VERSION ""

NS_ :

BS_:

BU_: ECM

BO_ 992 VIN: 8 ECM
 SG_ VIN_MSG : 0|2@1+ (1,0) [0|0] "" Vector__XXX
 SG_ VIN_DATA : 15|56@0+ (1,0) [0|0] "" Vector__XXX

BO_ 464 ORC_A1: 8 Vector__XXX
 SG_ DRV_SEATBELT : 16|2@1+ (1,0) [0|0] "" ECM
 SG_ DrvSbltUnFltr : 13|3@1+ (1,0) [0|0] "" ECM

BO_ 466 ORC_A2: 2 Vector__XXX
 SG_ Impact_Tgl : 7|1@1+ (1,0) [0|0] "" ECM
 SG_ IMPACT_X : 15|1@1+ (1,0) [0|0] "" ECM

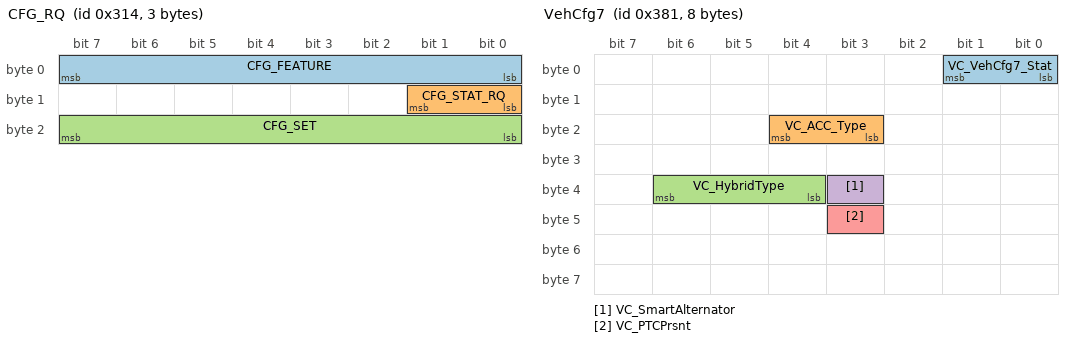
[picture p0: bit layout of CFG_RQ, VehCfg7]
BO_ 788 CFG_RQ: 3 Vector__XXX
 SG_ CFG_FEATURE : 0|8@1+ (1,0) [0|0] "" ECM
 SG_ CFG_STAT_RQ : 8|2@1+ (1,0) [0|0] "" ECM
 SG_ CFG_SET : 16|8@1+ (1,0) [0|255] "" ECM

BO_ 792 StW_Actn_Rq: 8 Vector__XXX
 SG_ WprWash_R_Sw_Posn_V3 : 8|2@1+ (1,0) [0|0] "" ECM

BO_ 850 ECM_APPL2: 8 Vector__XXX
 SG_ ECM_APPL2 : 7|64@0+ (1,0) [0|0] "" ECM

BO_ 864 ECM_APPL1: 8 ECM
 SG_ ECM_APPL1 : 7|64@0+ (1,0) [0|0] "" Vector__XXX

BO_ 880 ECM_APPL3: 8 ECM
 SG_ ECM_APPL3 : 7|64@0+ (1,0) [0|0] "" Vector__XXX

BO_ 896 ECM_APPL4: 8 ECM
 SG_ ECM_APPL4 : 7|64@0+ (1,0) [0|0] "" Vector__XXX

BO_ 897 VehCfg7: 8 Vector__XXX
 SG_ VC_VehCfg7_Stat : 0|2@1+ (1,0) [0|0] "" ECM
 SG_ VC_ACC_Type : 19|2@1+ (1,0) [0|0] "" ECM
 SG_ VC_HybridType : 36|3@1+ (1,0) [0|0] "" ECM
 SG_ VC_SmartAlternator : 35|1@1+ (1,0) [0|0] "" ECM
 SG_ VC_PTCPrsnt : 43|1@1+ (1,0) [0|0] "" ECM

BO_ 912 ECM_APPL5: 8 ECM
 SG_ ECM_APPL5 : 7|64@0+ (1,0) [0|0] "" Vector__XXX

BO_ 928 ECM_APPL6: 8 ECM
 SG_ ECM_APPL6 : 7|64@0+ (1,0) [0|0] "" Vector__XXX

BO_ 936 ECM_APPL7: 8 ECM
 SG_ ECM_APPL7 : 7|64@0+ (1,0) [0|0] "" Vector__XXX

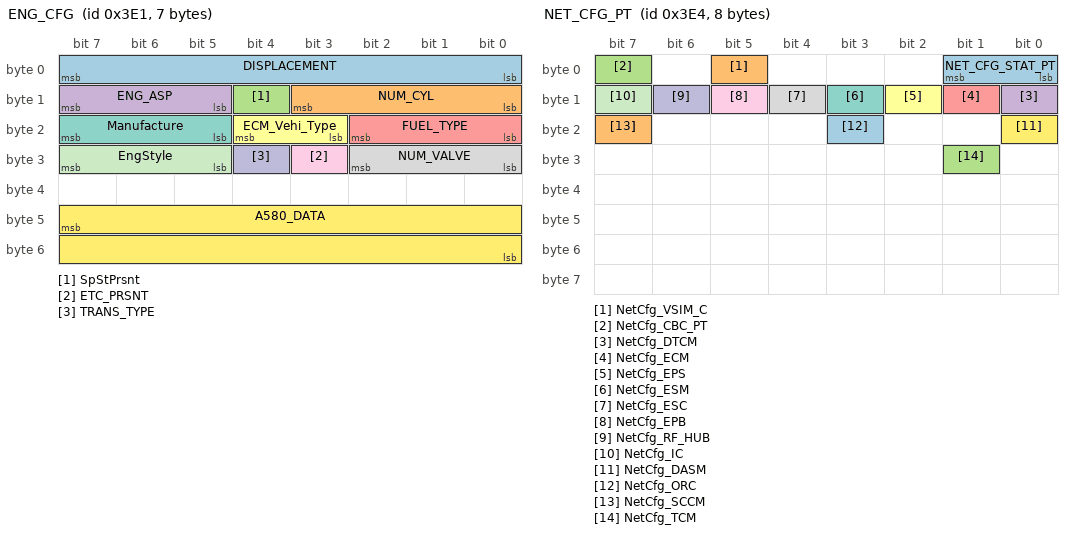
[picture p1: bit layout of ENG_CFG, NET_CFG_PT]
BO_ 993 ENG_CFG: 7 ECM
 SG_ DISPLACEMENT : 0|8@1+ (0.1,0) [0|25] "liters"  Vector__XXX
 SG_ NUM_CYL : 8|4@1+ (1,0) [0|14] "cylinders"  Vector__XXX
 SG_ SpStPrsnt : 12|1@1+ (1,0) [0|0] "" Vector__XXX
 SG_ ENG_ASP : 13|3@1+ (1,0) [0|0] "" Vector__XXX
 SG_ FUEL_TYPE : 16|3@1+ (1,0) [0|0] "" Vector__XXX
 SG_ ECM_Vehi_Type : 19|2@1+ (1,0) [0|0] "" Vector__XXX
 SG_ Manufacture : 21|3@1+ (1,0) [0|0] "" Vector__XXX
 SG_ NUM_VALVE : 24|3@1+ (1,0) [0|6] "valve-per-cylinder"  Vector__XXX
 SG_ ETC_PRSNT : 27|1@1+ (1,0) [0|0] "" Vector__XXX
 SG_ TRANS_TYPE : 28|1@1+ (1,0) [0|0] "" Vector__XXX
 SG_ EngStyle : 29|3@1+ (1,0) [0|0] "" Vector__XXX
 SG_ A580_DATA : 47|16@0+ (1,0) [0|0] "" Vector__XXX

BO_ 995 NET_CFG_INT: 8 Vector__XXX
 SG_ NET_CFG_STAT_INT : 0|2@1+ (1,0) [0|0] "" ECM

BO_ 996 NET_CFG_PT: 8 Vector__XXX
 SG_ NET_CFG_STAT_PT : 0|2@1+ (1,0) [0|0] "" ECM
 SG_ NetCfg_VSIM_C : 5|1@1+ (1,0) [0|0] "" ECM
 SG_ NetCfg_CBC_PT : 7|1@1+ (1,0) [0|0] "" ECM
 SG_ NetCfg_DTCM : 8|1@1+ (1,0) [0|0] "" ECM
 SG_ NetCfg_ECM : 9|1@1+ (1,0) [0|0] "" ECM
 SG_ NetCfg_EPS : 10|1@1+ (1,0) [0|0] "" ECM
 SG_ NetCfg_ESM : 11|1@1+ (1,0) [0|0] "" ECM
 SG_ NetCfg_ESC : 12|1@1+ (1,0) [0|0] "" ECM
 SG_ NetCfg_EPB : 13|1@1+ (1,0) [0|0] "" ECM
 SG_ NetCfg_RF_HUB : 14|1@1+ (1,0) [0|0] "" ECM
 SG_ NetCfg_IC : 15|1@1+ (1,0) [0|0] "" ECM
 SG_ NetCfg_DASM : 16|1@1+ (1,0) [0|0] "" ECM
 SG_ NetCfg_ORC : 19|1@1+ (1,0) [0|0] "" ECM
 SG_ NetCfg_SCCM : 23|1@1+ (1,0) [0|0] "" ECM
 SG_ NetCfg_TCM : 25|1@1+ (1,0) [0|0] "" ECM

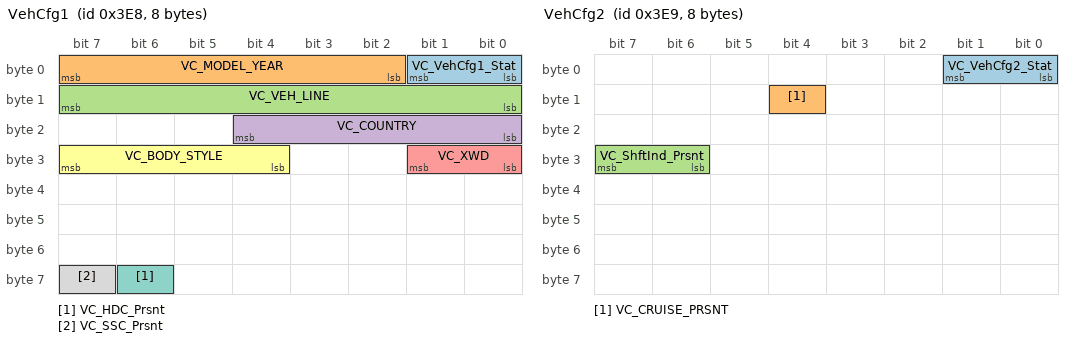
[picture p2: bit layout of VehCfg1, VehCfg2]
BO_ 1000 VehCfg1: 8 Vector__XXX
 SG_ VC_VehCfg1_Stat : 0|2@1+ (1,0) [0|0] "" ECM
 SG_ VC_MODEL_YEAR : 2|6@1+ (1,2000) [2000|2062] "model-year"  ECM
 SG_ VC_VEH_LINE : 8|8@1+ (1,0) [0|0] "" ECM
 SG_ VC_COUNTRY : 16|5@1+ (1,0) [0|0] "" ECM
 SG_ VC_XWD : 24|2@1+ (1,0) [0|0] "" ECM
 SG_ VC_BODY_STYLE : 28|4@1+ (1,0) [0|0] "" ECM
 SG_ VC_HDC_Prsnt : 62|1@1+ (1,0) [0|0] "" ECM
 SG_ VC_SSC_Prsnt : 63|1@1+ (1,0) [0|0] "" ECM

BO_ 1001 VehCfg2: 8 Vector__XXX
 SG_ VC_VehCfg2_Stat : 0|2@1+ (1,0) [0|0] "" ECM
 SG_ VC_CRUISE_PRSNT : 12|1@1+ (1,0) [0|0] "" ECM
 SG_ VC_ShftInd_Prsnt : 30|2@1+ (1,0) [0|0] "" ECM

BO_ 1002 VehCfg3: 8 Vector__XXX
 SG_ VC_VehCfg3_Stat : 0|2@1+ (1,0) [0|0] "" ECM

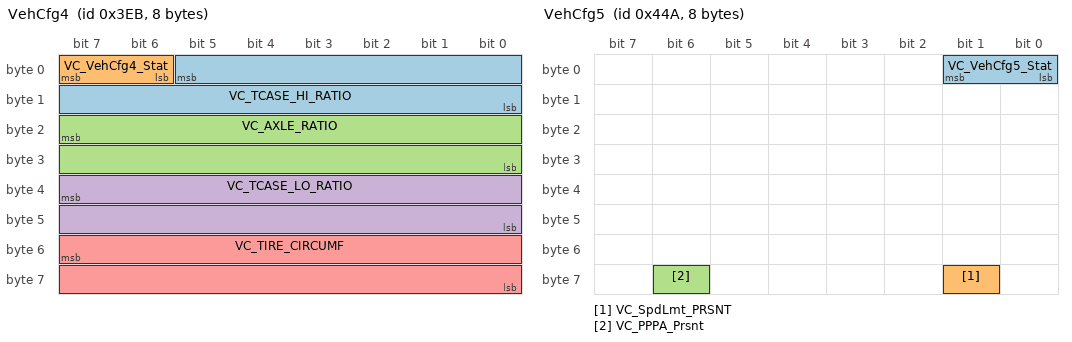
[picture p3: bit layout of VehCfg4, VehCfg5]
BO_ 1003 VehCfg4: 8 Vector__XXX
 SG_ VC_TCASE_HI_RATIO : 5|14@0+ (0.001,0) [0|16.382] "" ECM
 SG_ VC_VehCfg4_Stat : 6|2@1+ (1,0) [0|0] "" ECM
 SG_ VC_AXLE_RATIO : 23|16@0+ (0.001,0) [0|65.534] "" ECM
 SG_ VC_TCASE_LO_RATIO : 39|16@0+ (0.001,0) [0|65.534] "" ECM
 SG_ VC_TIRE_CIRCUMF : 55|16@0+ (1,0) [0|65534] "mm"  ECM

BO_ 1013 EcuCfg6: 8 Vector__XXX
 SG_ EC_ECUCfg6_Stat : 0|2@1+ (1,0) [0|0] "" ECM
 SG_ EC_Powertrain : 39|16@0+ (1,0) [0|0] "" ECM

BO_ 1089 DG_RQ_GLOBAL_UDS: 8 Vector__XXX
 SG_ DG_RQ_GLOBAL_UDS : 7|64@0+ (1,0) [0|0] "" ECM

BO_ 1098 VehCfg5: 8 Vector__XXX
 SG_ VC_VehCfg5_Stat : 0|2@1+ (1,0) [0|0] "" ECM
 SG_ VC_SpdLmt_PRSNT : 57|1@1+ (1,0) [0|0] "" ECM
 SG_ VC_PPPA_Prsnt : 62|1@1+ (1,0) [0|0] "" ECM

BO_ 1100 VehCfg6: 8 Vector__XXX
 SG_ VC_VehCfg6_Stat : 0|2@1+ (1,0) [0|0] "" ECM
 SG_ VC_AnlgDrSnsr : 2|2@1+ (1,0) [0|0] "" ECM

BO_ 1464 ECU_APPL_ECM: 8 ECM
 SG_ ECU_APPL_ECM : 7|64@0+ (1,0) [0|0] "" Vector__XXX

BO_ 1592 SD_RS_ECM: 8 ECM
 SG_ SD_RS_ECM : 7|64@0+ (1,0) [0|0] "" Vector__XXX

BO_ 1784 APPL_ECU_ECM: 8 Vector__XXX
 SG_ APPL_ECU_ECM : 7|64@0+ (1,0) [0|0] "" ECM

BO_ 2015 DG_RQ_GLOBAL: 8 Vector__XXX
 SG_ DG_RQ_GLOBAL : 7|64@0+ (1,0) [0|0] "" ECM

BO_ 2016 D_RQ_ECM: 8 Vector__XXX
 SG_ D_RQ_ECM : 7|64@0+ (1,0) [0|0] "" ECM

BO_ 2024 D_RS_ECM: 8 ECM
 SG_ D_RS_ECM : 7|64@0+ (1,0) [0|0] "" Vector__XXX

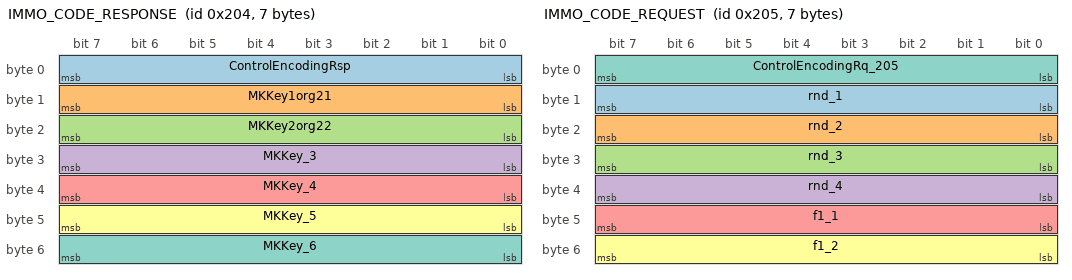
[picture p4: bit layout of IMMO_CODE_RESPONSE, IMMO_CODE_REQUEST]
BO_ 516 IMMO_CODE_RESPONSE: 7 Vector__XXX
 SG_ ControlEncodingRsp : 0|8@1+ (1,0) [0|0] "" ECM
 SG_ MKKey1org21 : 8|8@1+ (1,0) [0|255] "" ECM
 SG_ MKKey2org22 : 16|8@1+ (1,0) [0|255] "" ECM
 SG_ MKKey_3 : 24|8@1+ (1,0) [0|255] "" ECM
 SG_ MKKey_4 : 32|8@1+ (1,0) [0|255] "" ECM
 SG_ MKKey_5 : 40|8@1+ (1,0) [0|255] "" ECM
 SG_ MKKey_6 : 48|8@1+ (1,0) [0|255] "" ECM

BO_ 517 IMMO_CODE_REQUEST: 7 ECM
 SG_ rnd_1 : 8|8@1+ (1,0) [0|255] "" Vector__XXX
 SG_ rnd_2 : 16|8@1+ (1,0) [0|255] "" Vector__XXX
 SG_ rnd_3 : 24|8@1+ (1,0) [0|255] "" Vector__XXX
 SG_ rnd_4 : 32|8@1+ (1,0) [0|255] "" Vector__XXX
 SG_ f1_1 : 40|8@1+ (1,0) [0|255] "" Vector__XXX
 SG_ f1_2 : 48|8@1+ (1,0) [0|255] "" Vector__XXX
 SG_ ControlEncodingRq_205 : 0|8@1+ (1,0) [0|0] "" Vector__XXX

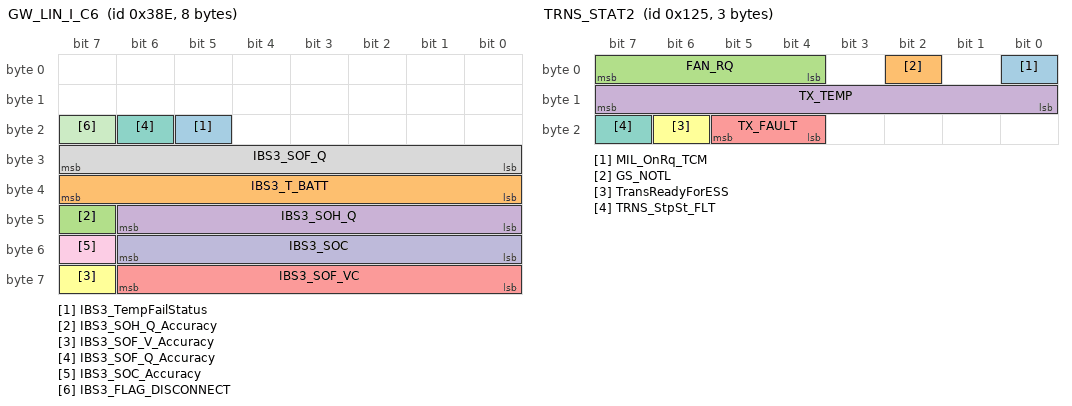
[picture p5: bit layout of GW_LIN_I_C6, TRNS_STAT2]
BO_ 910 GW_LIN_I_C6: 8 Vector__XXX
 SG_ IBS3_TempFailStatus : 21|1@1+ (1,0) [0|0] "" ECM
 SG_ IBS3_T_BATT : 32|8@1+ (1,-40) [-40|105] "°C"  ECM
 SG_ IBS3_SOH_Q_Accuracy : 47|1@1+ (1,0) [0|0] "" ECM
 SG_ IBS3_SOH_Q : 40|7@1+ (2,0) [0|252] "Ah"  ECM
 SG_ IBS3_SOF_VC : 56|7@1+ (0.05,5) [5|11.3] "V"  ECM
 SG_ IBS3_SOF_V_Accuracy : 63|1@1+ (1,0) [0|0] "" ECM
 SG_ IBS3_SOF_Q_Accuracy : 22|1@1+ (1,0) [0|0] "" ECM
 SG_ IBS3_SOF_Q : 24|8@1+ (1,0) [0|254] "Ah"  ECM
 SG_ IBS3_SOC_Accuracy : 55|1@1+ (1,0) [0|0] "" ECM
 SG_ IBS3_SOC : 48|7@1+ (1,0) [0|100] "%"  ECM
 SG_ IBS3_FLAG_DISCONNECT : 23|1@1+ (1,0) [0|0] "" ECM

BO_ 976 ECM_A4: 8 ECM
 SG_ PF_WARN_MSG : 24|3@1+ (1,0) [0|0] "" Vector__XXX
 SG_ KNK_MG_TRIGGER : 29|2@1+ (1,0) [0|0] "" Vector__XXX

BO_ 47 WHEEL_SPEED_2: 8 Vector__XXX
 SG_ BrkPdlRawStat : 33|10@0+ (0.0048828125,0) [0|4.9951171875] "Volts"  ECM
 SG_ RAW_OBD_VEHACCEL_X : 48|8@1+ (0.08,-10.24) [-10.24|10.16] "m/s²"  ECM

BO_ 293 TRNS_STAT2: 3 Vector__XXX
 SG_ MIL_OnRq_TCM : 0|1@1+ (1,0) [0|0] "" ECM
 SG_ GS_NOTL : 2|1@1+ (1,0) [0|0] "" ECM
 SG_ FAN_RQ : 4|4@1+ (7.2,0) [0|100] "%"  ECM
 SG_ TX_TEMP : 8|8@1+ (1,-50) [-50|204] "°C"  ECM
 SG_ TX_FAULT : 20|2@1+ (1,0) [0|0] "" ECM
 SG_ TransReadyForESS : 22|1@1+ (1,0) [0|0] "" ECM
 SG_ TRNS_StpSt_FLT : 23|1@1+ (1,0) [0|0] "" ECM

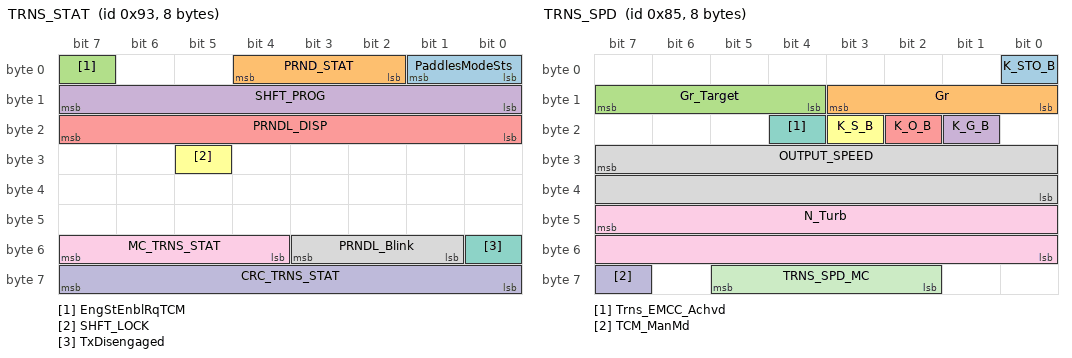
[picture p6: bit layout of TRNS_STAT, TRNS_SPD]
BO_ 147 TRNS_STAT: 8 Vector__XXX
 SG_ PaddlesModeSts : 0|2@1+ (1,0) [0|0] "" Vector__XXX
 SG_ PRND_STAT : 2|3@1+ (1,0) [0|0] "" ECM
 SG_ EngStEnblRqTCM : 7|1@1+ (1,0) [0|0] "" ECM
 SG_ SHFT_PROG : 8|8@1+ (1,0) [0|0] "" ECM
 SG_ PRNDL_DISP : 16|8@1+ (1,0) [0|0] "" ECM
 SG_ SHFT_LOCK : 29|1@1+ (1,0) [0|0] "" Vector__XXX
 SG_ TxDisengaged : 48|1@1+ (1,0) [0|0] "" ECM
 SG_ PRNDL_Blink : 49|3@1+ (1,0) [0|0] "" Vector__XXX
 SG_ MC_TRNS_STAT : 52|4@1+ (1,0) [0|15] "" ECM
 SG_ CRC_TRNS_STAT : 56|8@1+ (1,0) [0|0] "" ECM

BO_ 133 TRNS_SPD: 8 Vector__XXX
 SG_ K_STO_B : 0|1@1+ (1,0) [0|0] "" ECM
 SG_ Gr : 8|4@1+ (1,0) [0|0] "" ECM
 SG_ Gr_Target : 12|4@1+ (1,0) [0|0] "" ECM
 SG_ K_G_B : 17|1@1+ (1,0) [0|0] "" ECM
 SG_ K_O_B : 18|1@1+ (1,0) [0|0] "" ECM
 SG_ K_S_B : 19|1@1+ (1,0) [0|0] "" ECM
 SG_ Trns_EMCC_Achvd : 20|1@1+ (1,0) [0|0] "" ECM
 SG_ OUTPUT_SPEED : 31|16@0+ (1,0) [0|65534] "rpm"  ECM
 SG_ N_Turb : 47|16@0+ (1,0) [0|65534] "rpm"  ECM
 SG_ TCM_ManMd : 63|1@1+ (1,0) [0|0] "" ECM
 SG_ TRNS_SPD_MC : 58|4@1+ (1,0) [0|15] "" ECM

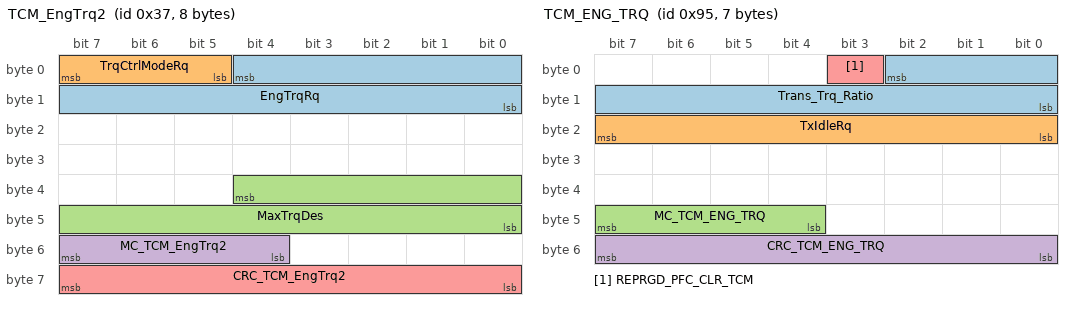
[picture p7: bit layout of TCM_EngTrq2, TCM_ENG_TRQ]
BO_ 55 TCM_EngTrq2: 8 Vector__XXX
 SG_ EngTrqRq : 4|13@0+ (0.25,-500) [-500|1547.5] "Nm"  ECM
 SG_ TrqCtrlModeRq : 5|3@1+ (1,0) [0|0] "" ECM
 SG_ MaxTrqDes : 36|13@0+ (0.25,-500) [-500|1547.5] "Nm"  ECM
 SG_ MC_TCM_EngTrq2 : 52|4@1+ (1,0) [0|15] "" ECM
 SG_ CRC_TCM_EngTrq2 : 56|8@1+ (1,0) [0|0] "" ECM

BO_ 149 TCM_ENG_TRQ: 7 Vector__XXX
 SG_ Trans_Trq_Ratio : 2|11@0+ (0.01,0) [0|20.46] "" ECM
 SG_ TxIdleRq : 16|8@1+ (4,500) [500|1516] "rpm"  ECM
 SG_ MC_TCM_ENG_TRQ : 44|4@1+ (1,0) [0|15] "" ECM
 SG_ CRC_TCM_ENG_TRQ : 48|8@1+ (1,0) [0|0] "" ECM
 SG_ REPRGD_PFC_CLR_TCM : 3|1@1+ (1,0) [0|0] "" ECM

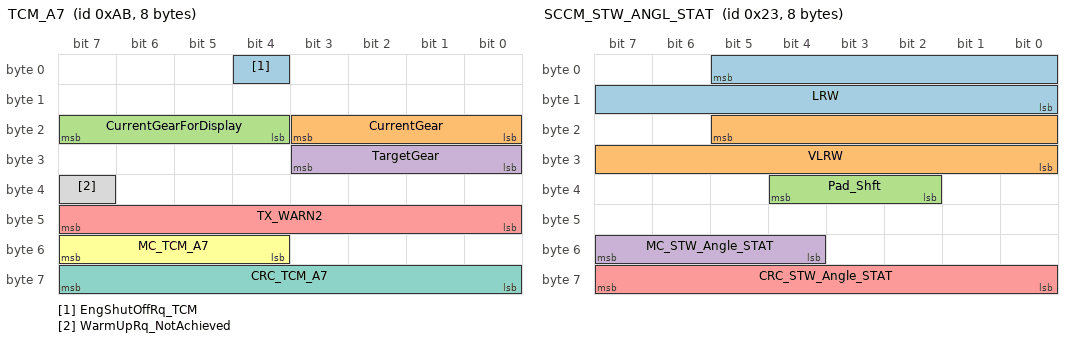
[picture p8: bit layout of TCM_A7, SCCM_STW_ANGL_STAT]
BO_ 171 TCM_A7: 8 Vector__XXX
 SG_ EngShutOffRq_TCM : 4|1@1+ (1,0) [0|0] "" ECM
 SG_ CurrentGear : 16|4@1+ (1,0) [0|0] "" ECM
 SG_ CurrentGearForDisplay : 20|4@1+ (1,0) [0|0] "" Vector__XXX
 SG_ TargetGear : 24|4@1+ (1,0) [0|0] "" ECM
 SG_ TX_WARN2 : 40|8@1+ (1,0) [0|0] "" Vector__XXX
 SG_ MC_TCM_A7 : 52|4@1+ (1,0) [0|15] "" ECM
 SG_ CRC_TCM_A7 : 56|8@1+ (1,0) [0|0] "" ECM
 SG_ WarmUpRq_NotAchieved : 39|1@1+ (1,0) [0|0] "" ECM

BO_ 35 SCCM_STW_ANGL_STAT: 8 Vector__XXX
 SG_ LRW : 5|14@0+ (0.5,-2048) [-2048|2047] "Degrees"  ECM
 SG_ VLRW : 21|14@0+ (0.5,-2048) [-2048|2047] "°/s"  ECM
 SG_ Pad_Shft : 34|3@1+ (1,0) [0|0] "" ECM
 SG_ MC_STW_Angle_STAT : 52|4@1+ (1,0) [0|15] "" ECM
 SG_ CRC_STW_Angle_STAT : 56|8@1+ (1,0) [0|0] "" ECM

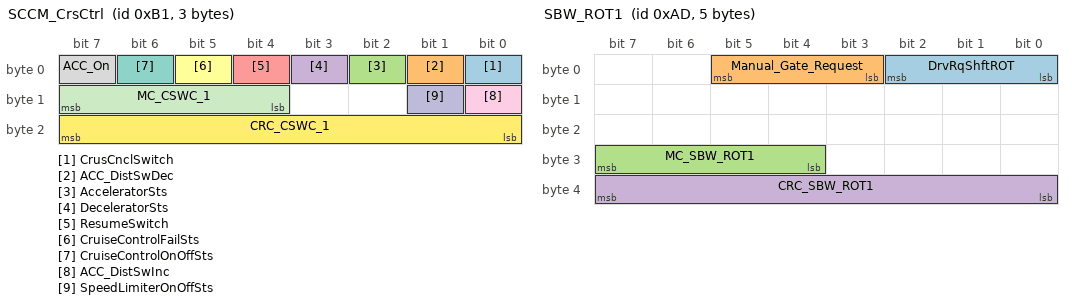
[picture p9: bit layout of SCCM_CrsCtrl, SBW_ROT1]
BO_ 177 SCCM_CrsCtrl: 3 Vector__XXX
 SG_ CrusCnclSwitch : 0|1@1+ (1,0) [0|0] "" ECM
 SG_ ACC_DistSwDec : 1|1@1+ (1,0) [0|0] "" ECM
 SG_ AcceleratorSts : 2|1@1+ (1,0) [0|0] "" ECM
 SG_ DeceleratorSts : 3|1@1+ (1,0) [0|0] "" ECM
 SG_ ResumeSwitch : 4|1@1+ (1,0) [0|0] "" ECM
 SG_ CruiseControlFailSts : 5|1@1+ (1,0) [0|0] "" ECM
 SG_ CruiseControlOnOffSts : 6|1@1+ (1,0) [0|0] "" ECM
 SG_ ACC_On : 7|1@1+ (1,0) [0|0] "" ECM
 SG_ ACC_DistSwInc : 8|1@1+ (1,0) [0|0] "" ECM
 SG_ SpeedLimiterOnOffSts : 9|1@1+ (1,0) [0|0] "" ECM
 SG_ MC_CSWC_1 : 12|4@1+ (1,0) [0|15] "" ECM
 SG_ CRC_CSWC_1 : 16|8@1+ (1,0) [0|0] "" ECM

BO_ 173 SBW_ROT1: 5 Vector__XXX
 SG_ DrvRqShftROT : 0|3@1+ (1,0) [0|0] "" ECM
 SG_ Manual_Gate_Request : 3|3@1+ (1,0) [0|0] "" ECM
 SG_ MC_SBW_ROT1 : 28|4@1+ (1,0) [0|15] "" ECM
 SG_ CRC_SBW_ROT1 : 32|8@1+ (1,0) [0|0] "" ECM

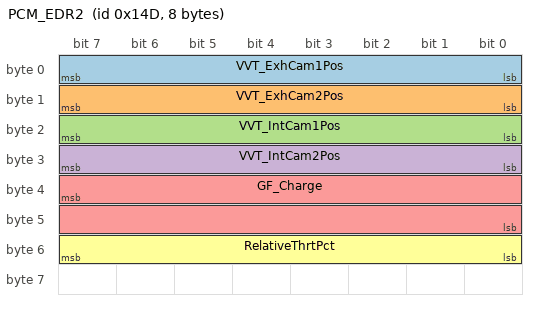
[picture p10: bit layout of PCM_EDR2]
BO_ 333 PCM_EDR2: 8 ECM
 SG_ VVT_ExhCam1Pos : 0|8@1+ (1,0) [1|255] "Degrees"  Vector__XXX
 SG_ VVT_ExhCam2Pos : 8|8@1+ (1,0) [1|255] "Degrees"  Vector__XXX
 SG_ VVT_IntCam1Pos : 16|8@1+ (1,0) [1|255] "Degrees"  Vector__XXX
 SG_ VVT_IntCam2Pos : 24|8@1+ (1,0) [1|255] "Degrees"  Vector__XXX
 SG_ GF_Charge : 39|16@0+ (0.2,0) [0|13106.8] "mg/cycle/cyl"  Vector__XXX
 SG_ RelativeThrtPct : 48|8@1+ (0.4,0) [0|100] "%"  Vector__XXX

CM_ "Excel Convert to DBC - Written by Vector CANtech, Inc. 2016";
CM_ SG_ 2016 D_RQ_ECM "Diagnostic-Request";
CM_ SG_ 2015 DG_RQ_GLOBAL "Diagnostic-Request";
CM_ SG_ 1784 APPL_ECU_ECM "External Application to ECU";
CM_ SG_ 1100 VC_AnlgDrSnsr "Analog door sensor configuration";
CM_ SG_ 1100 VC_VehCfg6_Stat "Configuration messages status 6";
CM_ SG_ 1098 VC_PPPA_Prsnt "Semi automatic parking system present; present = [1]";
CM_ SG_ 1098 VC_SpdLmt_PRSNT "Speed limiter is present; present = [1]";
CM_ SG_ 1098 VC_VehCfg5_Stat "Configuration messages status 5";
CM_ SG_ 1089 DG_RQ_GLOBAL_UDS "Diagnostic-Request";
CM_ SG_ 1013 EC_Powertrain "Powertrain ecu configuration";
CM_ SG_ 1013 EC_ECUCfg6_Stat "ECU Configuration messages status 6";
CM_ SG_ 1003 VC_TIRE_CIRCUMF "Dynamic tire circumference (all or rear)";
CM_ SG_ 1003 VC_TCASE_LO_RATIO "Transfer case low range reduction ratio";
CM_ SG_ 1003 VC_AXLE_RATIO "Axle ratio";
CM_ SG_ 1003 VC_VehCfg4_Stat "Configuration messages status 4";
CM_ SG_ 1003 VC_TCASE_HI_RATIO "Transfer case high ratio";
CM_ SG_ 1002 VC_VehCfg3_Stat "Configuration messages status 3";
CM_ SG_ 1001 VC_ShftInd_Prsnt "Configuration for performance & gear shift indication";
CM_ SG_ 1001 VC_CRUISE_PRSNT "Cruise feature is present; present = [1]";
CM_ SG_ 1001 VC_VehCfg2_Stat "Configuration messages status 2";
CM_ SG_ 1000 VC_SSC_Prsnt "Select speed control feature is present; present = [1]";
CM_ SG_ 1000 VC_HDC_Prsnt "Hill descent feature is present; present = [1]";
CM_ SG_ 1000 VC_BODY_STYLE "Body style";
CM_ SG_ 1000 VC_XWD "Drive configuration";
CM_ SG_ 1000 VC_COUNTRY "Country Code";
CM_ SG_ 1000 VC_VEH_LINE "Vehicle line";
CM_ SG_ 1000 VC_MODEL_YEAR "Model year";
CM_ SG_ 1000 VC_VehCfg1_Stat "Configuration messages status 1";
CM_ SG_ 996 NetCfg_DASM "Driver Assistance System Module (1=present)";
CM_ SG_ 996 NetCfg_IC "Instrument Cluster (1=present)";
CM_ SG_ 996 NetCfg_RF_HUB "RF Hub Node (1=present)";
CM_ SG_ 996 NetCfg_EPB "Electric Park Brake Module (1=present)";
CM_ SG_ 996 NetCfg_ESC "Electronic Stability Module / Anti-Lock Brake (1=present)";
CM_ SG_ 996 NetCfg_ESM "Electronic Shift Module (1=present)";
CM_ SG_ 996 NetCfg_TCM "Automatic Transmission Controller (1=present)";
CM_ SG_ 996 NetCfg_SCCM "Steering Column Control Module (1=present)";
CM_ SG_ 996 NetCfg_ORC "Occupant Restraint Controller (1=present)";
CM_ SG_ 996 NetCfg_EPS "Electric Power Steering (1=present)";
CM_ SG_ 996 NetCfg_ECM "Engine Control Module (1=present)";
CM_ SG_ 996 NetCfg_DTCM "Drivetrain Control Module (1=present)";
CM_ SG_ 996 NetCfg_CBC_PT "Common Body Controller PT Bus (1=present)";
CM_ SG_ 996 NetCfg_VSIM_C "Vehicle System Interface Module (1=present)";
CM_ SG_ 996 NET_CFG_STAT_PT "Network configuration status";
CM_ SG_ 995 NET_CFG_STAT_INT "Network configuration status";
CM_ SG_ 910 IBS3_FLAG_DISCONNECT "Battery disconnection flag";
CM_ SG_ 910 IBS3_SOC "State of charge";
CM_ SG_ 910 IBS3_SOC_Accuracy "SOC accuracy status";
CM_ SG_ 910 IBS3_SOF_Q "Residual battery charge in Ah";
CM_ SG_ 910 IBS3_SOF_Q_Accuracy "SOF_Q accuracy status";
CM_ SG_ 910 IBS3_SOF_V_Accuracy "SOF_V accuracy; Data reliable = [0], unreliable = [1]";
CM_ SG_ 910 IBS3_SOF_VC "Predicted initial battery voltage dip during cranking (old CG spec)";
CM_ SG_ 910 IBS3_SOH_Q "State of health related to capacity (energy)";
CM_ SG_ 910 IBS3_SOH_Q_Accuracy "SOH_Q accuracy status";
CM_ SG_ 910 IBS3_T_BATT "Battery temperature";
CM_ SG_ 910 IBS3_TempFailStatus "Failure of ASIC Temperature meas. (internal defect)";
CM_ SG_ 897 VC_PTCPrsnt "PTC Present/Absent;  Present = 1";
CM_ SG_ 897 VC_SmartAlternator "Smart alternator is present; True = [1]";
CM_ SG_ 897 VC_HybridType "Identify the kind of hybrid vehicle";
CM_ SG_ 897 VC_ACC_Type "Type of adaptive cruise control (ACC) system present";
CM_ SG_ 897 VC_VehCfg7_Stat "Configuration messages status 7";
CM_ SG_ 850 ECM_APPL2 "Application";
CM_ SG_ 792 WprWash_R_Sw_Posn_V3 "Backlite wiper/washer switch position";
CM_ SG_ 788 CFG_SET "Specific setting or value (see reference)";
CM_ SG_ 788 CFG_STAT_RQ "Configurable feature status request";
CM_ SG_ 788 CFG_FEATURE "Configurable feature";
CM_ SG_ 516 MKKey2org22 "Mini kript key 2 or G2_2";
CM_ SG_ 516 MKKey1org21 "Mini kript key 1 or G2_1";
CM_ SG_ 516 ControlEncodingRsp "Control encoding - response";
CM_ SG_ 516 MKKey_6 "Mini kript key 6";
CM_ SG_ 516 MKKey_5 "Mini kript key 5";
CM_ SG_ 516 MKKey_4 "Mini kript key 4";
CM_ SG_ 516 MKKey_3 "Mini kript key 3";
CM_ SG_ 466 IMPACT_X "Any impact event; actuate = [1]; do_not_actuate = [0]";
CM_ SG_ 466 Impact_Tgl "Toggle bit for all impact events; See Signal Description Document";
CM_ SG_ 464 DrvSbltUnFltr "Drivers seat belt fault status - unfiltered";
CM_ SG_ 464 DRV_SEATBELT "Drivers seat belt status";
CM_ SG_ 293 TRNS_StpSt_FLT "Trans stop start fault (1=fault)";
CM_ SG_ 293 TransReadyForESS "Trans ready for auto stop (0= not ready)";
CM_ SG_ 293 TX_FAULT "Transmission fault";
CM_ SG_ 293 TX_TEMP "Transmission fluid temperature";
CM_ SG_ 293 FAN_RQ "Cooling fan request";
CM_ SG_ 293 GS_NOTL "TRANS in limp home mode";
CM_ SG_ 293 MIL_OnRq_TCM "MIL on request from the transmission";
CM_ SG_ 177 CRC_CSWC_1 "CRC-checksum byte 1 to 2 according to SAE J1850";
CM_ SG_ 177 MC_CSWC_1 "Message counter";
CM_ SG_ 177 SpeedLimiterOnOffSts "Cruise Switch:Speed Limiter On/Off Pressed";
CM_ SG_ 177 ACC_DistSwInc "Cruise Switch: Distance Increase pressed";
CM_ SG_ 177 ACC_On "Cruise Switch: ACC or ESC mode pressed";
CM_ SG_ 177 CruiseControlOnOffSts "Cruise Switch: On/Off  Pressed";
CM_ SG_ 177 CruiseControlFailSts "Cruise Switch: Implausible State=1";
CM_ SG_ 177 ResumeSwitch "Cruise Switch: Resume Pressed";
CM_ SG_ 177 DeceleratorSts "Cruise Switch: Coast or Set/Decel Pressed";
CM_ SG_ 177 AcceleratorSts "Cruise Switch: Set/Accel Pressed";
CM_ SG_ 177 ACC_DistSwDec "Cruise Switch: Distance Decrease pressed";
CM_ SG_ 177 CrusCnclSwitch "Cruise Switch: Cancel Pressed";
CM_ SG_ 173 CRC_SBW_ROT1 "CRC-checksum byte 1 to 4 according to SAE J1850";
CM_ SG_ 173 MC_SBW_ROT1 "Message counter";
CM_ SG_ 173 Manual_Gate_Request "Manual gate request";
CM_ SG_ 173 DrvRqShftROT "Driver requested gear shift position";
CM_ SG_ 149 REPRGD_PFC_CLR_TCM "Set readiness to 'incomplete'; 0 = Do nothing; 1= Set incomplete";
CM_ SG_ 149 CRC_TCM_ENG_TRQ "CRC-checksum byte 1 to 6 according to SAE J1850";
CM_ SG_ 149 MC_TCM_ENG_TRQ "Message counter";
CM_ SG_ 149 TxIdleRq "Transmission idle speed request";
CM_ SG_ 149 Trans_Trq_Ratio "Transmission torque ratio";
CM_ SG_ 133 TRNS_SPD_MC "TRNS_SPD message counter";
CM_ SG_ 133 TCM_ManMd "Transmission in manual mode";
CM_ SG_ 133 N_Turb "Unfiltered turbine speed (n_t_v)";
CM_ SG_ 133 OUTPUT_SPEED "Output Shaft Speed";
CM_ SG_ 133 Trns_EMCC_Achvd "Trans A/C Converter Clutch Slipping; [1] = True";
CM_ SG_ 133 K_S_B "Conf. (torque converter lock-up) clutch 'slip'";
CM_ SG_ 133 K_O_B "Conf. (torque converter lock-up) clutch 'open'";
CM_ SG_ 133 K_G_B "Conf. (torque converter lock-up) clutch 'closed'";
CM_ SG_ 133 Gr_Target "Target Gear";
CM_ SG_ 133 Gr "Current Gear";
CM_ SG_ 133 K_STO_B "Conf. (torque converter lock-up) clutch 'starts to open'";
CM_ SG_ 55 CRC_TCM_EngTrq2 "CRC-checksum byte 1 to 7 according to SAE J1850";
CM_ SG_ 55 MC_TCM_EngTrq2 "Message counter";
CM_ SG_ 55 MaxTrqDes "Maximum engine torque desired";
CM_ SG_ 55 TrqCtrlModeRq "Torque control mode request";
CM_ SG_ 55 EngTrqRq "Requested engine torque";
CM_ SG_ 47 RAW_OBD_VEHACCEL_X "Raw vehicle acceleration in the X direction";
CM_ SG_ 47 BrkPdlRawStat "Brake pedal state raw value";
CM_ SG_ 35 CRC_STW_Angle_STAT "CRC-checksum byte 1 to 7 according to SAE J1850";
CM_ SG_ 35 MC_STW_Angle_STAT "Message counter";
CM_ SG_ 35 Pad_Shft "Paddle Shift";
CM_ SG_ 35 VLRW "Delta steering wheel angle";
CM_ SG_ 35 LRW "Steering wheel angle";
CM_ SG_ 333 RelativeThrtPct "EDR ONLY - Relative throttle percent";
CM_ SG_ 333 GF_Charge "EDR ONLY - Port flow per cylinder per stroke";
CM_ SG_ 333 VVT_IntCam2Pos "EDR ONLY - Centerline position for intake cam on bank 2";
CM_ SG_ 333 VVT_IntCam1Pos "EDR ONLY - Centerline position for intake cam on bank 1";
CM_ SG_ 333 VVT_ExhCam2Pos "EDR ONLY - Centerline position for exhaust cam on bank 2";
CM_ SG_ 333 VVT_ExhCam1Pos "EDR ONLY - Centerline position for exhaust cam on bank 1";
CM_ SG_ 171 WarmUpRq_NotAchieved "Warm Up Request; 0- Achieved, 1- NOT_Achieved";
CM_ SG_ 171 CRC_TCM_A7 "CRC-checksum byte 1 to 7 according to SAE J1850";
CM_ SG_ 171 MC_TCM_A7 "Message counter";
CM_ SG_ 171 TX_WARN2 "Transmission warning #2";
CM_ SG_ 171 TargetGear "Target Gear - protected";
CM_ SG_ 171 CurrentGearForDisplay "Current Gear for display";
CM_ SG_ 171 CurrentGear "Current Gear";
CM_ SG_ 171 EngShutOffRq_TCM "TCM request engine shut off";
CM_ SG_ 147 CRC_TRNS_STAT "CRC-checksum byte 1 to 7 according to SAE J1850";
CM_ SG_ 147 MC_TRNS_STAT "Message counter";
CM_ SG_ 147 PRNDL_Blink "Request gear shift display indicator blink";
CM_ SG_ 147 TxDisengaged "Transmission disengaged";
CM_ SG_ 147 SHFT_LOCK "Shiftlock state locked; false = [1]";
CM_ SG_ 147 PRNDL_DISP "PRNDL display request";
CM_ SG_ 147 SHFT_PROG "Driving program display code";
CM_ SG_ 147 EngStEnblRqTCM "Engine start enable request from the transmission";
CM_ SG_ 147 PRND_STAT "PRND Status";
CM_ SG_ 147 PaddlesModeSts "Status of paddle functionality";
CM_ SG_ 976 KNK_MG_TRIGGER "engine is experiencing high levels of LSPI (mega-knock)";
CM_ SG_ 976 PF_WARN_MSG "Particulate Filter warning message status";
CM_ SG_ 517 f1_2 "F code 1_2";
CM_ SG_ 517 f1_1 "F code 1_1";
CM_ SG_ 517 rnd_4 "Random number 4";
CM_ SG_ 517 rnd_3 "Random number 3";
CM_ SG_ 517 rnd_2 "Random number 2";
CM_ SG_ 517 rnd_1 "Random number 1";
CM_ SG_ 517 ControlEncodingRq_205 "Control encoding - request";
CM_ SG_ 2024 D_RS_ECM "Diagnostic-Response";
CM_ SG_ 1592 SD_RS_ECM "Response on Event - light";
CM_ SG_ 1464 ECU_APPL_ECM "ECU to External Application";
CM_ SG_ 993 A580_DATA "A580 engine stored data and CRC";
CM_ SG_ 993 EngStyle "Engine output version";
CM_ SG_ 993 TRANS_TYPE "Transmission type; [0] = manual, [1] = automatic";
CM_ SG_ 993 ETC_PRSNT "Electronic throttle control";
CM_ SG_ 993 NUM_VALVE "Number of valves per cylinder";
CM_ SG_ 993 Manufacture "Engine manufacture";
CM_ SG_ 993 ECM_Vehi_Type "Engine vehicle type";
CM_ SG_ 993 FUEL_TYPE "Fuel type";
CM_ SG_ 993 ENG_ASP "Engine aspiration method";
CM_ SG_ 993 SpStPrsnt "Stop start feature present";
CM_ SG_ 993 NUM_CYL "Number of engine cylinders";
CM_ SG_ 993 DISPLACEMENT "Engine displacement";
CM_ SG_ 936 ECM_APPL7 "Application";
CM_ SG_ 928 ECM_APPL6 "CCP 80ms DAQ  (from ENGINE to external tool)";
CM_ SG_ 912 ECM_APPL5 "CCP 10ms DAQ  (from ENGINE to external tool)";
CM_ SG_ 896 ECM_APPL4 "CCP 5ms DAQ  (from ENGINE to external tool)";
CM_ SG_ 880 ECM_APPL3 "CCP synchronous - TDC event DAQ";
CM_ SG_ 864 ECM_APPL1 "Application";
CM_ SG_ 992 VIN_DATA "VIN Digits (8 bit ascii encoded) - see Signal Description Doc for details";
CM_ SG_ 992 VIN_MSG "VIN Message Information";
BA_DEF_ SG_ "RID" STRING ;
BA_DEF_ SG_ "GenSigTimeout_TCM" INT 0 65535;
BA_DEF_ SG_ "GenSigTimeout_TBM" INT 0 65535;
BA_DEF_ SG_ "GenSigTimeout_SCCM" INT 0 65535;
BA_DEF_ SG_ "GenSigTimeout_RF_HUB" INT 0 65535;
BA_DEF_ SG_ "GenSigTimeout_PTS" INT 0 65535;
BA_DEF_ SG_ "GenSigTimeout_ORC" INT 0 65535;
BA_DEF_ SG_ "GenSigTimeout_OCM" INT 0 65535;
BA_DEF_ SG_ "GenSigTimeout_IC" INT 0 65535;
BA_DEF_ SG_ "GenSigTimeout_ETM" INT 0 65535;
BA_DEF_ SG_ "GenSigTimeout_ESM" INT 0 65535;
BA_DEF_ SG_ "GenSigTimeout_ESL" INT 0 65535;
BA_DEF_ SG_ "GenSigTimeout_ESC" INT 0 65535;
BA_DEF_ SG_ "GenSigTimeout_EHPS" INT 0 65535;
BA_DEF_ SG_ "GenSigTimeout_DTCM" INT 0 65535;
BA_DEF_ SG_ "GenSigTimeout_DPDM" INT 0 65535;
BA_DEF_ SG_ "GenSigTimeout_CBC" INT 0 65535;
BA_DEF_ SG_ "GenSigTimeout_ASBS" INT 0 65535;
BA_DEF_ SG_ "GenSigTimeout_AHLM" INT 0 65535;
BA_DEF_ SG_ "GenSigStartValue" HEX 0 2147483648;
BA_DEF_ SG_ "GenSigSNA" STRING ;
BA_DEF_ SG_ "GenSigSendType" ENUM "cyclicX","spontanX","cyclicIfActiveX","spontanWithDelay","cyclicAndSpontanX","cyclicAndSpontanWithDelay","spontanWithRepitition","cyclicIfActiveAndSpontanWD","cyclicIfActiveFast","cyclicWithRepeatOnDemand","none";
BA_DEF_ SG_ "GenSigCycleTimeActive" INT 0 65535;
BA_DEF_ SG_ "GenSigCycleTime" INT 0 65535;
BA_DEF_ SG_ "FlexKomSigStartValue" STRING ;
BA_DEF_ SG_ "FlexKomSigStartPos" INT 0 63;
BA_DEF_ SG_ "FlexKomSigName" STRING ;
BA_DEF_ SG_ "FlexKomSigLaenge" INT 0 64;
BA_DEF_ SG_ "FlexKomSID" INT 0 2147483647;
BA_DEF_ SG_ "FlexKomIsMotorola" ENUM "nein","ja";
BA_DEF_ SG_ "FlexKomComment" STRING ;
BA_DEF_ BU_ "TpOwnSystemEcuNumber" HEX 0 255;
BA_DEF_ BU_ "TpNodeBaseAddress" HEX 0 65535;
BA_DEF_ BU_ "NWM-Stationsadresse" HEX 0 63;
BA_DEF_ BU_ "NWM-Knoten" ENUM "nein","ja";
BA_DEF_ "VersionYear" INT 0 99;
BA_DEF_ "VersionWeek" INT 0 53;
BA_DEF_ "Version" HEX 0 4080;
BA_DEF_ "SamplePointMin" FLOAT 0 100;
BA_DEF_ "SamplePointMax" FLOAT 0 100;
BA_DEF_ "NWM-Typ" ENUM "zentral (MB-W210)","dezentral (MB-OSAN)","keines","VAG-OSEK","BMW-OSEK","PAG-OSEK","DBAG-OSEK";
BA_DEF_ "NWM-Basisadresse" HEX 0 536870911;
BA_DEF_ "NmMessageCount" INT 0 64;
BA_DEF_ "NBTMin" INT 0 255;
BA_DEF_ "NBTMax" INT 0 255;
BA_DEF_ "Manufacturer" ENUM "DBAG","VAG","BWVAG","PAG","GM";
BA_DEF_ "Baudrate" INT 0 1000000;
BA_DEF_ BO_ "TpTxIndex" INT 0 99;
BA_DEF_ BO_ "NWM-Botschaft" ENUM "nein","ja";
BA_DEF_ BO_ "GenMsgStartValue" STRING ;
BA_DEF_ BO_ "GenMsgStartDelayTime" INT 0 65535;
BA_DEF_ BO_ "GenMsgSendType" ENUM "cyclicX","spontanX","cyclicIfActiveX","spontanWithDelay","cyclicAndSpontanX","cyclicAndSpontanWithDelay","spontanWithRepitition","cyclicIfActiveAndSpontanWD","cyclicIfActiveFast","cyclicWithRepeatOnDemand","none";
BA_DEF_ BO_ "GenMsgNrOfRepetitions" INT 0 65535;
BA_DEF_ BO_ "GenMsgDelayTime" INT 0 65535;
BA_DEF_ BO_ "GenMsgCycleTimeActive" INT 0 65535;
BA_DEF_ BO_ "GenMsgCycleTime" INT 0 65535;
BA_DEF_ BO_ "DiagState" ENUM "nein","ja";
BA_DEF_ BO_ "DiagResponse" ENUM "nein","ja";
BA_DEF_ BO_ "DiagRequest" ENUM "nein","ja";
BA_DEF_ BO_ "CanMsgMinLen" INT 0 8;
BA_DEF_ BO_ "App-Botschaft" ENUM "nein","ja";
BA_DEF_DEF_ "RID" "";
BA_DEF_DEF_ "GenSigTimeout_TCM" 0;
BA_DEF_DEF_ "GenSigTimeout_TBM" 0;
BA_DEF_DEF_ "GenSigTimeout_SCCM" 0;
BA_DEF_DEF_ "GenSigTimeout_RF_HUB" 0;
BA_DEF_DEF_ "GenSigTimeout_PTS" 0;
BA_DEF_DEF_ "GenSigTimeout_ORC" 0;
BA_DEF_DEF_ "GenSigTimeout_OCM" 0;
BA_DEF_DEF_ "GenSigTimeout_IC" 0;
BA_DEF_DEF_ "GenSigTimeout_ETM" 0;
BA_DEF_DEF_ "GenSigTimeout_ESM" 0;
BA_DEF_DEF_ "GenSigTimeout_ESL" 0;
BA_DEF_DEF_ "GenSigTimeout_ESC" 0;
BA_DEF_DEF_ "GenSigTimeout_EHPS" 0;
BA_DEF_DEF_ "GenSigTimeout_DTCM" 0;
BA_DEF_DEF_ "GenSigTimeout_DPDM" 0;
BA_DEF_DEF_ "GenSigTimeout_CBC" 0;
BA_DEF_DEF_ "GenSigTimeout_ASBS" 0;
BA_DEF_DEF_ "GenSigTimeout_AHLM" 0;
BA_DEF_DEF_ "GenSigStartValue" 0;
BA_DEF_DEF_ "GenSigSNA" "";
BA_DEF_DEF_ "GenSigSendType" "cyclicX";
BA_DEF_DEF_ "GenSigCycleTimeActive" 0;
BA_DEF_DEF_ "GenSigCycleTime" 0;
BA_DEF_DEF_ "FlexKomSigStartValue" "";
BA_DEF_DEF_ "FlexKomSigStartPos" 0;
BA_DEF_DEF_ "FlexKomSigName" "";
BA_DEF_DEF_ "FlexKomSigLaenge" 0;
BA_DEF_DEF_ "FlexKomSID" 0;
BA_DEF_DEF_ "FlexKomIsMotorola" "nein";
BA_DEF_DEF_ "FlexKomComment" "";
BA_DEF_DEF_ "TpOwnSystemEcuNumber" 0;
BA_DEF_DEF_ "TpNodeBaseAddress" 0;
BA_DEF_DEF_ "NWM-Stationsadresse" 0;
BA_DEF_DEF_ "NWM-Knoten" "nein";
BA_DEF_DEF_ "VersionYear" 1;
BA_DEF_DEF_ "VersionWeek" 1;
BA_DEF_DEF_ "Version" 1;
BA_DEF_DEF_ "SamplePointMin" 75;
BA_DEF_DEF_ "SamplePointMax" 81.25;
BA_DEF_DEF_ "NWM-Typ" "DBAG-OSEK";
BA_DEF_DEF_ "NWM-Basisadresse" 1024;
BA_DEF_DEF_ "NmMessageCount" 64;
BA_DEF_DEF_ "NBTMin" 10;
BA_DEF_DEF_ "NBTMax" 20;
BA_DEF_DEF_ "Manufacturer" "DBAG";
BA_DEF_DEF_ "Baudrate" 500000;
BA_DEF_DEF_ "TpTxIndex" 0;
BA_DEF_DEF_ "NWM-Botschaft" "nein";
BA_DEF_DEF_ "GenMsgStartValue" "";
BA_DEF_DEF_ "GenMsgStartDelayTime" 0;
BA_DEF_DEF_ "GenMsgSendType" "cyclicX";
BA_DEF_DEF_ "GenMsgNrOfRepetitions" 0;
BA_DEF_DEF_ "GenMsgDelayTime" 0;
BA_DEF_DEF_ "GenMsgCycleTimeActive" 0;
BA_DEF_DEF_ "GenMsgCycleTime" 0;
BA_DEF_DEF_ "DiagState" "nein";
BA_DEF_DEF_ "DiagResponse" "nein";
BA_DEF_DEF_ "DiagRequest" "nein";
BA_DEF_DEF_ "CanMsgMinLen" 0;
BA_DEF_DEF_ "App-Botschaft" "nein";
BA_ "GenMsgStartValue" BO_ 992 "0300000000000000h";
BA_ "GenMsgNrOfRepetitions" BO_ 992 2;
BA_ "GenMsgDelayTime" BO_ 992 20;
BA_ "GenMsgCycleTime" BO_ 992 100;
BA_ "GenMsgDelayTime" BO_ 464 20;
BA_ "GenMsgCycleTime" BO_ 464 1000;
BA_ "GenMsgStartValue" BO_ 464 "44E70F0F00070000h";
BA_ "GenMsgSendType" BO_ 464 5;
BA_ "GenMsgNrOfRepetitions" BO_ 464 2;
BA_ "GenMsgStartValue" BO_ 466 "0000h";
BA_ "GenMsgSendType" BO_ 466 2;
BA_ "GenMsgNrOfRepetitions" BO_ 466 2;
BA_ "GenMsgDelayTime" BO_ 466 20;
BA_ "GenMsgCycleTimeActive" BO_ 466 20;
BA_ "GenMsgStartValue" BO_ 788 "000000h";
BA_ "GenMsgSendType" BO_ 788 2;
BA_ "GenMsgNrOfRepetitions" BO_ 788 2;
BA_ "GenMsgDelayTime" BO_ 788 20;
BA_ "GenMsgCycleTimeActive" BO_ 788 50;
BA_ "GenMsgStartValue" BO_ 792 "000000000000FF00h";
BA_ "GenMsgSendType" BO_ 792 5;
BA_ "GenMsgNrOfRepetitions" BO_ 792 2;
BA_ "GenMsgDelayTime" BO_ 792 20;
BA_ "GenMsgCycleTime" BO_ 792 100;
BA_ "GenMsgStartValue" BO_ 850 "0000000000000000h";
BA_ "GenMsgSendType" BO_ 850 1;
BA_ "GenMsgNrOfRepetitions" BO_ 850 2;
BA_ "GenMsgDelayTime" BO_ 850 20;
BA_ "GenMsgStartValue" BO_ 864 "0000000000000000h";
BA_ "GenMsgSendType" BO_ 864 1;
BA_ "GenMsgNrOfRepetitions" BO_ 864 2;
BA_ "GenMsgDelayTime" BO_ 864 20;
BA_ "GenMsgStartValue" BO_ 880 "0000000000000000h";
BA_ "GenMsgSendType" BO_ 880 1;
BA_ "GenMsgNrOfRepetitions" BO_ 880 2;
BA_ "GenMsgDelayTime" BO_ 880 20;
BA_ "GenMsgStartValue" BO_ 896 "0000000000000000h";
BA_ "GenMsgSendType" BO_ 896 1;
BA_ "GenMsgNrOfRepetitions" BO_ 896 2;
BA_ "GenMsgDelayTime" BO_ 896 20;
BA_ "GenMsgStartValue" BO_ 897 "033F000000000000h";
BA_ "GenMsgSendType" BO_ 897 5;
BA_ "GenMsgNrOfRepetitions" BO_ 897 2;
BA_ "GenMsgDelayTime" BO_ 897 20;
BA_ "GenMsgCycleTime" BO_ 897 2000;
BA_ "GenMsgStartValue" BO_ 912 "0000000000000000h";
BA_ "GenMsgSendType" BO_ 912 1;
BA_ "GenMsgNrOfRepetitions" BO_ 912 2;
BA_ "GenMsgDelayTime" BO_ 912 20;
BA_ "GenMsgSendType" BO_ 928 1;
BA_ "GenMsgNrOfRepetitions" BO_ 928 2;
BA_ "GenMsgDelayTime" BO_ 928 20;
BA_ "GenMsgStartValue" BO_ 928 "0000000000000000h";
BA_ "GenMsgDelayTime" BO_ 936 20;
BA_ "GenMsgStartValue" BO_ 936 "0000000000000000h";
BA_ "GenMsgSendType" BO_ 936 1;
BA_ "GenMsgNrOfRepetitions" BO_ 936 2;
BA_ "GenMsgStartValue" BO_ 993 "FFEFE7E71F0000h";
BA_ "GenMsgNrOfRepetitions" BO_ 993 2;
BA_ "GenMsgDelayTime" BO_ 993 20;
BA_ "GenMsgCycleTime" BO_ 993 100;
BA_ "GenMsgStartValue" BO_ 995 "0300000000000000h";
BA_ "GenMsgStartDelayTime" BO_ 995 20;
BA_ "GenMsgSendType" BO_ 995 5;
BA_ "GenMsgNrOfRepetitions" BO_ 995 2;
BA_ "GenMsgDelayTime" BO_ 995 20;
BA_ "GenMsgCycleTime" BO_ 995 2000;
BA_ "GenMsgStartValue" BO_ 996 "0300000000000000h";
BA_ "GenMsgStartDelayTime" BO_ 996 10;
BA_ "GenMsgSendType" BO_ 996 5;
BA_ "GenMsgNrOfRepetitions" BO_ 996 2;
BA_ "GenMsgDelayTime" BO_ 996 20;
BA_ "GenMsgCycleTime" BO_ 996 2000;
BA_ "GenMsgStartValue" BO_ 1000 "FFFF7FF0FF0FFF00h";
BA_ "GenMsgStartDelayTime" BO_ 1000 50;
BA_ "GenMsgSendType" BO_ 1000 5;
BA_ "GenMsgNrOfRepetitions" BO_ 1000 2;
BA_ "GenMsgDelayTime" BO_ 1000 20;
BA_ "GenMsgCycleTime" BO_ 1000 500;
BA_ "GenMsgStartValue" BO_ 1001 "0300FF00FFFFFFFFh";
BA_ "GenMsgStartDelayTime" BO_ 1001 40;
BA_ "GenMsgSendType" BO_ 1001 5;
BA_ "GenMsgNrOfRepetitions" BO_ 1001 2;
BA_ "GenMsgDelayTime" BO_ 1001 20;
BA_ "GenMsgCycleTime" BO_ 1001 2000;
BA_ "GenMsgStartValue" BO_ 1002 "0370FF037FFF0000h";
BA_ "GenMsgStartDelayTime" BO_ 1002 50;
BA_ "GenMsgSendType" BO_ 1002 5;
BA_ "GenMsgNrOfRepetitions" BO_ 1002 2;
BA_ "GenMsgDelayTime" BO_ 1002 20;
BA_ "GenMsgCycleTime" BO_ 1002 2000;
BA_ "GenMsgStartValue" BO_ 1003 "FFFFFFFFFFFFFFFFh";
BA_ "GenMsgStartDelayTime" BO_ 1003 120;
BA_ "GenMsgSendType" BO_ 1003 5;
BA_ "GenMsgNrOfRepetitions" BO_ 1003 2;
BA_ "GenMsgDelayTime" BO_ 1003 20;
BA_ "GenMsgCycleTime" BO_ 1003 1000;
BA_ "GenMsgStartValue" BO_ 1013 "0300000000000000h";
BA_ "GenMsgStartDelayTime" BO_ 1013 60;
BA_ "GenMsgSendType" BO_ 1013 5;
BA_ "GenMsgNrOfRepetitions" BO_ 1013 2;
BA_ "GenMsgDelayTime" BO_ 1013 20;
BA_ "GenMsgCycleTime" BO_ 1013 2000;
BA_ "GenMsgNrOfRepetitions" BO_ 1089 2;
BA_ "GenMsgDelayTime" BO_ 1089 20;
BA_ "DiagState" BO_ 1089 1;
BA_ "GenMsgStartValue" BO_ 1089 "0000000000000000h";
BA_ "GenMsgStartValue" BO_ 1098 "C3FFFFFFFFFFFF00h";
BA_ "GenMsgStartDelayTime" BO_ 1098 60;
BA_ "GenMsgSendType" BO_ 1098 5;
BA_ "GenMsgNrOfRepetitions" BO_ 1098 2;
BA_ "GenMsgDelayTime" BO_ 1098 20;
BA_ "GenMsgCycleTime" BO_ 1098 2000;
BA_ "GenMsgStartValue" BO_ 1100 "73FFFFFFFFFFFFFFh";
BA_ "GenMsgStartDelayTime" BO_ 1100 70;
BA_ "GenMsgSendType" BO_ 1100 5;
BA_ "GenMsgNrOfRepetitions" BO_ 1100 2;
BA_ "GenMsgDelayTime" BO_ 1100 20;
BA_ "GenMsgCycleTime" BO_ 1100 2000;
BA_ "App-Botschaft" BO_ 1464 1;
BA_ "GenMsgSendType" BO_ 1464 1;
BA_ "GenMsgNrOfRepetitions" BO_ 1464 2;
BA_ "GenMsgDelayTime" BO_ 1464 20;
BA_ "GenMsgStartValue" BO_ 1464 "0000000000000000h";
BA_ "GenMsgCycleTime" BO_ 1592 200;
BA_ "GenMsgStartValue" BO_ 1592 "0000000000000000h";
BA_ "GenMsgStartDelayTime" BO_ 1592 800;
BA_ "GenMsgSendType" BO_ 1592 9;
BA_ "GenMsgDelayTime" BO_ 1592 200;
BA_ "App-Botschaft" BO_ 1784 1;
BA_ "GenMsgSendType" BO_ 1784 1;
BA_ "GenMsgNrOfRepetitions" BO_ 1784 2;
BA_ "GenMsgDelayTime" BO_ 1784 20;
BA_ "GenMsgStartValue" BO_ 1784 "0000000000000000h";
BA_ "DiagState" BO_ 2015 1;
BA_ "GenMsgStartValue" BO_ 2015 "0000000000000000h";
BA_ "GenMsgNrOfRepetitions" BO_ 2015 2;
BA_ "GenMsgDelayTime" BO_ 2015 20;
BA_ "DiagRequest" BO_ 2016 1;
BA_ "GenMsgSendType" BO_ 2016 1;
BA_ "GenMsgNrOfRepetitions" BO_ 2016 2;
BA_ "GenMsgDelayTime" BO_ 2016 20;
BA_ "GenMsgStartValue" BO_ 2016 "0000000000000000h";
BA_ "DiagResponse" BO_ 2024 1;
BA_ "GenMsgStartValue" BO_ 2024 "0000000000000000h";
BA_ "GenMsgSendType" BO_ 2024 1;
BA_ "GenMsgNrOfRepetitions" BO_ 2024 2;
BA_ "GenMsgDelayTime" BO_ 2024 20;
BA_ "GenMsgStartValue" BO_ 516 "00000000000000h";
BA_ "GenMsgSendType" BO_ 516 1;
BA_ "GenMsgNrOfRepetitions" BO_ 516 2;
BA_ "GenMsgDelayTime" BO_ 516 20;
BA_ "GenMsgStartValue" BO_ 517 "00000000000000h";
BA_ "GenMsgSendType" BO_ 517 1;
BA_ "GenMsgNrOfRepetitions" BO_ 517 2;
BA_ "GenMsgDelayTime" BO_ 517 20;
BA_ "GenMsgStartValue" BO_ 910 "000000FFFF7F7F00h";
BA_ "GenMsgNrOfRepetitions" BO_ 910 2;
BA_ "GenMsgDelayTime" BO_ 910 20;
BA_ "GenMsgCycleTime" BO_ 910 2000;
BA_ "GenMsgStartValue" BO_ 976 "0000000000000000h";
BA_ "GenMsgNrOfRepetitions" BO_ 976 2;
BA_ "GenMsgDelayTime" BO_ 976 20;
BA_ "GenMsgCycleTime" BO_ 976 500;
BA_ "GenMsgStartValue" BO_ 47 "FFFFFFFF00000000h";
BA_ "GenMsgNrOfRepetitions" BO_ 47 2;
BA_ "GenMsgDelayTime" BO_ 47 20;
BA_ "GenMsgCycleTime" BO_ 47 10;
BA_ "GenMsgNrOfRepetitions" BO_ 293 2;
BA_ "GenMsgDelayTime" BO_ 293 20;
BA_ "GenMsgCycleTime" BO_ 293 100;
BA_ "GenMsgStartValue" BO_ 293 "F0FF80h";
BA_ "GenMsgNrOfRepetitions" BO_ 147 2;
BA_ "GenMsgDelayTime" BO_ 147 20;
BA_ "GenMsgCycleTime" BO_ 147 20;
BA_ "GenMsgStartValue" BO_ 147 "1CFFFF00000000FFh";
BA_ "GenMsgStartValue" BO_ 133 "00FF00FFFFFFFF00h";
BA_ "GenMsgNrOfRepetitions" BO_ 133 2;
BA_ "GenMsgDelayTime" BO_ 133 20;
BA_ "GenMsgCycleTime" BO_ 133 20;
BA_ "GenMsgStartValue" BO_ 55 "1FFF1FFF1FFF00FFh";
BA_ "GenMsgNrOfRepetitions" BO_ 55 2;
BA_ "GenMsgDelayTime" BO_ 55 20;
BA_ "GenMsgCycleTime" BO_ 55 10;
BA_ "GenMsgStartValue" BO_ 149 "07FF001FFF00FFh";
BA_ "GenMsgNrOfRepetitions" BO_ 149 2;
BA_ "GenMsgDelayTime" BO_ 149 20;
BA_ "GenMsgCycleTime" BO_ 149 20;
BA_ "GenMsgNrOfRepetitions" BO_ 171 2;
BA_ "GenMsgDelayTime" BO_ 171 20;
BA_ "GenMsgCycleTime" BO_ 171 20;
BA_ "GenMsgStartValue" BO_ 171 "0FFF0F0F000000FFh";
BA_ "GenMsgNrOfRepetitions" BO_ 35 2;
BA_ "GenMsgDelayTime" BO_ 35 20;
BA_ "GenMsgStartValue" BO_ 35 "3FFF3FFF030000FFh";
BA_ "GenMsgCycleTime" BO_ 35 10;
BA_ "GenMsgStartValue" BO_ 177 "0000FFh";
BA_ "GenMsgSendType" BO_ 177 1;
BA_ "GenMsgNrOfRepetitions" BO_ 177 2;
BA_ "GenMsgDelayTime" BO_ 177 20;
BA_ "GenMsgNrOfRepetitions" BO_ 173 2;
BA_ "GenMsgDelayTime" BO_ 173 20;
BA_ "GenMsgCycleTime" BO_ 173 20;
BA_ "GenMsgStartValue" BO_ 173 "00000000FFh";
BA_ "GenMsgNrOfRepetitions" BO_ 333 2;
BA_ "GenMsgDelayTime" BO_ 333 20;
BA_ "GenMsgCycleTime" BO_ 333 100;
BA_ "GenMsgStartValue" BO_ 333 "FFFFFFFF0000FF00h";
BA_ "GenSigSNA" SG_ 897 VC_SmartAlternator "0h";
BA_ "GenSigSendType" SG_ 897 VC_SmartAlternator 5;
BA_ "GenSigCycleTime" SG_ 897 VC_SmartAlternator 2000;
BA_ "FlexKomSigStartValue" SG_ 897 VC_SmartAlternator "033F000000000000h";
BA_ "FlexKomSigStartPos" SG_ 897 VC_SmartAlternator 7;
BA_ "FlexKomSigName" SG_ 897 VC_SmartAlternator "VehCfg7_Pkt";
BA_ "FlexKomSigLaenge" SG_ 897 VC_SmartAlternator 64;
BA_ "FlexKomSID" SG_ 897 VC_SmartAlternator 2026;
BA_ "FlexKomIsMotorola" SG_ 897 VC_SmartAlternator 1;
BA_ "FlexKomComment" SG_ 897 VC_SmartAlternator "Vehicle Configuration 7 Packet";
BA_ "GenSigTimeout_OCM" SG_ 996 NetCfg_ORC 21000;
BA_ "GenSigTimeout_IC" SG_ 996 NetCfg_ORC 21000;
BA_ "GenSigTimeout_DPDM" SG_ 996 NetCfg_ORC 21000;
BA_ "GenSigSNA" SG_ 996 NetCfg_ORC "0h";
BA_ "GenSigSendType" SG_ 996 NetCfg_ORC 5;
BA_ "GenSigCycleTime" SG_ 996 NetCfg_ORC 2000;
BA_ "FlexKomSigStartValue" SG_ 996 NetCfg_ORC "0300000000000000h";
BA_ "FlexKomSigStartPos" SG_ 996 NetCfg_ORC 7;
BA_ "FlexKomSigName" SG_ 996 NetCfg_ORC "NET_CFG_DATA_PT";
BA_ "FlexKomSigLaenge" SG_ 996 NetCfg_ORC 64;
BA_ "FlexKomSID" SG_ 996 NetCfg_ORC 39;
BA_ "FlexKomIsMotorola" SG_ 996 NetCfg_ORC 1;
BA_ "FlexKomComment" SG_ 996 NetCfg_ORC "Network ECU config data for Powertrain";
BA_ "GenSigSNA" SG_ 466 IMPACT_X "0h";
BA_ "GenSigSendType" SG_ 466 IMPACT_X 2;
BA_ "GenSigCycleTimeActive" SG_ 466 IMPACT_X 20;
BA_ "FlexKomSigStartValue" SG_ 466 IMPACT_X "0000h";
BA_ "FlexKomSigStartPos" SG_ 466 IMPACT_X 7;
BA_ "FlexKomSigName" SG_ 466 IMPACT_X "IMPACT";
BA_ "FlexKomSigLaenge" SG_ 466 IMPACT_X 16;
BA_ "FlexKomSID" SG_ 466 IMPACT_X 325;
BA_ "FlexKomIsMotorola" SG_ 466 IMPACT_X 1;
BA_ "FlexKomComment" SG_ 466 IMPACT_X "Impact events";
BA_ "GenSigTimeout_ORC" SG_ 996 NetCfg_DTCM 7000;
BA_ "GenSigTimeout_IC" SG_ 996 NetCfg_DTCM 21000;
BA_ "GenSigSNA" SG_ 996 NetCfg_DTCM "0h";
BA_ "GenSigSendType" SG_ 996 NetCfg_DTCM 5;
BA_ "GenSigCycleTime" SG_ 996 NetCfg_DTCM 2000;
BA_ "FlexKomSigStartValue" SG_ 996 NetCfg_DTCM "0300000000000000h";
BA_ "FlexKomSigStartPos" SG_ 996 NetCfg_DTCM 7;
BA_ "FlexKomSigName" SG_ 996 NetCfg_DTCM "NET_CFG_DATA_PT";
BA_ "FlexKomSigLaenge" SG_ 996 NetCfg_DTCM 64;
BA_ "FlexKomSID" SG_ 996 NetCfg_DTCM 39;
BA_ "FlexKomIsMotorola" SG_ 996 NetCfg_DTCM 1;
BA_ "FlexKomComment" SG_ 996 NetCfg_DTCM "Network ECU config data for Powertrain";
BA_ "GenSigTimeout_IC" SG_ 996 NetCfg_ESM 21000;
BA_ "GenSigTimeout_ESM" SG_ 996 NetCfg_ESM 21000;
BA_ "GenSigTimeout_DTCM" SG_ 996 NetCfg_ESM 21000;
BA_ "GenSigSNA" SG_ 996 NetCfg_ESM "0h";
BA_ "GenSigSendType" SG_ 996 NetCfg_ESM 5;
BA_ "GenSigCycleTime" SG_ 996 NetCfg_ESM 2000;
BA_ "FlexKomSigStartValue" SG_ 996 NetCfg_ESM "0300000000000000h";
BA_ "FlexKomSigStartPos" SG_ 996 NetCfg_ESM 7;
BA_ "FlexKomSigName" SG_ 996 NetCfg_ESM "NET_CFG_DATA_PT";
BA_ "FlexKomSigLaenge" SG_ 996 NetCfg_ESM 64;
BA_ "FlexKomSID" SG_ 996 NetCfg_ESM 39;
BA_ "FlexKomIsMotorola" SG_ 996 NetCfg_ESM 1;
BA_ "FlexKomComment" SG_ 996 NetCfg_ESM "Network ECU config data for Powertrain";
BA_ "GenSigSNA" SG_ 1592 SD_RS_ECM "0h";
BA_ "GenSigSendType" SG_ 1592 SD_RS_ECM 9;
BA_ "GenSigCycleTime" SG_ 1592 SD_RS_ECM 200;
BA_ "FlexKomSigStartValue" SG_ 1592 SD_RS_ECM "0000000000000000h";
BA_ "FlexKomSigStartPos" SG_ 1592 SD_RS_ECM 7;
BA_ "FlexKomSigName" SG_ 1592 SD_RS_ECM "SD_RS_ECM";
BA_ "FlexKomSigLaenge" SG_ 1592 SD_RS_ECM 64;
BA_ "FlexKomSID" SG_ 1592 SD_RS_ECM 192;
BA_ "FlexKomIsMotorola" SG_ 1592 SD_RS_ECM 1;
BA_ "FlexKomComment" SG_ 1592 SD_RS_ECM "Response on Event - light";
BA_ "GenSigSNA" SG_ 1013 EC_Powertrain "0h";
BA_ "GenSigSendType" SG_ 1013 EC_Powertrain 5;
BA_ "GenSigCycleTime" SG_ 1013 EC_Powertrain 2000;
BA_ "FlexKomSigStartValue" SG_ 1013 EC_Powertrain "0000h";
BA_ "FlexKomSigStartPos" SG_ 1013 EC_Powertrain 39;
BA_ "FlexKomSigName" SG_ 1013 EC_Powertrain "EC_Powertrain";
BA_ "RID" SG_ 992 VIN_DATA "1239";
BA_ "GenSigTimeout_SCCM" SG_ 992 VIN_DATA 1050;
BA_ "GenSigTimeout_ORC" SG_ 992 VIN_DATA 350;
BA_ "GenSigTimeout_OCM" SG_ 992 VIN_DATA 5050;
BA_ "GenSigTimeout_IC" SG_ 992 VIN_DATA 1050;
BA_ "GenSigTimeout_ESM" SG_ 992 VIN_DATA 1050;
BA_ "GenSigTimeout_EHPS" SG_ 992 VIN_DATA 1050;
BA_ "GenSigTimeout_DPDM" SG_ 992 VIN_DATA 5050;
BA_ "GenSigSNA" SG_ 992 VIN_DATA "0h";
BA_ "GenSigCycleTime" SG_ 992 VIN_DATA 100;
BA_ "FlexKomSigStartValue" SG_ 992 VIN_DATA "0300000000000000h";
BA_ "FlexKomSigStartPos" SG_ 992 VIN_DATA 7;
BA_ "FlexKomSigName" SG_ 992 VIN_DATA "VIN_INFO";
BA_ "FlexKomSigLaenge" SG_ 992 VIN_DATA 64;
BA_ "FlexKomSID" SG_ 992 VIN_DATA 430;
BA_ "FlexKomIsMotorola" SG_ 992 VIN_DATA 1;
BA_ "FlexKomComment" SG_ 992 VIN_DATA "Vin Information";
BA_ "GenSigTimeout_ESM" SG_ 147 SHFT_LOCK 210;
BA_ "GenSigSNA" SG_ 147 SHFT_LOCK "0h";
BA_ "GenSigCycleTime" SG_ 147 SHFT_LOCK 20;
BA_ "FlexKomSigStartValue" SG_ 147 SHFT_LOCK "1CFFFF00000000FFh";
BA_ "FlexKomSigStartPos" SG_ 147 SHFT_LOCK 7;
BA_ "FlexKomSigName" SG_ 147 SHFT_LOCK "TRNS_STAT_PKT";
BA_ "FlexKomSigLaenge" SG_ 147 SHFT_LOCK 64;
BA_ "FlexKomSID" SG_ 147 SHFT_LOCK 1366;
BA_ "FlexKomIsMotorola" SG_ 147 SHFT_LOCK 1;
BA_ "FlexKomComment" SG_ 147 SHFT_LOCK "TRNS_STAT message packet";
BA_ "GenSigSNA" SG_ 133 Trns_EMCC_Achvd "0h";
BA_ "GenSigCycleTime" SG_ 133 Trns_EMCC_Achvd 20;
BA_ "FlexKomSigStartValue" SG_ 133 Trns_EMCC_Achvd "00h";
BA_ "FlexKomSigStartPos" SG_ 133 Trns_EMCC_Achvd 20;
BA_ "FlexKomSigName" SG_ 133 Trns_EMCC_Achvd "Trns_EMCC_Achvd";
BA_ "FlexKomSigLaenge" SG_ 133 Trns_EMCC_Achvd 1;
BA_ "FlexKomSID" SG_ 133 Trns_EMCC_Achvd 1130;
BA_ "FlexKomIsMotorola" SG_ 133 Trns_EMCC_Achvd 1;
BA_ "FlexKomComment" SG_ 133 Trns_EMCC_Achvd "Trans A/C Converter Clutch Slipping; [1] = True";
BA_ "GenSigTimeout_ORC" SG_ 333 VVT_ExhCam2Pos 350;
BA_ "GenSigStartValue" SG_ 333 VVT_ExhCam2Pos 255;
BA_ "GenSigSNA" SG_ 333 VVT_ExhCam2Pos "0h";
BA_ "GenSigCycleTime" SG_ 333 VVT_ExhCam2Pos 100;
BA_ "FlexKomSigStartValue" SG_ 333 VVT_ExhCam2Pos "FFFFFFFF0000FF00h";
BA_ "FlexKomSigStartPos" SG_ 333 VVT_ExhCam2Pos 7;
BA_ "FlexKomSigName" SG_ 333 VVT_ExhCam2Pos "EDR2_Pkt";
BA_ "FlexKomSigLaenge" SG_ 333 VVT_ExhCam2Pos 64;
BA_ "FlexKomSID" SG_ 333 VVT_ExhCam2Pos 1093;
BA_ "FlexKomIsMotorola" SG_ 333 VVT_ExhCam2Pos 1;
BA_ "FlexKomComment" SG_ 333 VVT_ExhCam2Pos "EDR2 information packet only";
BA_ "GenSigTimeout_ORC" SG_ 333 GF_Charge 350;
BA_ "GenSigSNA" SG_ 333 GF_Charge "FFFFh";
BA_ "GenSigCycleTime" SG_ 333 GF_Charge 100;
BA_ "FlexKomSigStartValue" SG_ 333 GF_Charge "FFFFFFFF0000FF00h";
BA_ "FlexKomSigStartPos" SG_ 333 GF_Charge 7;
BA_ "FlexKomSigName" SG_ 333 GF_Charge "EDR2_Pkt";
BA_ "FlexKomSigLaenge" SG_ 333 GF_Charge 64;
BA_ "GenSigSNA" SG_ 2015 DG_RQ_GLOBAL "0h";
BA_ "FlexKomSigStartValue" SG_ 2015 DG_RQ_GLOBAL "0000000000000000h";
BA_ "FlexKomSigStartPos" SG_ 2015 DG_RQ_GLOBAL 7;
BA_ "FlexKomSigName" SG_ 2015 DG_RQ_GLOBAL "DG_RQ_GLOBAL";
BA_ "FlexKomSigLaenge" SG_ 2015 DG_RQ_GLOBAL 64;
BA_ "FlexKomSID" SG_ 2015 DG_RQ_GLOBAL 392;
BA_ "FlexKomIsMotorola" SG_ 2015 DG_RQ_GLOBAL 1;
BA_ "FlexKomComment" SG_ 2015 DG_RQ_GLOBAL "Diagnostic-Request";
BA_ "GenSigSNA" SG_ 2016 D_RQ_ECM "0h";
BA_ "GenSigSendType" SG_ 2016 D_RQ_ECM 1;
BA_ "FlexKomSigStartValue" SG_ 2016 D_RQ_ECM "0000000000000000h";
BA_ "FlexKomSigStartPos" SG_ 2016 D_RQ_ECM 7;
BA_ "FlexKomSigName" SG_ 2016 D_RQ_ECM "D_RQ_ECM";
BA_ "FlexKomSigLaenge" SG_ 2016 D_RQ_ECM 64;
BA_ "FlexKomSID" SG_ 2016 D_RQ_ECM 85;
BA_ "FlexKomIsMotorola" SG_ 2016 D_RQ_ECM 1;
BA_ "FlexKomComment" SG_ 2016 D_RQ_ECM "Diagnostic-Request";
BA_ "GenSigSNA" SG_ 976 KNK_MG_TRIGGER "0h";
BA_ "GenSigCycleTime" SG_ 976 KNK_MG_TRIGGER 500;
BA_ "FlexKomSigStartValue" SG_ 976 KNK_MG_TRIGGER "0000000000000000h";
BA_ "FlexKomSigStartPos" SG_ 976 KNK_MG_TRIGGER 7;
BA_ "FlexKomSigName" SG_ 976 KNK_MG_TRIGGER "ECM_A4_Pkt";
BA_ "FlexKomSigLaenge" SG_ 976 KNK_MG_TRIGGER 64;
BA_ "FlexKomSID" SG_ 976 KNK_MG_TRIGGER 2627;
BA_ "FlexKomIsMotorola" SG_ 976 KNK_MG_TRIGGER 1;
BA_ "FlexKomComment" SG_ 976 KNK_MG_TRIGGER "ECM_A4 Packet";
BA_ "GenSigSNA" SG_ 47 RAW_OBD_VEHACCEL_X "0h";
BA_ "GenSigCycleTime" SG_ 47 RAW_OBD_VEHACCEL_X 10;
BA_ "FlexKomSigStartValue" SG_ 47 RAW_OBD_VEHACCEL_X "00h";
BA_ "FlexKomSigStartPos" SG_ 47 RAW_OBD_VEHACCEL_X 55;
BA_ "FlexKomSigName" SG_ 47 RAW_OBD_VEHACCEL_X "RAW_OBD_VEHACCEL_X";
BA_ "FlexKomSigLaenge" SG_ 47 RAW_OBD_VEHACCEL_X 8;
BA_ "FlexKomSID" SG_ 47 RAW_OBD_VEHACCEL_X 2596;
BA_ "FlexKomIsMotorola" SG_ 47 RAW_OBD_VEHACCEL_X 1;
BA_ "FlexKomComment" SG_ 47 RAW_OBD_VEHACCEL_X "Raw vehicle acceleration in the X direction";
BA_ "GenSigTimeout_IC" SG_ 293 MIL_OnRq_TCM 1050;
BA_ "GenSigSNA" SG_ 293 MIL_OnRq_TCM "0h";
BA_ "GenSigCycleTime" SG_ 293 MIL_OnRq_TCM 100;
BA_ "FlexKomSigStartValue" SG_ 293 MIL_OnRq_TCM "00h";
BA_ "FlexKomSigName" SG_ 293 MIL_OnRq_TCM "MIL_OnRq_TCM";
BA_ "FlexKomSigLaenge" SG_ 293 MIL_OnRq_TCM 1;
BA_ "FlexKomSID" SG_ 293 MIL_OnRq_TCM 1141;
BA_ "FlexKomIsMotorola" SG_ 293 MIL_OnRq_TCM 1;
BA_ "FlexKomComment" SG_ 293 MIL_OnRq_TCM "MIL on request from the transmission";
BA_ "GenSigStartValue" SG_ 293 FAN_RQ 15;
BA_ "GenSigSNA" SG_ 293 FAN_RQ "Fh";
BA_ "GenSigCycleTime" SG_ 293 FAN_RQ 100;
BA_ "FlexKomSigStartValue" SG_ 293 FAN_RQ "0Fh";
BA_ "FlexKomSigStartPos" SG_ 293 FAN_RQ 7;
BA_ "FlexKomSigName" SG_ 293 FAN_RQ "FAN_RQ";
BA_ "FlexKomSigLaenge" SG_ 293 FAN_RQ 4;
BA_ "FlexKomSID" SG_ 293 FAN_RQ 1145;
BA_ "FlexKomIsMotorola" SG_ 293 FAN_RQ 1;
BA_ "FlexKomComment" SG_ 293 FAN_RQ "Cooling fan request";
BA_ "GenSigStartValue" SG_ 293 TRNS_StpSt_FLT 1;
BA_ "GenSigStartValue" SG_ 149 CRC_TCM_ENG_TRQ 255;
BA_ "GenSigSNA" SG_ 149 CRC_TCM_ENG_TRQ "FFh";
BA_ "GenSigCycleTime" SG_ 149 CRC_TCM_ENG_TRQ 20;
BA_ "FlexKomSigStartValue" SG_ 149 CRC_TCM_ENG_TRQ "07FF001FFF00FFh";
BA_ "FlexKomSigStartPos" SG_ 149 CRC_TCM_ENG_TRQ 7;
BA_ "FlexKomSigName" SG_ 149 CRC_TCM_ENG_TRQ "ENG_TRQ_PKT";
BA_ "FlexKomSigLaenge" SG_ 149 CRC_TCM_ENG_TRQ 56;
BA_ "FlexKomSID" SG_ 149 CRC_TCM_ENG_TRQ 788;
BA_ "FlexKomIsMotorola" SG_ 149 CRC_TCM_ENG_TRQ 1;
BA_ "FlexKomComment" SG_ 149 CRC_TCM_ENG_TRQ "Engine torque packet for all transmissions";
BA_ "GenSigStartValue" SG_ 171 CurrentGear 15;
BA_ "GenSigSNA" SG_ 171 CurrentGear "Fh";
BA_ "GenSigCycleTime" SG_ 171 CurrentGear 20;
BA_ "FlexKomSigStartValue" SG_ 171 CurrentGear "0FFF0F0F000000FFh";
BA_ "FlexKomSigStartPos" SG_ 171 CurrentGear 7;
BA_ "FlexKomSigName" SG_ 171 CurrentGear "TCM_A7_PKT";
BA_ "FlexKomSigLaenge" SG_ 171 CurrentGear 64;
BA_ "FlexKomSID" SG_ 171 CurrentGear 1613;
BA_ "FlexKomIsMotorola" SG_ 171 CurrentGear 1;
BA_ "FlexKomComment" SG_ 171 CurrentGear "Transmission message A7 packet";
BA_ "RID" SG_ 171 TX_WARN2 "2157";
BA_ "GenSigCycleTime" SG_ 173 MC_SBW_ROT1 20;
BA_ "FlexKomSigStartValue" SG_ 173 MC_SBW_ROT1 "00000000FFh";
BA_ "FlexKomSigStartPos" SG_ 173 MC_SBW_ROT1 7;
BA_ "FlexKomSigName" SG_ 173 MC_SBW_ROT1 "SBW_ROT1_PKT";
BA_ "FlexKomSigLaenge" SG_ 173 MC_SBW_ROT1 40;
BA_ "FlexKomSID" SG_ 173 MC_SBW_ROT1 1661;
BA_ "FlexKomIsMotorola" SG_ 173 MC_SBW_ROT1 1;
BA_ "FlexKomComment" SG_ 173 MC_SBW_ROT1 "Shift by wire - rotary 1 packet";
BA_ "RID" SG_ 992 VIN_MSG "1275";
BA_ "GenSigTimeout_SCCM" SG_ 992 VIN_MSG 1050;
BA_ "GenSigTimeout_RF_HUB" SG_ 992 VIN_MSG 1050;
BA_ "GenSigTimeout_ORC" SG_ 992 VIN_MSG 350;
BA_ "GenSigTimeout_OCM" SG_ 992 VIN_MSG 5050;
BA_ "GenSigTimeout_IC" SG_ 992 VIN_MSG 1050;
BA_ "GenSigTimeout_ESM" SG_ 992 VIN_MSG 1050;
BA_ "GenSigTimeout_EHPS" SG_ 992 VIN_MSG 1050;
BA_ "GenSigTimeout_DTCM" SG_ 992 VIN_MSG 1050;
BA_ "GenSigTimeout_DPDM" SG_ 992 VIN_MSG 5050;
BA_ "GenSigStartValue" SG_ 992 VIN_MSG 3;
BA_ "GenSigSNA" SG_ 992 VIN_MSG "3h";
BA_ "GenSigCycleTime" SG_ 992 VIN_MSG 100;
BA_ "FlexKomSigStartValue" SG_ 992 VIN_MSG "0300000000000000h";
BA_ "FlexKomSigStartPos" SG_ 992 VIN_MSG 7;
BA_ "FlexKomSigName" SG_ 992 VIN_MSG "VIN_INFO";
BA_ "FlexKomSigLaenge" SG_ 992 VIN_MSG 64;
BA_ "FlexKomSID" SG_ 992 VIN_MSG 430;
BA_ "FlexKomIsMotorola" SG_ 992 VIN_MSG 1;
BA_ "FlexKomComment" SG_ 992 VIN_MSG "Vin Information";
BA_ "GenSigSNA" SG_ 147 EngStEnblRqTCM "0h";
BA_ "GenSigCycleTime" SG_ 147 EngStEnblRqTCM 20;
BA_ "FlexKomSigStartValue" SG_ 147 EngStEnblRqTCM "1CFFFF00000000FFh";
BA_ "FlexKomSigStartPos" SG_ 147 EngStEnblRqTCM 7;
BA_ "FlexKomSigName" SG_ 147 EngStEnblRqTCM "TRNS_STAT_PKT";
BA_ "FlexKomSigLaenge" SG_ 147 EngStEnblRqTCM 64;
BA_ "FlexKomSID" SG_ 147 EngStEnblRqTCM 1366;
BA_ "FlexKomIsMotorola" SG_ 147 EngStEnblRqTCM 1;
BA_ "FlexKomComment" SG_ 147 EngStEnblRqTCM "TRNS_STAT message packet";
BA_ "GenSigSNA" SG_ 1089 DG_RQ_GLOBAL_UDS "0h";
BA_ "FlexKomSigStartValue" SG_ 1089 DG_RQ_GLOBAL_UDS "0000000000000000h";
BA_ "FlexKomSigStartPos" SG_ 1089 DG_RQ_GLOBAL_UDS 7;
BA_ "FlexKomSigName" SG_ 1089 DG_RQ_GLOBAL_UDS "DG_RQ_GLOBAL_UDS";
BA_ "FlexKomSigLaenge" SG_ 1089 DG_RQ_GLOBAL_UDS 64;
BA_ "FlexKomSID" SG_ 1089 DG_RQ_GLOBAL_UDS 393;
BA_ "FlexKomIsMotorola" SG_ 1089 DG_RQ_GLOBAL_UDS 1;
BA_ "FlexKomComment" SG_ 1089 DG_RQ_GLOBAL_UDS "Diagnostic-Request";
BA_ "GenSigTimeout_PTS" SG_ 1098 VC_VehCfg5_Stat 21000;
BA_ "GenSigTimeout_ORC" SG_ 1098 VC_VehCfg5_Stat 7000;
BA_ "GenSigTimeout_IC" SG_ 1098 VC_VehCfg5_Stat 21000;
BA_ "GenSigStartValue" SG_ 1098 VC_VehCfg5_Stat 3;
BA_ "GenSigSNA" SG_ 1098 VC_VehCfg5_Stat "3h";
BA_ "GenSigSendType" SG_ 1098 VC_VehCfg5_Stat 5;
BA_ "GenSigCycleTime" SG_ 1098 VC_VehCfg5_Stat 2000;
BA_ "FlexKomSigStartValue" SG_ 1098 VC_VehCfg5_Stat "C3FFFFFFFFFFFF00h";
BA_ "FlexKomSigStartPos" SG_ 1098 VC_VehCfg5_Stat 7;
BA_ "FlexKomSigName" SG_ 1098 VC_VehCfg5_Stat "VehCfg5_Pkt";
BA_ "FlexKomSigLaenge" SG_ 1098 VC_VehCfg5_Stat 64;
BA_ "FlexKomSID" SG_ 1098 VC_VehCfg5_Stat 1198;
BA_ "FlexKomIsMotorola" SG_ 1098 VC_VehCfg5_Stat 1;
BA_ "FlexKomComment" SG_ 1098 VC_VehCfg5_Stat "Vehicle Configuration 5 Packet";
BA_ "RID" SG_ 910 IBS3_FLAG_DISCONNECT "5131";
BA_ "GenSigSNA" SG_ 910 IBS3_FLAG_DISCONNECT "0h";
BA_ "GenSigCycleTime" SG_ 910 IBS3_FLAG_DISCONNECT 2000;
BA_ "FlexKomSigStartValue" SG_ 910 IBS3_FLAG_DISCONNECT "00FFFF7F7F80h";
BA_ "FlexKomSigStartPos" SG_ 910 IBS3_FLAG_DISCONNECT 23;
BA_ "FlexKomSigName" SG_ 910 IBS3_FLAG_DISCONNECT "GW_LIN_I_C6_Pkt2";
BA_ "FlexKomSigLaenge" SG_ 910 IBS3_FLAG_DISCONNECT 48;
BA_ "FlexKomSID" SG_ 910 IBS3_FLAG_DISCONNECT 2657;
BA_ "FlexKomIsMotorola" SG_ 910 IBS3_FLAG_DISCONNECT 1;
BA_ "FlexKomComment" SG_ 910 IBS3_FLAG_DISCONNECT "Cyclic only";
BA_ "RID" SG_ 910 IBS3_SOH_Q_Accuracy "5086";
BA_ "FlexKomIsMotorola" SG_ 147 SHFT_PROG 1;
BA_ "FlexKomComment" SG_ 147 SHFT_PROG "TRNS_STAT message packet";
BA_ "GenSigSNA" SG_ 147 TxDisengaged "0h";
BA_ "GenSigCycleTime" SG_ 147 TxDisengaged 20;
BA_ "FlexKomSigStartValue" SG_ 147 TxDisengaged "1CFFFF00000000FFh";
BA_ "FlexKomSigStartPos" SG_ 147 TxDisengaged 7;
BA_ "FlexKomSigName" SG_ 147 TxDisengaged "TRNS_STAT_PKT";
BA_ "FlexKomSigLaenge" SG_ 147 TxDisengaged 64;
BA_ "FlexKomSID" SG_ 147 TxDisengaged 1366;
BA_ "FlexKomIsMotorola" SG_ 147 TxDisengaged 1;
BA_ "FlexKomComment" SG_ 147 TxDisengaged "TRNS_STAT message packet";
BA_ "GenSigTimeout_ORC" SG_ 147 CRC_TRNS_STAT 70;
BA_ "GenSigTimeout_ESM" SG_ 147 CRC_TRNS_STAT 410;
BA_ "GenSigStartValue" SG_ 147 CRC_TRNS_STAT 255;
BA_ "GenSigSNA" SG_ 147 CRC_TRNS_STAT "FFh";
BA_ "GenSigCycleTime" SG_ 147 CRC_TRNS_STAT 20;
BA_ "FlexKomSigStartValue" SG_ 147 CRC_TRNS_STAT "1CFFFF00000000FFh";
BA_ "FlexKomSigStartPos" SG_ 147 CRC_TRNS_STAT 7;
BA_ "FlexKomSigName" SG_ 147 CRC_TRNS_STAT "TRNS_STAT_PKT";
BA_ "FlexKomSigLaenge" SG_ 147 CRC_TRNS_STAT 64;
BA_ "FlexKomSID" SG_ 147 CRC_TRNS_STAT 1366;
BA_ "FlexKomIsMotorola" SG_ 147 CRC_TRNS_STAT 1;
BA_ "FlexKomComment" SG_ 147 CRC_TRNS_STAT "TRNS_STAT message packet";
BA_ "RID" SG_ 133 Gr "1069";
BA_ "GenSigTimeout_RF_HUB" SG_ 133 Gr 210;
BA_ "GenSigTimeout_ORC" SG_ 133 Gr 70;
BA_ "GenSigTimeout_IC" SG_ 133 Gr 210;
BA_ "GenSigTimeout_ESM" SG_ 133 Gr 210;
BA_ "GenSigTimeout_DTCM" SG_ 133 Gr 210;
BA_ "GenSigTimeout_CBC" SG_ 133 Gr 210;
BA_ "GenSigSNA" SG_ 516 MKKey_3 "0h";
BA_ "GenSigSendType" SG_ 516 MKKey_3 1;
BA_ "FlexKomSigStartValue" SG_ 516 MKKey_3 "00000000000000h";
BA_ "FlexKomSigStartPos" SG_ 516 MKKey_3 7;
BA_ "FlexKomSigName" SG_ 516 MKKey_3 "IMMO_CODE_RESPONSE";
BA_ "FlexKomSigLaenge" SG_ 516 MKKey_3 56;
BA_ "FlexKomSID" SG_ 516 MKKey_3 2110;
BA_ "FlexKomIsMotorola" SG_ 516 MKKey_3 1;
BA_ "FlexKomComment" SG_ 516 MKKey_3 "Immobilizer code response packet";
BA_ "GenSigSNA" SG_ 516 MKKey_6 "0h";
BA_ "GenSigSNA" SG_ 928 ECM_APPL6 "0h";
BA_ "GenSigSendType" SG_ 928 ECM_APPL6 1;
BA_ "FlexKomSigStartValue" SG_ 928 ECM_APPL6 "0000000000000000h";
BA_ "FlexKomSigStartPos" SG_ 928 ECM_APPL6 7;
BA_ "FlexKomSigName" SG_ 928 ECM_APPL6 "ECM_APPL6";
BA_ "FlexKomSigLaenge" SG_ 928 ECM_APPL6 64;
BA_ "FlexKomSID" SG_ 928 ECM_APPL6 784;
BA_ "FlexKomIsMotorola" SG_ 928 ECM_APPL6 1;
BA_ "FlexKomComment" SG_ 928 ECM_APPL6 "CCP 80ms DAQ  (from ENGINE to external tool)";
BA_ "GenSigSNA" SG_ 880 ECM_APPL3 "0h";
BA_ "GenSigSendType" SG_ 880 ECM_APPL3 1;
BA_ "FlexKomSigStartValue" SG_ 880 ECM_APPL3 "0000000000000000h";
BA_ "FlexKomSigStartPos" SG_ 880 ECM_APPL3 7;
BA_ "FlexKomSigName" SG_ 880 ECM_APPL3 "ECM_APPL3";
BA_ "FlexKomSigLaenge" SG_ 880 ECM_APPL3 64;
BA_ "FlexKomSID" SG_ 880 ECM_APPL3 781;
BA_ "FlexKomIsMotorola" SG_ 880 ECM_APPL3 1;
BA_ "FlexKomComment" SG_ 880 ECM_APPL3 "CCP synchronous - TDC event DAQ";
BA_ "FlexKomSID" SG_ 35 Pad_Shft 418;
BA_ "FlexKomIsMotorola" SG_ 35 Pad_Shft 1;
BA_ "FlexKomComment" SG_ 35 Pad_Shft "Steering wheel angle state";
BA_ "GenSigSNA" SG_ 177 AcceleratorSts "0h";
BA_ "GenSigSendType" SG_ 177 AcceleratorSts 1;
BA_ "FlexKomSigStartValue" SG_ 177 AcceleratorSts "0000FFh";
BA_ "FlexKomSigStartPos" SG_ 177 AcceleratorSts 7;
BA_ "FlexKomSigName" SG_ 177 AcceleratorSts "CrsCtrlLvrSts";
BA_ "FlexKomSigLaenge" SG_ 177 AcceleratorSts 24;
BA_ "FlexKomSID" SG_ 177 AcceleratorSts 1848;
BA_ "FlexKomIsMotorola" SG_ 177 AcceleratorSts 1;
BA_ "FlexKomComment" SG_ 177 AcceleratorSts "Cruise Control Lever Status";
BA_ "GenSigSNA" SG_ 177 CruiseControlFailSts "0h";
BA_ "GenSigSendType" SG_ 177 CruiseControlFailSts 1;
BA_ "FlexKomSigStartValue" SG_ 177 CruiseControlFailSts "0000FFh";
BA_ "FlexKomSigStartPos" SG_ 177 CruiseControlFailSts 7;
BA_ "FlexKomSigName" SG_ 177 CruiseControlFailSts "CrsCtrlLvrSts";
BA_ "FlexKomSigLaenge" SG_ 177 CruiseControlFailSts 24;
BA_ "FlexKomSID" SG_ 177 CruiseControlFailSts 1848;
BA_ "FlexKomIsMotorola" SG_ 177 CruiseControlFailSts 1;
BA_ "FlexKomComment" SG_ 177 CruiseControlFailSts "Cruise Control Lever Status";
BA_ "GenSigSNA" SG_ 177 ACC_DistSwInc "0h";
BA_ "GenSigSendType" SG_ 177 ACC_DistSwInc 1;
BA_ "FlexKomSigStartValue" SG_ 177 ACC_DistSwInc "0000FFh";
BA_ "FlexKomSigStartPos" SG_ 177 ACC_DistSwInc 7;
BA_ "FlexKomSigName" SG_ 177 ACC_DistSwInc "CrsCtrlLvrSts";
BA_ "FlexKomSigLaenge" SG_ 177 ACC_DistSwInc 24;
BA_ "FlexKomSID" SG_ 177 ACC_DistSwInc 1848;
BA_ "FlexKomIsMotorola" SG_ 177 ACC_DistSwInc 1;
BA_ "FlexKomComment" SG_ 177 ACC_DistSwInc "Cruise Control Lever Status";
BA_ "GenSigStartValue" SG_ 173 CRC_SBW_ROT1 255;
BA_ "GenSigSNA" SG_ 173 CRC_SBW_ROT1 "FFh";
BA_ "GenSigSNA" SG_ 910 IBS3_SOF_VC "7Fh";
BA_ "GenSigCycleTime" SG_ 910 IBS3_SOF_VC 2000;
BA_ "FlexKomSigStartValue" SG_ 910 IBS3_SOF_VC "00FFFF7F7F80h";
BA_ "FlexKomSigStartPos" SG_ 910 IBS3_SOF_VC 23;
BA_ "FlexKomSigName" SG_ 910 IBS3_SOF_VC "GW_LIN_I_C6_Pkt2";
BA_ "FlexKomSigLaenge" SG_ 910 IBS3_SOF_VC 48;
BA_ "FlexKomSID" SG_ 910 IBS3_SOF_VC 2657;
BA_ "FlexKomIsMotorola" SG_ 910 IBS3_SOF_VC 1;
BA_ "FlexKomComment" SG_ 910 IBS3_SOF_VC "Cyclic only";
BA_ "GenSigTimeout_ETM" SG_ 35 Pad_Shft 105;
BA_ "GenSigSNA" SG_ 35 Pad_Shft "7h";
BA_ "GenSigCycleTime" SG_ 35 Pad_Shft 10;
BA_ "FlexKomSigStartValue" SG_ 35 Pad_Shft "3FFF3FFF030000FFh";
BA_ "FlexKomSigStartPos" SG_ 35 Pad_Shft 7;
BA_ "FlexKomSigName" SG_ 35 Pad_Shft "LRW_ST";
BA_ "FlexKomSigLaenge" SG_ 35 Pad_Shft 64;
BA_ "GenSigTimeout_SCCM" SG_ 996 NetCfg_SCCM 21000;
BA_ "FlexKomSigStartValue" SG_ 333 VVT_IntCam1Pos "FFFFFFFF0000FF00h";
BA_ "FlexKomSigStartPos" SG_ 333 VVT_IntCam1Pos 7;
BA_ "FlexKomSigName" SG_ 333 VVT_IntCam1Pos "EDR2_Pkt";
BA_ "FlexKomSigLaenge" SG_ 333 VVT_IntCam1Pos 64;
BA_ "FlexKomSID" SG_ 333 VVT_IntCam1Pos 1093;
BA_ "FlexKomIsMotorola" SG_ 333 VVT_IntCam1Pos 1;
BA_ "FlexKomComment" SG_ 333 VVT_IntCam1Pos "EDR2 information packet only";
BA_ "GenSigTimeout_ORC" SG_ 333 RelativeThrtPct 350;
BA_ "GenSigStartValue" SG_ 333 RelativeThrtPct 255;
BA_ "GenSigSNA" SG_ 333 RelativeThrtPct "FFh";
BA_ "GenSigCycleTime" SG_ 333 RelativeThrtPct 100;
BA_ "FlexKomSigStartValue" SG_ 333 RelativeThrtPct "FFFFFFFF0000FF00h";
BA_ "FlexKomSigStartPos" SG_ 333 RelativeThrtPct 7;
BA_ "FlexKomSigName" SG_ 333 RelativeThrtPct "EDR2_Pkt";
BA_ "FlexKomSigLaenge" SG_ 333 RelativeThrtPct 64;
BA_ "FlexKomSID" SG_ 333 RelativeThrtPct 1093;
BA_ "FlexKomIsMotorola" SG_ 333 RelativeThrtPct 1;
BA_ "FlexKomComment" SG_ 333 RelativeThrtPct "EDR2 information packet only";
BA_ "GenSigTimeout_ORC" SG_ 996 NetCfg_SCCM 7000;
BA_ "GenSigCycleTime" SG_ 173 CRC_SBW_ROT1 20;
BA_ "FlexKomSigStartValue" SG_ 173 CRC_SBW_ROT1 "00000000FFh";
BA_ "FlexKomSigStartPos" SG_ 173 CRC_SBW_ROT1 7;
BA_ "FlexKomSigName" SG_ 173 CRC_SBW_ROT1 "SBW_ROT1_PKT";
BA_ "FlexKomSigLaenge" SG_ 173 CRC_SBW_ROT1 40;
BA_ "FlexKomSID" SG_ 173 CRC_SBW_ROT1 1661;
BA_ "FlexKomIsMotorola" SG_ 173 CRC_SBW_ROT1 1;
BA_ "FlexKomComment" SG_ 173 CRC_SBW_ROT1 "Shift by wire - rotary 1 packet";
BA_ "GenSigTimeout_ORC" SG_ 897 VC_HybridType 7000;
BA_ "FlexKomIsMotorola" SG_ 35 CRC_STW_Angle_STAT 1;
BA_ "FlexKomComment" SG_ 35 CRC_STW_Angle_STAT "Steering wheel angle state";
BA_ "GenSigSNA" SG_ 1784 APPL_ECU_ECM "0h";
BA_ "GenSigSendType" SG_ 1784 APPL_ECU_ECM 1;
BA_ "FlexKomSigStartValue" SG_ 1784 APPL_ECU_ECM "0000000000000000h";
BA_ "FlexKomSigStartPos" SG_ 1784 APPL_ECU_ECM 7;
BA_ "FlexKomSigName" SG_ 1784 APPL_ECU_ECM "APPL_ECU_ECM";
BA_ "FlexKomSigLaenge" SG_ 1784 APPL_ECU_ECM 64;
BA_ "GenSigTimeout_ORC" SG_ 1100 VC_VehCfg6_Stat 7000;
BA_ "GenSigStartValue" SG_ 1100 VC_VehCfg6_Stat 3;
BA_ "GenSigSNA" SG_ 1100 VC_VehCfg6_Stat "3h";
BA_ "GenSigSendType" SG_ 1100 VC_VehCfg6_Stat 5;
BA_ "GenSigCycleTime" SG_ 1100 VC_VehCfg6_Stat 2000;
BA_ "FlexKomSigStartValue" SG_ 1100 VC_VehCfg6_Stat "73FFFFFFFFFFFFFFh";
BA_ "FlexKomSigStartPos" SG_ 1100 VC_VehCfg6_Stat 7;
BA_ "FlexKomSigName" SG_ 1100 VC_VehCfg6_Stat "VehCfg6_Pkt";
BA_ "FlexKomSigLaenge" SG_ 1100 VC_VehCfg6_Stat 64;
BA_ "FlexKomSID" SG_ 1100 VC_VehCfg6_Stat 1199;
BA_ "FlexKomIsMotorola" SG_ 1100 VC_VehCfg6_Stat 1;
BA_ "FlexKomComment" SG_ 1100 VC_VehCfg6_Stat "Vehicle Configuration 6 Packet";
BA_ "GenSigTimeout_ORC" SG_ 333 VVT_ExhCam1Pos 350;
BA_ "GenSigStartValue" SG_ 333 VVT_ExhCam1Pos 255;
BA_ "GenSigTimeout_RF_HUB" SG_ 1003 VC_VehCfg4_Stat 10500;
BA_ "GenSigTimeout_ORC" SG_ 1003 VC_VehCfg4_Stat 3500;
BA_ "GenSigTimeout_EHPS" SG_ 1003 VC_VehCfg4_Stat 10500;
BA_ "GenSigStartValue" SG_ 1003 VC_VehCfg4_Stat 3;
BA_ "GenSigSNA" SG_ 1003 VC_VehCfg4_Stat "3h";
BA_ "GenSigSendType" SG_ 1003 VC_VehCfg4_Stat 5;
BA_ "GenSigCycleTime" SG_ 1003 VC_VehCfg4_Stat 1000;
BA_ "FlexKomSigStartValue" SG_ 1003 VC_VehCfg4_Stat "FFFFFFFFFFFFFFFFh";
BA_ "FlexKomSigStartPos" SG_ 1003 VC_VehCfg4_Stat 7;
BA_ "FlexKomSigName" SG_ 1003 VC_VehCfg4_Stat "VehCfg4_Pkt";
BA_ "FlexKomSigLaenge" SG_ 1003 VC_VehCfg4_Stat 64;
BA_ "FlexKomSID" SG_ 1003 VC_VehCfg4_Stat 1035;
BA_ "FlexKomIsMotorola" SG_ 1003 VC_VehCfg4_Stat 1;
BA_ "FlexKomComment" SG_ 1003 VC_VehCfg4_Stat "Vehicle Configuration 4 Packet";
BA_ "GenSigTimeout_ORC" SG_ 1003 VC_TIRE_CIRCUMF 3500;
BA_ "GenSigTimeout_EHPS" SG_ 1003 VC_TIRE_CIRCUMF 10500;
BA_ "GenSigTimeout_DTCM" SG_ 1003 VC_TIRE_CIRCUMF 5500;
BA_ "GenSigStartValue" SG_ 1003 VC_TIRE_CIRCUMF 65535;
BA_ "GenSigSNA" SG_ 1003 VC_TIRE_CIRCUMF "FFFFh";
BA_ "GenSigSendType" SG_ 1003 VC_TIRE_CIRCUMF 5;
BA_ "GenSigCycleTime" SG_ 1003 VC_TIRE_CIRCUMF 1000;
BA_ "FlexKomSigStartValue" SG_ 1003 VC_TIRE_CIRCUMF "FFFFFFFFFFFFFFFFh";
BA_ "FlexKomSigStartPos" SG_ 1003 VC_TIRE_CIRCUMF 7;
BA_ "FlexKomSigName" SG_ 1003 VC_TIRE_CIRCUMF "VehCfg4_Pkt";
BA_ "FlexKomSigLaenge" SG_ 1003 VC_TIRE_CIRCUMF 64;
BA_ "FlexKomSID" SG_ 1003 VC_TIRE_CIRCUMF 1035;
BA_ "FlexKomIsMotorola" SG_ 1003 VC_TIRE_CIRCUMF 1;
BA_ "FlexKomComment" SG_ 1003 VC_TIRE_CIRCUMF "Vehicle Configuration 4 Packet";
BA_ "GenSigTimeout_ORC" SG_ 996 NetCfg_ECM 7000;
BA_ "GenSigTimeout_OCM" SG_ 996 NetCfg_ECM 21000;
BA_ "GenSigTimeout_IC" SG_ 996 NetCfg_ECM 21000;
BA_ "GenSigTimeout_ESM" SG_ 996 NetCfg_ECM 21000;
BA_ "GenSigTimeout_EHPS" SG_ 996 NetCfg_ECM 21000;
BA_ "GenSigTimeout_DTCM" SG_ 996 NetCfg_ECM 21000;
BA_ "GenSigTimeout_DPDM" SG_ 996 NetCfg_ECM 21000;
BA_ "GenSigSNA" SG_ 996 NetCfg_ECM "0h";
BA_ "GenSigSendType" SG_ 996 NetCfg_ECM 5;
BA_ "GenSigCycleTime" SG_ 996 NetCfg_ECM 2000;
BA_ "FlexKomSigStartValue" SG_ 996 NetCfg_ECM "0300000000000000h";
BA_ "FlexKomSigStartPos" SG_ 996 NetCfg_ECM 7;
BA_ "FlexKomSigName" SG_ 996 NetCfg_ECM "NET_CFG_DATA_PT";
BA_ "FlexKomSigLaenge" SG_ 996 NetCfg_ECM 64;
BA_ "FlexKomSID" SG_ 996 NetCfg_ECM 39;
BA_ "FlexKomIsMotorola" SG_ 996 NetCfg_ECM 1;
BA_ "FlexKomComment" SG_ 996 NetCfg_ECM "Network ECU config data for Powertrain";
BA_ "GenSigTimeout_IC" SG_ 996 NetCfg_VSIM_C 21000;
BA_ "GenSigSNA" SG_ 996 NetCfg_VSIM_C "0h";
BA_ "GenSigSendType" SG_ 996 NetCfg_VSIM_C 5;
BA_ "GenSigCycleTime" SG_ 996 NetCfg_VSIM_C 2000;
BA_ "FlexKomSigStartValue" SG_ 996 NetCfg_VSIM_C "0300000000000000h";
BA_ "FlexKomSigStartPos" SG_ 996 NetCfg_VSIM_C 7;
BA_ "FlexKomSigName" SG_ 996 NetCfg_VSIM_C "NET_CFG_DATA_PT";
BA_ "FlexKomSigLaenge" SG_ 996 NetCfg_VSIM_C 64;
BA_ "FlexKomSID" SG_ 996 NetCfg_VSIM_C 39;
BA_ "FlexKomIsMotorola" SG_ 996 NetCfg_VSIM_C 1;
BA_ "FlexKomComment" SG_ 996 NetCfg_VSIM_C "Network ECU config data for Powertrain";
BA_ "RID" SG_ 993 DISPLACEMENT "1899";
BA_ "GenSigTimeout_ORC" SG_ 993 DISPLACEMENT 350;
BA_ "GenSigTimeout_IC" SG_ 993 DISPLACEMENT 1050;
BA_ "GenSigTimeout_ETM" SG_ 993 DISPLACEMENT 1050;
BA_ "GenSigTimeout_DTCM" SG_ 993 DISPLACEMENT 1050;
BA_ "GenSigTimeout_CBC" SG_ 993 DISPLACEMENT 1050;
BA_ "GenSigStartValue" SG_ 993 DISPLACEMENT 255;
BA_ "GenSigSNA" SG_ 993 DISPLACEMENT "FFh";
BA_ "GenSigCycleTime" SG_ 993 DISPLACEMENT 100;
BA_ "FlexKomSigStartValue" SG_ 993 DISPLACEMENT "FFEFE7E7h";
BA_ "FlexKomSigStartPos" SG_ 993 DISPLACEMENT 7;
BA_ "FlexKomSigName" SG_ 993 DISPLACEMENT "ENG_CFG";
BA_ "FlexKomSigLaenge" SG_ 993 DISPLACEMENT 32;
BA_ "FlexKomSID" SG_ 993 DISPLACEMENT 617;
BA_ "FlexKomIsMotorola" SG_ 993 DISPLACEMENT 1;
BA_ "FlexKomComment" SG_ 993 DISPLACEMENT "Engine Configuration Information";
BA_ "GenSigTimeout_ETM" SG_ 993 ENG_ASP 1050;
BA_ "GenSigStartValue" SG_ 993 ENG_ASP 7;
BA_ "GenSigSNA" SG_ 993 ENG_ASP "7h";
BA_ "GenSigCycleTime" SG_ 993 ENG_ASP 100;
BA_ "FlexKomSigStartValue" SG_ 993 ENG_ASP "FFEFE7E7h";
BA_ "FlexKomSigStartPos" SG_ 993 ENG_ASP 7;
BA_ "FlexKomSigName" SG_ 993 ENG_ASP "ENG_CFG";
BA_ "FlexKomSigLaenge" SG_ 993 ENG_ASP 32;
BA_ "FlexKomSID" SG_ 993 ENG_ASP 617;
BA_ "FlexKomIsMotorola" SG_ 993 ENG_ASP 1;
BA_ "FlexKomComment" SG_ 993 ENG_ASP "Engine Configuration Information";
BA_ "GenSigStartValue" SG_ 993 Manufacture 7;
BA_ "GenSigSNA" SG_ 993 Manufacture "7h";
BA_ "GenSigCycleTime" SG_ 993 Manufacture 100;
BA_ "FlexKomSigStartValue" SG_ 993 Manufacture "FFEFE7E7h";
BA_ "FlexKomSigStartPos" SG_ 993 Manufacture 7;
BA_ "FlexKomSigName" SG_ 993 Manufacture "ENG_CFG";
BA_ "FlexKomSigLaenge" SG_ 993 Manufacture 32;
BA_ "FlexKomSID" SG_ 993 Manufacture 617;
BA_ "FlexKomIsMotorola" SG_ 993 Manufacture 1;
BA_ "FlexKomComment" SG_ 993 Manufacture "Engine Configuration Information";
BA_ "RID" SG_ 993 TRANS_TYPE "1094";
BA_ "FlexKomSID" SG_ 333 GF_Charge 1093;
BA_ "FlexKomIsMotorola" SG_ 333 GF_Charge 1;
BA_ "FlexKomComment" SG_ 333 GF_Charge "EDR2 information packet only";
BA_ "GenSigSNA" SG_ 516 MKKey2org22 "0h";
BA_ "GenSigSendType" SG_ 516 MKKey2org22 1;
BA_ "FlexKomSigStartValue" SG_ 516 MKKey2org22 "00000000000000h";
BA_ "FlexKomSigStartPos" SG_ 516 MKKey2org22 7;
BA_ "FlexKomSigName" SG_ 516 MKKey2org22 "IMMO_CODE_RESPONSE";
BA_ "FlexKomSigLaenge" SG_ 516 MKKey2org22 56;
BA_ "FlexKomSID" SG_ 516 MKKey2org22 2110;
BA_ "FlexKomIsMotorola" SG_ 516 MKKey2org22 1;
BA_ "FlexKomComment" SG_ 516 MKKey2org22 "Immobilizer code response packet";
BA_ "FlexKomSigLaenge" SG_ 1013 EC_Powertrain 16;
BA_ "GenSigSNA" SG_ 516 MKKey_5 "0h";
BA_ "GenSigSendType" SG_ 516 MKKey_5 1;
BA_ "FlexKomSigStartValue" SG_ 516 MKKey_5 "00000000000000h";
BA_ "FlexKomSigStartPos" SG_ 516 MKKey_5 7;
BA_ "FlexKomSigName" SG_ 516 MKKey_5 "IMMO_CODE_RESPONSE";
BA_ "FlexKomSigLaenge" SG_ 516 MKKey_5 56;
BA_ "FlexKomSID" SG_ 516 MKKey_5 2110;
BA_ "FlexKomIsMotorola" SG_ 516 MKKey_5 1;
BA_ "FlexKomComment" SG_ 516 MKKey_5 "Immobilizer code response packet";
BA_ "GenSigSNA" SG_ 516 MKKey1org21 "0h";
BA_ "GenSigSendType" SG_ 516 MKKey1org21 1;
BA_ "FlexKomSigStartValue" SG_ 516 MKKey1org21 "00000000000000h";
BA_ "FlexKomSigStartPos" SG_ 516 MKKey1org21 7;
BA_ "FlexKomSigName" SG_ 516 MKKey1org21 "IMMO_CODE_RESPONSE";
BA_ "FlexKomSigLaenge" SG_ 516 MKKey1org21 56;
BA_ "FlexKomSID" SG_ 516 MKKey1org21 2110;
BA_ "FlexKomIsMotorola" SG_ 516 MKKey1org21 1;
BA_ "FlexKomComment" SG_ 516 MKKey1org21 "Immobilizer code response packet";
BA_ "GenSigSNA" SG_ 517 f1_1 "0h";
BA_ "GenSigSendType" SG_ 517 f1_1 1;
BA_ "FlexKomSigStartValue" SG_ 517 f1_1 "00000000000000h";
BA_ "FlexKomSigStartPos" SG_ 517 f1_1 7;
BA_ "FlexKomSigName" SG_ 517 f1_1 "IMMO_CODE_REQUEST";
BA_ "FlexKomSigLaenge" SG_ 517 f1_1 56;
BA_ "FlexKomSID" SG_ 517 f1_1 2111;
BA_ "FlexKomIsMotorola" SG_ 517 f1_1 1;
BA_ "FlexKomComment" SG_ 517 f1_1 "Immobilizer code request packet";
BA_ "RID" SG_ 910 IBS3_SOF_Q_Accuracy "5133";
BA_ "GenSigSNA" SG_ 910 IBS3_SOF_Q_Accuracy "0h";
BA_ "GenSigCycleTime" SG_ 910 IBS3_SOF_Q_Accuracy 2000;
BA_ "FlexKomSigStartValue" SG_ 910 IBS3_SOF_Q_Accuracy "00FFFF7F7F80h";
BA_ "FlexKomSigStartPos" SG_ 910 IBS3_SOF_Q_Accuracy 23;
BA_ "FlexKomSigName" SG_ 910 IBS3_SOF_Q_Accuracy "GW_LIN_I_C6_Pkt2";
BA_ "FlexKomSigLaenge" SG_ 910 IBS3_SOF_Q_Accuracy 48;
BA_ "FlexKomSID" SG_ 910 IBS3_SOF_Q_Accuracy 2657;
BA_ "FlexKomIsMotorola" SG_ 910 IBS3_SOF_Q_Accuracy 1;
BA_ "FlexKomComment" SG_ 910 IBS3_SOF_Q_Accuracy "Cyclic only";
BA_ "RID" SG_ 910 IBS3_SOC "5121";
BA_ "GenSigStartValue" SG_ 910 IBS3_SOC 127;
BA_ "GenSigSNA" SG_ 910 IBS3_SOC "7Fh";
BA_ "GenSigCycleTime" SG_ 910 IBS3_SOC 2000;
BA_ "FlexKomSigStartValue" SG_ 910 IBS3_SOC "00FFFF7F7F80h";
BA_ "FlexKomSigStartPos" SG_ 910 IBS3_SOC 23;
BA_ "FlexKomSigName" SG_ 910 IBS3_SOC "GW_LIN_I_C6_Pkt2";
BA_ "FlexKomSigLaenge" SG_ 910 IBS3_SOC 48;
BA_ "FlexKomSID" SG_ 910 IBS3_SOC 2657;
BA_ "FlexKomIsMotorola" SG_ 910 IBS3_SOC 1;
BA_ "FlexKomComment" SG_ 910 IBS3_SOC "Cyclic only";
BA_ "RID" SG_ 910 IBS3_T_BATT "5105";
BA_ "GenSigStartValue" SG_ 910 IBS3_T_BATT 255;
BA_ "GenSigSNA" SG_ 910 IBS3_T_BATT "FFh";
BA_ "GenSigCycleTime" SG_ 910 IBS3_T_BATT 2000;
BA_ "FlexKomSigStartValue" SG_ 910 IBS3_T_BATT "00FFFF7F7F80h";
BA_ "FlexKomSigStartPos" SG_ 910 IBS3_T_BATT 23;
BA_ "FlexKomSigName" SG_ 910 IBS3_T_BATT "GW_LIN_I_C6_Pkt2";
BA_ "FlexKomSigLaenge" SG_ 910 IBS3_T_BATT 48;
BA_ "FlexKomSID" SG_ 910 IBS3_T_BATT 2657;
BA_ "FlexKomIsMotorola" SG_ 910 IBS3_T_BATT 1;
BA_ "FlexKomComment" SG_ 910 IBS3_T_BATT "Cyclic only";
BA_ "FlexKomComment" SG_ 1000 VC_BODY_STYLE "Vehicle Configuration 1 Packet";
BA_ "GenSigTimeout_ORC" SG_ 1001 VC_CRUISE_PRSNT 7000;
BA_ "GenSigTimeout_IC" SG_ 1001 VC_CRUISE_PRSNT 21000;
BA_ "GenSigSNA" SG_ 1001 VC_CRUISE_PRSNT "0h";
BA_ "GenSigSendType" SG_ 1001 VC_CRUISE_PRSNT 5;
BA_ "GenSigCycleTime" SG_ 1001 VC_CRUISE_PRSNT 2000;
BA_ "FlexKomSigStartValue" SG_ 1001 VC_CRUISE_PRSNT "0300FF00FFFFFFFFh";
BA_ "FlexKomSigStartPos" SG_ 1001 VC_CRUISE_PRSNT 7;
BA_ "FlexKomSigName" SG_ 1001 VC_CRUISE_PRSNT "VehCfg2_Pkt";
BA_ "FlexKomSigLaenge" SG_ 1001 VC_CRUISE_PRSNT 64;
BA_ "FlexKomSID" SG_ 1001 VC_CRUISE_PRSNT 887;
BA_ "FlexKomIsMotorola" SG_ 1001 VC_CRUISE_PRSNT 1;
BA_ "FlexKomComment" SG_ 1001 VC_CRUISE_PRSNT "Vehicle Configuration 2 Packet";
BA_ "GenSigSNA" SG_ 936 ECM_APPL7 "0h";
BA_ "GenSigSendType" SG_ 936 ECM_APPL7 1;
BA_ "FlexKomSigStartValue" SG_ 936 ECM_APPL7 "0000000000000000h";
BA_ "FlexKomSigStartPos" SG_ 936 ECM_APPL7 7;
BA_ "FlexKomSigName" SG_ 936 ECM_APPL7 "ECM_APPL7";
BA_ "FlexKomSigLaenge" SG_ 936 ECM_APPL7 64;
BA_ "FlexKomSID" SG_ 936 ECM_APPL7 1111;
BA_ "FlexKomIsMotorola" SG_ 936 ECM_APPL7 1;
BA_ "FlexKomComment" SG_ 936 ECM_APPL7 "Application";
BA_ "GenSigSNA" SG_ 177 CruiseControlOnOffSts "0h";
BA_ "GenSigSendType" SG_ 177 CruiseControlOnOffSts 1;
BA_ "FlexKomSigStartValue" SG_ 177 CruiseControlOnOffSts "0000FFh";
BA_ "FlexKomSigStartPos" SG_ 177 CruiseControlOnOffSts 7;
BA_ "FlexKomSigName" SG_ 177 CruiseControlOnOffSts "CrsCtrlLvrSts";
BA_ "FlexKomSigLaenge" SG_ 177 CruiseControlOnOffSts 24;
BA_ "FlexKomSID" SG_ 177 CruiseControlOnOffSts 1848;
BA_ "FlexKomIsMotorola" SG_ 177 CruiseControlOnOffSts 1;
BA_ "FlexKomComment" SG_ 177 CruiseControlOnOffSts "Cruise Control Lever Status";
BA_ "GenSigSNA" SG_ 177 SpeedLimiterOnOffSts "0h";
BA_ "GenSigSendType" SG_ 177 SpeedLimiterOnOffSts 1;
BA_ "FlexKomSigStartValue" SG_ 177 SpeedLimiterOnOffSts "0000FFh";
BA_ "FlexKomSigStartPos" SG_ 177 SpeedLimiterOnOffSts 7;
BA_ "FlexKomSigName" SG_ 177 SpeedLimiterOnOffSts "CrsCtrlLvrSts";
BA_ "FlexKomSigLaenge" SG_ 177 SpeedLimiterOnOffSts 24;
BA_ "FlexKomSID" SG_ 177 SpeedLimiterOnOffSts 1848;
BA_ "FlexKomIsMotorola" SG_ 177 SpeedLimiterOnOffSts 1;
BA_ "FlexKomComment" SG_ 177 SpeedLimiterOnOffSts "Cruise Control Lever Status";
BA_ "GenSigSNA" SG_ 173 MC_SBW_ROT1 "0h";
BA_ "GenSigSNA" SG_ 996 NetCfg_EPB "0h";
BA_ "GenSigSendType" SG_ 996 NetCfg_EPB 5;
BA_ "GenSigCycleTime" SG_ 996 NetCfg_EPB 2000;
BA_ "FlexKomSigStartValue" SG_ 996 NetCfg_EPB "0300000000000000h";
BA_ "FlexKomSigStartPos" SG_ 996 NetCfg_EPB 7;
BA_ "FlexKomSigName" SG_ 996 NetCfg_EPB "NET_CFG_DATA_PT";
BA_ "FlexKomSigLaenge" SG_ 996 NetCfg_EPB 64;
BA_ "FlexKomSID" SG_ 996 NetCfg_EPB 39;
BA_ "FlexKomIsMotorola" SG_ 996 NetCfg_EPB 1;
BA_ "FlexKomComment" SG_ 996 NetCfg_EPB "Network ECU config data for Powertrain";
BA_ "GenSigTimeout_ORC" SG_ 996 NetCfg_DASM 7000;
BA_ "GenSigTimeout_IC" SG_ 996 NetCfg_DASM 21000;
BA_ "GenSigSNA" SG_ 996 NetCfg_DASM "0h";
BA_ "GenSigSendType" SG_ 996 NetCfg_DASM 5;
BA_ "GenSigCycleTime" SG_ 996 NetCfg_DASM 2000;
BA_ "FlexKomSigStartValue" SG_ 996 NetCfg_DASM "0300000000000000h";
BA_ "FlexKomSigStartPos" SG_ 996 NetCfg_DASM 7;
BA_ "FlexKomSigName" SG_ 996 NetCfg_DASM "NET_CFG_DATA_PT";
BA_ "FlexKomSigLaenge" SG_ 996 NetCfg_DASM 64;
BA_ "FlexKomSID" SG_ 996 NetCfg_DASM 39;
BA_ "FlexKomIsMotorola" SG_ 996 NetCfg_DASM 1;
BA_ "FlexKomComment" SG_ 996 NetCfg_DASM "Network ECU config data for Powertrain";
BA_ "GenSigTimeout_ORC" SG_ 1098 VC_SpdLmt_PRSNT 7000;
BA_ "GenSigTimeout_IC" SG_ 1098 VC_SpdLmt_PRSNT 21000;
BA_ "GenSigSNA" SG_ 1098 VC_SpdLmt_PRSNT "0h";
BA_ "GenSigSendType" SG_ 1098 VC_SpdLmt_PRSNT 5;
BA_ "GenSigCycleTime" SG_ 1098 VC_SpdLmt_PRSNT 2000;
BA_ "FlexKomSigStartValue" SG_ 1098 VC_SpdLmt_PRSNT "C3FFFFFFFFFFFF00h";
BA_ "FlexKomSigStartPos" SG_ 1098 VC_SpdLmt_PRSNT 7;
BA_ "FlexKomSigName" SG_ 1098 VC_SpdLmt_PRSNT "VehCfg5_Pkt";
BA_ "FlexKomSigLaenge" SG_ 1098 VC_SpdLmt_PRSNT 64;
BA_ "FlexKomSID" SG_ 1098 VC_SpdLmt_PRSNT 1198;
BA_ "FlexKomIsMotorola" SG_ 1098 VC_SpdLmt_PRSNT 1;
BA_ "FlexKomComment" SG_ 1098 VC_SpdLmt_PRSNT "Vehicle Configuration 5 Packet";
BA_ "GenSigStartValue" SG_ 55 EngTrqRq 8191;
BA_ "GenSigSNA" SG_ 55 EngTrqRq "1FFFh";
BA_ "GenSigCycleTime" SG_ 55 EngTrqRq 10;
BA_ "FlexKomSigStartValue" SG_ 55 EngTrqRq "1FFF1FFF1FFF00FFh";
BA_ "FlexKomSigStartPos" SG_ 55 EngTrqRq 7;
BA_ "FlexKomSigName" SG_ 55 EngTrqRq "TCM_EngTrq2_Pkt";
BA_ "FlexKomSigLaenge" SG_ 55 EngTrqRq 64;
BA_ "FlexKomSID" SG_ 55 EngTrqRq 1379;
BA_ "FlexKomIsMotorola" SG_ 55 EngTrqRq 1;
BA_ "FlexKomComment" SG_ 55 EngTrqRq "Engine Torque Pkt";
BA_ "GenSigSNA" SG_ 55 MC_TCM_EngTrq2 "0h";
BA_ "GenSigCycleTime" SG_ 55 MC_TCM_EngTrq2 10;
BA_ "FlexKomSigStartValue" SG_ 55 MC_TCM_EngTrq2 "1FFF1FFF1FFF00FFh";
BA_ "FlexKomSigStartPos" SG_ 55 MC_TCM_EngTrq2 7;
BA_ "FlexKomSigName" SG_ 55 MC_TCM_EngTrq2 "TCM_EngTrq2_Pkt";
BA_ "FlexKomSigLaenge" SG_ 55 MC_TCM_EngTrq2 64;
BA_ "FlexKomSID" SG_ 55 MC_TCM_EngTrq2 1379;
BA_ "FlexKomIsMotorola" SG_ 55 MC_TCM_EngTrq2 1;
BA_ "FlexKomComment" SG_ 55 MC_TCM_EngTrq2 "Engine Torque Pkt";
BA_ "GenSigSNA" SG_ 149 MC_TCM_ENG_TRQ "0h";
BA_ "GenSigCycleTime" SG_ 149 MC_TCM_ENG_TRQ 20;
BA_ "FlexKomSigStartValue" SG_ 149 MC_TCM_ENG_TRQ "07FF001FFF00FFh";
BA_ "FlexKomSigStartPos" SG_ 149 MC_TCM_ENG_TRQ 7;
BA_ "FlexKomSigName" SG_ 149 MC_TCM_ENG_TRQ "ENG_TRQ_PKT";
BA_ "FlexKomSigLaenge" SG_ 149 MC_TCM_ENG_TRQ 56;
BA_ "FlexKomSID" SG_ 149 MC_TCM_ENG_TRQ 788;
BA_ "FlexKomIsMotorola" SG_ 149 MC_TCM_ENG_TRQ 1;
BA_ "FlexKomComment" SG_ 149 MC_TCM_ENG_TRQ "Engine torque packet for all transmissions";
BA_ "FlexKomSID" SG_ 1013 EC_Powertrain 890;
BA_ "FlexKomIsMotorola" SG_ 1013 EC_Powertrain 1;
BA_ "FlexKomComment" SG_ 1013 EC_Powertrain "Powertrain ecu configuration";
BA_ "RID" SG_ 993 SpStPrsnt "1164";
BA_ "GenSigTimeout_CBC" SG_ 171 TX_WARN2 210;
BA_ "GenSigSNA" SG_ 171 TX_WARN2 "FFh";
BA_ "GenSigCycleTime" SG_ 171 TX_WARN2 20;
BA_ "FlexKomSigStartValue" SG_ 171 TX_WARN2 "0FFF0F0F000000FFh";
BA_ "FlexKomSigStartPos" SG_ 171 TX_WARN2 7;
BA_ "FlexKomSigName" SG_ 171 TX_WARN2 "TCM_A7_PKT";
BA_ "FlexKomSigLaenge" SG_ 171 TX_WARN2 64;
BA_ "FlexKomSID" SG_ 171 TX_WARN2 1613;
BA_ "FlexKomIsMotorola" SG_ 171 TX_WARN2 1;
BA_ "FlexKomComment" SG_ 171 TX_WARN2 "Transmission message A7 packet";
BA_ "RID" SG_ 35 LRW "1020 1197";
BA_ "GenSigTimeout_ORC" SG_ 35 LRW 35;
BA_ "GenSigTimeout_IC" SG_ 35 LRW 105;
BA_ "GenSigSNA" SG_ 47 BrkPdlRawStat "0h";
BA_ "GenSigCycleTime" SG_ 47 BrkPdlRawStat 10;
BA_ "FlexKomSigStartValue" SG_ 47 BrkPdlRawStat "0000h";
BA_ "FlexKomSigStartPos" SG_ 47 BrkPdlRawStat 39;
BA_ "FlexKomSigName" SG_ 47 BrkPdlRawStat "BrkPdlRawStat";
BA_ "FlexKomSigLaenge" SG_ 47 BrkPdlRawStat 16;
BA_ "FlexKomSID" SG_ 47 BrkPdlRawStat 2437;
BA_ "FlexKomIsMotorola" SG_ 47 BrkPdlRawStat 1;
BA_ "FlexKomComment" SG_ 47 BrkPdlRawStat "Brake pedal state raw value";
BA_ "GenSigSNA" SG_ 293 TransReadyForESS "0h";
BA_ "GenSigCycleTime" SG_ 293 TransReadyForESS 100;
BA_ "FlexKomSigStartValue" SG_ 293 TransReadyForESS "00h";
BA_ "FlexKomSigStartPos" SG_ 293 TransReadyForESS 22;
BA_ "FlexKomSigName" SG_ 293 TransReadyForESS "TransReadyForESS";
BA_ "FlexKomSigLaenge" SG_ 293 TransReadyForESS 1;
BA_ "FlexKomSID" SG_ 293 TransReadyForESS 1665;
BA_ "FlexKomIsMotorola" SG_ 293 TransReadyForESS 1;
BA_ "FlexKomComment" SG_ 293 TransReadyForESS "Trans ready for auto stop (0= not ready)";
BA_ "GenSigTimeout_ESM" SG_ 293 TX_FAULT 1050;
BA_ "GenSigSNA" SG_ 293 TX_FAULT "3h";
BA_ "GenSigCycleTime" SG_ 293 TX_FAULT 100;
BA_ "FlexKomSigStartValue" SG_ 293 TX_FAULT "00h";
BA_ "FlexKomSigStartPos" SG_ 293 TX_FAULT 21;
BA_ "FlexKomSigName" SG_ 293 TX_FAULT "TX_FAULT";
BA_ "FlexKomSigLaenge" SG_ 293 TX_FAULT 2;
BA_ "FlexKomSID" SG_ 293 TX_FAULT 1364;
BA_ "FlexKomIsMotorola" SG_ 293 TX_FAULT 1;
BA_ "FlexKomComment" SG_ 293 TX_FAULT "Transmission fault";
BA_ "RID" SG_ 792 WprWash_R_Sw_Posn_V3 "1224";
BA_ "GenSigTimeout_ESM" SG_ 147 MC_TRNS_STAT 410;
BA_ "GenSigSNA" SG_ 147 MC_TRNS_STAT "0h";
BA_ "GenSigCycleTime" SG_ 147 MC_TRNS_STAT 20;
BA_ "FlexKomSigStartValue" SG_ 147 MC_TRNS_STAT "1CFFFF00000000FFh";
BA_ "FlexKomSigStartPos" SG_ 147 MC_TRNS_STAT 7;
BA_ "FlexKomSigName" SG_ 147 MC_TRNS_STAT "TRNS_STAT_PKT";
BA_ "FlexKomSigLaenge" SG_ 147 MC_TRNS_STAT 64;
BA_ "FlexKomSID" SG_ 147 MC_TRNS_STAT 1366;
BA_ "FlexKomIsMotorola" SG_ 147 MC_TRNS_STAT 1;
BA_ "FlexKomComment" SG_ 147 MC_TRNS_STAT "TRNS_STAT message packet";
BA_ "GenSigSNA" SG_ 133 K_G_B "0h";
BA_ "GenSigCycleTime" SG_ 133 K_G_B 20;
BA_ "FlexKomSigStartValue" SG_ 133 K_G_B "000000h";
BA_ "FlexKomSigStartPos" SG_ 133 K_G_B 7;
BA_ "FlexKomSigName" SG_ 133 K_G_B "K_B";
BA_ "FlexKomSigLaenge" SG_ 133 K_G_B 24;
BA_ "FlexKomSID" SG_ 133 K_G_B 1129;
BA_ "FlexKomIsMotorola" SG_ 133 K_G_B 1;
BA_ "FlexKomComment" SG_ 133 K_G_B "Torque converter lock-up status";
BA_ "GenSigSNA" SG_ 133 TRNS_SPD_MC "0h";
BA_ "GenSigCycleTime" SG_ 133 TRNS_SPD_MC 20;
BA_ "FlexKomSigStartValue" SG_ 133 TRNS_SPD_MC "00h";
BA_ "FlexKomSigStartPos" SG_ 133 TRNS_SPD_MC 61;
BA_ "FlexKomSigName" SG_ 133 TRNS_SPD_MC "TRNS_SPD_MC";
BA_ "FlexKomSigLaenge" SG_ 133 TRNS_SPD_MC 4;
BA_ "FlexKomSID" SG_ 133 TRNS_SPD_MC 2607;
BA_ "FlexKomIsMotorola" SG_ 133 TRNS_SPD_MC 1;
BA_ "FlexKomComment" SG_ 133 TRNS_SPD_MC "TRNS_SPD message counter";
BA_ "GenSigStartValue" SG_ 133 OUTPUT_SPEED 65535;
BA_ "GenSigSNA" SG_ 133 OUTPUT_SPEED "FFFFh";
BA_ "GenSigCycleTime" SG_ 133 OUTPUT_SPEED 20;
BA_ "FlexKomSigStartValue" SG_ 133 OUTPUT_SPEED "FFFF000000h";
BA_ "FlexKomSigStartPos" SG_ 133 OUTPUT_SPEED 31;
BA_ "FlexKomSigName" SG_ 133 OUTPUT_SPEED "OutputSpdPkt";
BA_ "FlexKomSigLaenge" SG_ 133 OUTPUT_SPEED 40;
BA_ "FlexKomSID" SG_ 133 OUTPUT_SPEED 1605;
BA_ "FlexKomIsMotorola" SG_ 133 OUTPUT_SPEED 1;
BA_ "FlexKomComment" SG_ 133 OUTPUT_SPEED "Output shaft speed packet";
BA_ "RID" SG_ 133 TCM_ManMd "1696";
BA_ "GenSigTimeout_IC" SG_ 133 TCM_ManMd 210;
BA_ "GenSigSNA" SG_ 133 TCM_ManMd "0h";
BA_ "GenSigCycleTime" SG_ 133 TCM_ManMd 20;
BA_ "FlexKomSigStartValue" SG_ 133 TCM_ManMd "00h";
BA_ "FlexKomSigStartPos" SG_ 133 TCM_ManMd 63;
BA_ "FlexKomSigName" SG_ 133 TCM_ManMd "ManualMdPkt";
BA_ "FlexKomSigLaenge" SG_ 133 TCM_ManMd 2;
BA_ "FlexKomSID" SG_ 133 TCM_ManMd 1762;
BA_ "FlexKomIsMotorola" SG_ 133 TCM_ManMd 1;
BA_ "FlexKomComment" SG_ 133 TCM_ManMd "Manual mode packet";
BA_ "GenSigSNA" SG_ 850 ECM_APPL2 "0h";
BA_ "GenSigSendType" SG_ 850 ECM_APPL2 1;
BA_ "FlexKomSigStartValue" SG_ 850 ECM_APPL2 "0000000000000000h";
BA_ "FlexKomSigStartPos" SG_ 850 ECM_APPL2 7;
BA_ "FlexKomSigName" SG_ 850 ECM_APPL2 "ECM_APPL2";
BA_ "FlexKomSigLaenge" SG_ 850 ECM_APPL2 64;
BA_ "FlexKomSID" SG_ 850 ECM_APPL2 1110;
BA_ "FlexKomIsMotorola" SG_ 850 ECM_APPL2 1;
BA_ "FlexKomComment" SG_ 850 ECM_APPL2 "Application";
BA_ "GenSigTimeout_ORC" SG_ 897 VC_VehCfg7_Stat 7000;
BA_ "GenSigTimeout_IC" SG_ 897 VC_VehCfg7_Stat 21000;
BA_ "GenSigStartValue" SG_ 897 VC_VehCfg7_Stat 3;
BA_ "GenSigSNA" SG_ 897 VC_VehCfg7_Stat "3h";
BA_ "GenSigSendType" SG_ 897 VC_VehCfg7_Stat 5;
BA_ "GenSigCycleTime" SG_ 897 VC_VehCfg7_Stat 2000;
BA_ "FlexKomSigStartValue" SG_ 897 VC_VehCfg7_Stat "033F000000000000h";
BA_ "FlexKomSigStartPos" SG_ 897 VC_VehCfg7_Stat 7;
BA_ "FlexKomSigName" SG_ 897 VC_VehCfg7_Stat "VehCfg7_Pkt";
BA_ "FlexKomSigLaenge" SG_ 897 VC_VehCfg7_Stat 64;
BA_ "FlexKomSID" SG_ 897 VC_VehCfg7_Stat 2026;
BA_ "FlexKomIsMotorola" SG_ 897 VC_VehCfg7_Stat 1;
BA_ "FlexKomComment" SG_ 897 VC_VehCfg7_Stat "Vehicle Configuration 7 Packet";
BA_ "GenSigSNA" SG_ 1100 VC_AnlgDrSnsr "0h";
BA_ "GenSigSendType" SG_ 1100 VC_AnlgDrSnsr 5;
BA_ "GenSigCycleTime" SG_ 1100 VC_AnlgDrSnsr 2000;
BA_ "FlexKomSigStartValue" SG_ 1100 VC_AnlgDrSnsr "73FFFFFFFFFFFFFFh";
BA_ "FlexKomSigStartPos" SG_ 1100 VC_AnlgDrSnsr 7;
BA_ "FlexKomSigName" SG_ 1100 VC_AnlgDrSnsr "VehCfg6_Pkt";
BA_ "FlexKomSigLaenge" SG_ 1100 VC_AnlgDrSnsr 64;
BA_ "FlexKomSID" SG_ 1100 VC_AnlgDrSnsr 1199;
BA_ "FlexKomIsMotorola" SG_ 1100 VC_AnlgDrSnsr 1;
BA_ "FlexKomComment" SG_ 1100 VC_AnlgDrSnsr "Vehicle Configuration 6 Packet";
BA_ "GenSigSNA" SG_ 912 ECM_APPL5 "0h";
BA_ "GenSigSendType" SG_ 912 ECM_APPL5 1;
BA_ "FlexKomSigStartValue" SG_ 912 ECM_APPL5 "0000000000000000h";
BA_ "FlexKomSigStartPos" SG_ 912 ECM_APPL5 7;
BA_ "FlexKomSigName" SG_ 912 ECM_APPL5 "ECM_APPL5";
BA_ "FlexKomSigLaenge" SG_ 912 ECM_APPL5 64;
BA_ "FlexKomSID" SG_ 912 ECM_APPL5 783;
BA_ "FlexKomIsMotorola" SG_ 912 ECM_APPL5 1;
BA_ "FlexKomComment" SG_ 912 ECM_APPL5 "CCP 10ms DAQ  (from ENGINE to external tool)";
BA_ "RID" SG_ 788 CFG_FEATURE "1144";
BA_ "GenSigSNA" SG_ 788 CFG_FEATURE "0h";
BA_ "GenSigSendType" SG_ 788 CFG_FEATURE 2;
BA_ "GenSigCycleTimeActive" SG_ 788 CFG_FEATURE 50;
BA_ "FlexKomSigStartValue" SG_ 788 CFG_FEATURE "000000h";
BA_ "GenSigSNA" SG_ 792 WprWash_R_Sw_Posn_V3 "0h";
BA_ "GenSigSendType" SG_ 792 WprWash_R_Sw_Posn_V3 5;
BA_ "GenSigCycleTime" SG_ 792 WprWash_R_Sw_Posn_V3 100;
BA_ "FlexKomSigStartValue" SG_ 792 WprWash_R_Sw_Posn_V3 "000000000000FF00h";
BA_ "FlexKomSigStartPos" SG_ 792 WprWash_R_Sw_Posn_V3 7;
BA_ "FlexKomSigName" SG_ 792 WprWash_R_Sw_Posn_V3 "StW_Actn_Rq";
BA_ "FlexKomSigLaenge" SG_ 792 WprWash_R_Sw_Posn_V3 64;
BA_ "FlexKomSID" SG_ 792 WprWash_R_Sw_Posn_V3 420;
BA_ "FlexKomIsMotorola" SG_ 792 WprWash_R_Sw_Posn_V3 1;
BA_ "FlexKomComment" SG_ 792 WprWash_R_Sw_Posn_V3 "Steering wheel actuation request";
BA_ "GenSigSNA" SG_ 897 VC_PTCPrsnt "0h";
BA_ "GenSigSendType" SG_ 897 VC_PTCPrsnt 5;
BA_ "GenSigCycleTime" SG_ 897 VC_PTCPrsnt 2000;
BA_ "FlexKomSigStartValue" SG_ 897 VC_PTCPrsnt "033F000000000000h";
BA_ "FlexKomSigStartPos" SG_ 897 VC_PTCPrsnt 7;
BA_ "FlexKomSigName" SG_ 897 VC_PTCPrsnt "VehCfg7_Pkt";
BA_ "FlexKomSigLaenge" SG_ 897 VC_PTCPrsnt 64;
BA_ "FlexKomSID" SG_ 897 VC_PTCPrsnt 2026;
BA_ "FlexKomIsMotorola" SG_ 897 VC_PTCPrsnt 1;
BA_ "FlexKomComment" SG_ 897 VC_PTCPrsnt "Vehicle Configuration 7 Packet";
BA_ "GenSigTimeout_RF_HUB" SG_ 995 NET_CFG_STAT_INT 21000;
BA_ "GenSigTimeout_IC" SG_ 995 NET_CFG_STAT_INT 21000;
BA_ "GenSigStartValue" SG_ 995 NET_CFG_STAT_INT 3;
BA_ "GenSigSNA" SG_ 995 NET_CFG_STAT_INT "3h";
BA_ "GenSigSendType" SG_ 995 NET_CFG_STAT_INT 5;
BA_ "GenSigCycleTime" SG_ 995 NET_CFG_STAT_INT 2000;
BA_ "FlexKomSigStartValue" SG_ 995 NET_CFG_STAT_INT "0300000000000000h";
BA_ "FlexKomSigStartPos" SG_ 995 NET_CFG_STAT_INT 7;
BA_ "FlexKomSigName" SG_ 995 NET_CFG_STAT_INT "NET_CFG_DATA_INT";
BA_ "FlexKomSigLaenge" SG_ 995 NET_CFG_STAT_INT 64;
BA_ "FlexKomSID" SG_ 995 NET_CFG_STAT_INT 38;
BA_ "FlexKomIsMotorola" SG_ 995 NET_CFG_STAT_INT 1;
BA_ "FlexKomComment" SG_ 995 NET_CFG_STAT_INT "Network ECU config data for interior";
BA_ "GenSigTimeout_ORC" SG_ 996 NetCfg_TCM 7000;
BA_ "GenSigTimeout_IC" SG_ 996 NetCfg_TCM 21000;
BA_ "GenSigTimeout_ESM" SG_ 996 NetCfg_TCM 21000;
BA_ "GenSigTimeout_DTCM" SG_ 996 NetCfg_TCM 21000;
BA_ "GenSigSNA" SG_ 996 NetCfg_TCM "0h";
BA_ "GenSigSendType" SG_ 996 NetCfg_TCM 5;
BA_ "GenSigCycleTime" SG_ 996 NetCfg_TCM 2000;
BA_ "FlexKomSigStartValue" SG_ 996 NetCfg_TCM "0300000000000000h";
BA_ "FlexKomSigStartPos" SG_ 996 NetCfg_TCM 7;
BA_ "FlexKomSigName" SG_ 996 NetCfg_TCM "NET_CFG_DATA_PT";
BA_ "FlexKomSigLaenge" SG_ 996 NetCfg_TCM 64;
BA_ "FlexKomSID" SG_ 996 NetCfg_TCM 39;
BA_ "FlexKomIsMotorola" SG_ 996 NetCfg_TCM 1;
BA_ "FlexKomComment" SG_ 996 NetCfg_TCM "Network ECU config data for Powertrain";
BA_ "GenSigTimeout_TCM" SG_ 1003 VC_TCASE_HI_RATIO 3500;
BA_ "GenSigStartValue" SG_ 1003 VC_TCASE_HI_RATIO 16383;
BA_ "GenSigSNA" SG_ 1003 VC_TCASE_HI_RATIO "3FFFh";
BA_ "GenSigSendType" SG_ 1003 VC_TCASE_HI_RATIO 5;
BA_ "GenSigCycleTime" SG_ 1003 VC_TCASE_HI_RATIO 1000;
BA_ "FlexKomSigStartValue" SG_ 1003 VC_TCASE_HI_RATIO "FFFFFFFFFFFFFFFFh";
BA_ "FlexKomSigStartPos" SG_ 1003 VC_TCASE_HI_RATIO 7;
BA_ "FlexKomSigName" SG_ 1003 VC_TCASE_HI_RATIO "VehCfg4_Pkt";
BA_ "FlexKomSigLaenge" SG_ 1003 VC_TCASE_HI_RATIO 64;
BA_ "FlexKomSID" SG_ 1003 VC_TCASE_HI_RATIO 1035;
BA_ "FlexKomIsMotorola" SG_ 1003 VC_TCASE_HI_RATIO 1;
BA_ "FlexKomComment" SG_ 1003 VC_TCASE_HI_RATIO "Vehicle Configuration 4 Packet";
BA_ "GenSigTimeout_TCM" SG_ 1003 VC_TCASE_LO_RATIO 3500;
BA_ "GenSigStartValue" SG_ 1003 VC_TCASE_LO_RATIO 65535;
BA_ "GenSigSNA" SG_ 1003 VC_TCASE_LO_RATIO "FFFFh";
BA_ "GenSigSendType" SG_ 1003 VC_TCASE_LO_RATIO 5;
BA_ "GenSigCycleTime" SG_ 1003 VC_TCASE_LO_RATIO 1000;
BA_ "FlexKomSigStartValue" SG_ 1003 VC_TCASE_LO_RATIO "FFFFFFFFFFFFFFFFh";
BA_ "FlexKomSigStartPos" SG_ 1003 VC_TCASE_LO_RATIO 7;
BA_ "FlexKomSigName" SG_ 1003 VC_TCASE_LO_RATIO "VehCfg4_Pkt";
BA_ "FlexKomSigLaenge" SG_ 1003 VC_TCASE_LO_RATIO 64;
BA_ "FlexKomSID" SG_ 1003 VC_TCASE_LO_RATIO 1035;
BA_ "FlexKomIsMotorola" SG_ 1003 VC_TCASE_LO_RATIO 1;
BA_ "FlexKomComment" SG_ 1003 VC_TCASE_LO_RATIO "Vehicle Configuration 4 Packet";
BA_ "GenSigTimeout_DPDM" SG_ 996 NetCfg_CBC_PT 21000;
BA_ "GenSigSNA" SG_ 996 NetCfg_CBC_PT "0h";
BA_ "GenSigSendType" SG_ 996 NetCfg_CBC_PT 5;
BA_ "GenSigCycleTime" SG_ 996 NetCfg_CBC_PT 2000;
BA_ "FlexKomSigStartValue" SG_ 996 NetCfg_CBC_PT "0300000000000000h";
BA_ "FlexKomSigStartPos" SG_ 996 NetCfg_CBC_PT 7;
BA_ "FlexKomSigName" SG_ 996 NetCfg_CBC_PT "NET_CFG_DATA_PT";
BA_ "FlexKomSigLaenge" SG_ 996 NetCfg_CBC_PT 64;
BA_ "FlexKomSID" SG_ 996 NetCfg_CBC_PT 39;
BA_ "FlexKomIsMotorola" SG_ 996 NetCfg_CBC_PT 1;
BA_ "FlexKomComment" SG_ 996 NetCfg_CBC_PT "Network ECU config data for Powertrain";
BA_ "GenSigTimeout_ORC" SG_ 996 NetCfg_EPS 7000;
BA_ "GenSigTimeout_IC" SG_ 996 NetCfg_EPS 21000;
BA_ "GenSigSNA" SG_ 996 NetCfg_EPS "0h";
BA_ "GenSigSendType" SG_ 996 NetCfg_EPS 5;
BA_ "GenSigCycleTime" SG_ 996 NetCfg_EPS 2000;
BA_ "FlexKomSigStartValue" SG_ 996 NetCfg_EPS "0300000000000000h";
BA_ "FlexKomSigStartPos" SG_ 996 NetCfg_EPS 7;
BA_ "FlexKomSigName" SG_ 996 NetCfg_EPS "NET_CFG_DATA_PT";
BA_ "FlexKomSigLaenge" SG_ 996 NetCfg_EPS 64;
BA_ "FlexKomSID" SG_ 996 NetCfg_EPS 39;
BA_ "FlexKomIsMotorola" SG_ 996 NetCfg_EPS 1;
BA_ "FlexKomComment" SG_ 996 NetCfg_EPS "Network ECU config data for Powertrain";
BA_ "GenSigTimeout_ORC" SG_ 996 NET_CFG_STAT_PT 7000;
BA_ "GenSigTimeout_OCM" SG_ 996 NET_CFG_STAT_PT 21000;
BA_ "GenSigTimeout_IC" SG_ 996 NET_CFG_STAT_PT 21000;
BA_ "GenSigTimeout_ESM" SG_ 996 NET_CFG_STAT_PT 21000;
BA_ "GenSigTimeout_EHPS" SG_ 996 NET_CFG_STAT_PT 21000;
BA_ "GenSigTimeout_DTCM" SG_ 996 NET_CFG_STAT_PT 21000;
BA_ "GenSigTimeout_DPDM" SG_ 996 NET_CFG_STAT_PT 21000;
BA_ "GenSigStartValue" SG_ 996 NET_CFG_STAT_PT 3;
BA_ "GenSigSNA" SG_ 996 NET_CFG_STAT_PT "3h";
BA_ "GenSigSendType" SG_ 996 NET_CFG_STAT_PT 5;
BA_ "GenSigCycleTime" SG_ 996 NET_CFG_STAT_PT 2000;
BA_ "FlexKomSigStartValue" SG_ 996 NET_CFG_STAT_PT "0300000000000000h";
BA_ "FlexKomSigStartPos" SG_ 996 NET_CFG_STAT_PT 7;
BA_ "FlexKomSigName" SG_ 996 NET_CFG_STAT_PT "NET_CFG_DATA_PT";
BA_ "FlexKomSigLaenge" SG_ 996 NET_CFG_STAT_PT 64;
BA_ "FlexKomSID" SG_ 996 NET_CFG_STAT_PT 39;
BA_ "FlexKomIsMotorola" SG_ 996 NET_CFG_STAT_PT 1;
BA_ "FlexKomComment" SG_ 996 NET_CFG_STAT_PT "Network ECU config data for Powertrain";
BA_ "GenSigTimeout_ORC" SG_ 1000 VC_XWD 1750;
BA_ "GenSigTimeout_IC" SG_ 1000 VC_XWD 5250;
BA_ "GenSigTimeout_ESM" SG_ 1000 VC_XWD 5250;
BA_ "GenSigSNA" SG_ 516 MKKey_4 "0h";
BA_ "GenSigSendType" SG_ 516 MKKey_4 1;
BA_ "FlexKomSigStartValue" SG_ 516 MKKey_4 "00000000000000h";
BA_ "FlexKomSigStartPos" SG_ 516 MKKey_4 7;
BA_ "FlexKomSigName" SG_ 516 MKKey_4 "IMMO_CODE_RESPONSE";
BA_ "FlexKomSigLaenge" SG_ 516 MKKey_4 56;
BA_ "FlexKomSID" SG_ 516 MKKey_4 2110;
BA_ "FlexKomIsMotorola" SG_ 516 MKKey_4 1;
BA_ "FlexKomComment" SG_ 516 MKKey_4 "Immobilizer code response packet";
BA_ "GenSigSNA" SG_ 516 ControlEncodingRsp "0h";
BA_ "GenSigSendType" SG_ 516 ControlEncodingRsp 1;
BA_ "FlexKomSigStartValue" SG_ 516 ControlEncodingRsp "00000000000000h";
BA_ "FlexKomSigStartPos" SG_ 516 ControlEncodingRsp 7;
BA_ "FlexKomSigName" SG_ 516 ControlEncodingRsp "IMMO_CODE_RESPONSE";
BA_ "FlexKomSigLaenge" SG_ 516 ControlEncodingRsp 56;
BA_ "FlexKomSID" SG_ 516 ControlEncodingRsp 2110;
BA_ "FlexKomIsMotorola" SG_ 516 ControlEncodingRsp 1;
BA_ "FlexKomComment" SG_ 516 ControlEncodingRsp "Immobilizer code response packet";
BA_ "GenSigSNA" SG_ 517 rnd_2 "0h";
BA_ "GenSigSendType" SG_ 517 rnd_2 1;
BA_ "FlexKomSigStartValue" SG_ 517 rnd_2 "00000000000000h";
BA_ "FlexKomSigStartPos" SG_ 517 rnd_2 7;
BA_ "FlexKomSigName" SG_ 517 rnd_2 "IMMO_CODE_REQUEST";
BA_ "FlexKomSigLaenge" SG_ 517 rnd_2 56;
BA_ "FlexKomSID" SG_ 517 rnd_2 2111;
BA_ "FlexKomIsMotorola" SG_ 517 rnd_2 1;
BA_ "FlexKomComment" SG_ 517 rnd_2 "Immobilizer code request packet";
BA_ "GenSigStartValue" SG_ 910 IBS3_SOF_V_Accuracy 1;
BA_ "GenSigSNA" SG_ 910 IBS3_SOF_V_Accuracy "1h";
BA_ "GenSigCycleTime" SG_ 910 IBS3_SOF_V_Accuracy 2000;
BA_ "FlexKomSigStartValue" SG_ 910 IBS3_SOF_V_Accuracy "00FFFF7F7F80h";
BA_ "FlexKomSigStartPos" SG_ 910 IBS3_SOF_V_Accuracy 23;
BA_ "FlexKomSigName" SG_ 910 IBS3_SOF_V_Accuracy "GW_LIN_I_C6_Pkt2";
BA_ "FlexKomSigLaenge" SG_ 910 IBS3_SOF_V_Accuracy 48;
BA_ "FlexKomSID" SG_ 910 IBS3_SOF_V_Accuracy 2657;
BA_ "FlexKomIsMotorola" SG_ 910 IBS3_SOF_V_Accuracy 1;
BA_ "FlexKomComment" SG_ 910 IBS3_SOF_V_Accuracy "Cyclic only";
BA_ "RID" SG_ 910 IBS3_SOC_Accuracy "5104";
BA_ "GenSigSNA" SG_ 910 IBS3_SOC_Accuracy "0h";
BA_ "GenSigCycleTime" SG_ 910 IBS3_SOC_Accuracy 2000;
BA_ "FlexKomSigStartValue" SG_ 910 IBS3_SOC_Accuracy "00FFFF7F7F80h";
BA_ "FlexKomSigStartPos" SG_ 910 IBS3_SOC_Accuracy 23;
BA_ "FlexKomSigName" SG_ 910 IBS3_SOC_Accuracy "GW_LIN_I_C6_Pkt2";
BA_ "FlexKomSigLaenge" SG_ 910 IBS3_SOC_Accuracy 48;
BA_ "FlexKomSID" SG_ 910 IBS3_SOC_Accuracy 2657;
BA_ "FlexKomIsMotorola" SG_ 910 IBS3_SOC_Accuracy 1;
BA_ "FlexKomComment" SG_ 910 IBS3_SOC_Accuracy "Cyclic only";
BA_ "RID" SG_ 910 IBS3_TempFailStatus "5082";
BA_ "GenSigSNA" SG_ 910 IBS3_TempFailStatus "0h";
BA_ "GenSigCycleTime" SG_ 910 IBS3_TempFailStatus 2000;
BA_ "FlexKomSigStartValue" SG_ 910 IBS3_TempFailStatus "00FFFF7F7F80h";
BA_ "FlexKomSigStartPos" SG_ 910 IBS3_TempFailStatus 23;
BA_ "FlexKomSigName" SG_ 910 IBS3_TempFailStatus "GW_LIN_I_C6_Pkt2";
BA_ "FlexKomSigLaenge" SG_ 910 IBS3_TempFailStatus 48;
BA_ "FlexKomSID" SG_ 910 IBS3_TempFailStatus 2657;
BA_ "FlexKomIsMotorola" SG_ 910 IBS3_TempFailStatus 1;
BA_ "FlexKomComment" SG_ 910 IBS3_TempFailStatus "Cyclic only";
BA_ "RID" SG_ 910 IBS3_SOH_Q "5148";
BA_ "GenSigStartValue" SG_ 910 IBS3_SOH_Q 127;
BA_ "GenSigSNA" SG_ 910 IBS3_SOH_Q "7Fh";
BA_ "GenSigCycleTime" SG_ 910 IBS3_SOH_Q 2000;
BA_ "FlexKomSigStartValue" SG_ 910 IBS3_SOH_Q "00FFFF7F7F80h";
BA_ "FlexKomSigStartPos" SG_ 910 IBS3_SOH_Q 23;
BA_ "FlexKomSigName" SG_ 910 IBS3_SOH_Q "GW_LIN_I_C6_Pkt2";
BA_ "FlexKomSigLaenge" SG_ 910 IBS3_SOH_Q 48;
BA_ "FlexKomSID" SG_ 910 IBS3_SOH_Q 2657;
BA_ "FlexKomIsMotorola" SG_ 910 IBS3_SOH_Q 1;
BA_ "FlexKomComment" SG_ 910 IBS3_SOH_Q "Cyclic only";
BA_ "GenSigTimeout_EHPS" SG_ 35 LRW 105;
BA_ "GenSigTimeout_DTCM" SG_ 35 LRW 105;
BA_ "GenSigTimeout_CBC" SG_ 35 LRW 105;
BA_ "GenSigStartValue" SG_ 35 LRW 16383;
BA_ "GenSigSNA" SG_ 35 LRW "3FFFh";
BA_ "GenSigCycleTime" SG_ 35 LRW 10;
BA_ "FlexKomSigStartValue" SG_ 35 LRW "3FFF3FFF030000FFh";
BA_ "FlexKomSigStartPos" SG_ 35 LRW 7;
BA_ "FlexKomSigName" SG_ 35 LRW "LRW_ST";
BA_ "FlexKomSigLaenge" SG_ 35 LRW 64;
BA_ "FlexKomSID" SG_ 35 LRW 418;
BA_ "FlexKomIsMotorola" SG_ 35 LRW 1;
BA_ "FlexKomComment" SG_ 35 LRW "Steering wheel angle state";
BA_ "FlexKomSigName" SG_ 147 PRNDL_Blink "TRNS_STAT_PKT";
BA_ "FlexKomSigLaenge" SG_ 147 PRNDL_Blink 64;
BA_ "FlexKomSID" SG_ 147 PRNDL_Blink 1366;
BA_ "FlexKomIsMotorola" SG_ 147 PRNDL_Blink 1;
BA_ "FlexKomComment" SG_ 147 PRNDL_Blink "TRNS_STAT message packet";
BA_ "RID" SG_ 147 PaddlesModeSts "2048";
BA_ "GenSigTimeout_IC" SG_ 147 PaddlesModeSts 210;
BA_ "GenSigTimeout_ESM" SG_ 147 PaddlesModeSts 410;
BA_ "GenSigTimeout_CBC" SG_ 147 PaddlesModeSts 210;
BA_ "GenSigSNA" SG_ 147 PaddlesModeSts "3h";
BA_ "GenSigCycleTime" SG_ 147 PaddlesModeSts 20;
BA_ "FlexKomSigStartValue" SG_ 147 PaddlesModeSts "1CFFFF00000000FFh";
BA_ "FlexKomSigStartPos" SG_ 147 PaddlesModeSts 7;
BA_ "FlexKomSigName" SG_ 147 PaddlesModeSts "TRNS_STAT_PKT";
BA_ "FlexKomSigLaenge" SG_ 147 PaddlesModeSts 64;
BA_ "FlexKomSID" SG_ 147 PaddlesModeSts 1366;
BA_ "FlexKomIsMotorola" SG_ 147 PaddlesModeSts 1;
BA_ "FlexKomComment" SG_ 147 PaddlesModeSts "TRNS_STAT message packet";
BA_ "GenSigSNA" SG_ 133 K_STO_B "0h";
BA_ "GenSigCycleTime" SG_ 133 K_STO_B 20;
BA_ "FlexKomSigStartValue" SG_ 133 K_STO_B "000000h";
BA_ "FlexKomSigStartPos" SG_ 133 K_STO_B 7;
BA_ "FlexKomSigName" SG_ 133 K_STO_B "K_B";
BA_ "FlexKomSigLaenge" SG_ 133 K_STO_B 24;
BA_ "FlexKomSID" SG_ 133 K_STO_B 1129;
BA_ "FlexKomIsMotorola" SG_ 133 K_STO_B 1;
BA_ "FlexKomComment" SG_ 133 K_STO_B "Torque converter lock-up status";
BA_ "RID" SG_ 133 Gr_Target "1814";
BA_ "GenSigTimeout_DTCM" SG_ 133 Gr_Target 210;
BA_ "GenSigTimeout_CBC" SG_ 133 Gr_Target 210;
BA_ "GenSigStartValue" SG_ 133 Gr_Target 15;
BA_ "GenSigSNA" SG_ 133 Gr_Target "Fh";
BA_ "GenSigCycleTime" SG_ 133 Gr_Target 20;
BA_ "FlexKomSigStartValue" SG_ 133 Gr_Target "FF00h";
BA_ "FlexKomSigStartPos" SG_ 133 Gr_Target 15;
BA_ "FlexKomSigName" SG_ 133 Gr_Target "Gear_Pkt";
BA_ "FlexKomSigLaenge" SG_ 133 Gr_Target 16;
BA_ "FlexKomSID" SG_ 133 Gr_Target 1128;
BA_ "FlexKomIsMotorola" SG_ 133 Gr_Target 1;
BA_ "FlexKomComment" SG_ 133 Gr_Target "Current Gear/Target Gear";
BA_ "GenSigStartValue" SG_ 133 N_Turb 65535;
BA_ "GenSigSNA" SG_ 133 N_Turb "FFFFh";
BA_ "GenSigCycleTime" SG_ 133 N_Turb 20;
BA_ "FlexKomSigStartValue" SG_ 133 N_Turb "FFFFh";
BA_ "FlexKomSigStartPos" SG_ 133 N_Turb 47;
BA_ "FlexKomSigName" SG_ 133 N_Turb "N_Turb";
BA_ "FlexKomSigLaenge" SG_ 133 N_Turb 16;
BA_ "FlexKomSID" SG_ 133 N_Turb 1133;
BA_ "FlexKomIsMotorola" SG_ 133 N_Turb 1;
BA_ "FlexKomComment" SG_ 133 N_Turb "Unfiltered turbine speed (n_t_v)";
BA_ "RID" SG_ 464 DRV_SEATBELT "1107";
BA_ "GenSigTimeout_TBM" SG_ 464 DRV_SEATBELT 10500;
BA_ "GenSigTimeout_PTS" SG_ 464 DRV_SEATBELT 10500;
BA_ "GenSigTimeout_IC" SG_ 464 DRV_SEATBELT 10500;
BA_ "GenSigTimeout_ETM" SG_ 464 DRV_SEATBELT 10500;
BA_ "GenSigTimeout_CBC" SG_ 464 DRV_SEATBELT 10500;
BA_ "GenSigStartValue" SG_ 464 DRV_SEATBELT 3;
BA_ "GenSigSNA" SG_ 464 DRV_SEATBELT "3h";
BA_ "GenSigSendType" SG_ 464 DRV_SEATBELT 5;
BA_ "GenSigCycleTime" SG_ 464 DRV_SEATBELT 1000;
BA_ "FlexKomSigStartValue" SG_ 464 DRV_SEATBELT "03h";
BA_ "FlexKomSigStartPos" SG_ 464 DRV_SEATBELT 17;
BA_ "FlexKomSigName" SG_ 464 DRV_SEATBELT "DRV_SEATBELT";
BA_ "FlexKomSigLaenge" SG_ 464 DRV_SEATBELT 2;
BA_ "FlexKomSID" SG_ 464 DRV_SEATBELT 330;
BA_ "FlexKomIsMotorola" SG_ 464 DRV_SEATBELT 1;
BA_ "FlexKomComment" SG_ 464 DRV_SEATBELT "Drivers seat belt status";
BA_ "GenSigSNA" SG_ 333 VVT_ExhCam1Pos "0h";
BA_ "GenSigCycleTime" SG_ 333 VVT_ExhCam1Pos 100;
BA_ "FlexKomSigStartValue" SG_ 333 VVT_ExhCam1Pos "FFFFFFFF0000FF00h";
BA_ "FlexKomSigStartPos" SG_ 333 VVT_ExhCam1Pos 7;
BA_ "FlexKomSigName" SG_ 333 VVT_ExhCam1Pos "EDR2_Pkt";
BA_ "FlexKomSigLaenge" SG_ 333 VVT_ExhCam1Pos 64;
BA_ "FlexKomSID" SG_ 333 VVT_ExhCam1Pos 1093;
BA_ "FlexKomIsMotorola" SG_ 333 VVT_ExhCam1Pos 1;
BA_ "FlexKomComment" SG_ 333 VVT_ExhCam1Pos "EDR2 information packet only";
BA_ "GenSigTimeout_ORC" SG_ 333 VVT_IntCam2Pos 350;
BA_ "GenSigStartValue" SG_ 333 VVT_IntCam2Pos 255;
BA_ "GenSigSNA" SG_ 333 VVT_IntCam2Pos "0h";
BA_ "GenSigCycleTime" SG_ 333 VVT_IntCam2Pos 100;
BA_ "FlexKomSigStartValue" SG_ 333 VVT_IntCam2Pos "FFFFFFFF0000FF00h";
BA_ "FlexKomSigStartPos" SG_ 333 VVT_IntCam2Pos 7;
BA_ "FlexKomSigName" SG_ 333 VVT_IntCam2Pos "EDR2_Pkt";
BA_ "FlexKomSigLaenge" SG_ 333 VVT_IntCam2Pos 64;
BA_ "FlexKomSID" SG_ 333 VVT_IntCam2Pos 1093;
BA_ "FlexKomIsMotorola" SG_ 333 VVT_IntCam2Pos 1;
BA_ "FlexKomComment" SG_ 333 VVT_IntCam2Pos "EDR2 information packet only";
BA_ "GenSigTimeout_IC" SG_ 993 TRANS_TYPE 1050;
BA_ "GenSigSNA" SG_ 993 TRANS_TYPE "0h";
BA_ "GenSigCycleTime" SG_ 993 TRANS_TYPE 100;
BA_ "FlexKomSigStartValue" SG_ 993 TRANS_TYPE "FFEFE7E7h";
BA_ "FlexKomSigStartPos" SG_ 993 TRANS_TYPE 7;
BA_ "FlexKomSigName" SG_ 993 TRANS_TYPE "ENG_CFG";
BA_ "FlexKomSigLaenge" SG_ 993 TRANS_TYPE 32;
BA_ "FlexKomSID" SG_ 993 TRANS_TYPE 617;
BA_ "FlexKomIsMotorola" SG_ 993 TRANS_TYPE 1;
BA_ "FlexKomComment" SG_ 993 TRANS_TYPE "Engine Configuration Information";
BA_ "RID" SG_ 788 CFG_STAT_RQ "1228";
BA_ "GenSigSNA" SG_ 788 CFG_STAT_RQ "0h";
BA_ "GenSigSendType" SG_ 788 CFG_STAT_RQ 2;
BA_ "GenSigCycleTimeActive" SG_ 788 CFG_STAT_RQ 50;
BA_ "FlexKomSigStartValue" SG_ 788 CFG_STAT_RQ "000000h";
BA_ "FlexKomSigStartPos" SG_ 788 CFG_STAT_RQ 7;
BA_ "FlexKomSigName" SG_ 788 CFG_STAT_RQ "CFG_RQ";
BA_ "FlexKomSigLaenge" SG_ 788 CFG_STAT_RQ 24;
BA_ "FlexKomSID" SG_ 788 CFG_STAT_RQ 442;
BA_ "FlexKomIsMotorola" SG_ 788 CFG_STAT_RQ 1;
BA_ "FlexKomComment" SG_ 788 CFG_STAT_RQ "Configurable display request";
BA_ "GenSigTimeout_ORC" SG_ 333 VVT_IntCam1Pos 350;
BA_ "GenSigStartValue" SG_ 333 VVT_IntCam1Pos 255;
BA_ "GenSigSNA" SG_ 333 VVT_IntCam1Pos "0h";
BA_ "GenSigCycleTime" SG_ 333 VVT_IntCam1Pos 100;
BA_ "FlexKomSigName" SG_ 788 CFG_FEATURE "CFG_RQ";
BA_ "FlexKomSigLaenge" SG_ 788 CFG_FEATURE 24;
BA_ "FlexKomSID" SG_ 788 CFG_FEATURE 442;
BA_ "FlexKomIsMotorola" SG_ 788 CFG_FEATURE 1;
BA_ "FlexKomComment" SG_ 788 CFG_FEATURE "Configurable display request";
BA_ "GenSigSNA" SG_ 177 ACC_DistSwDec "0h";
BA_ "GenSigSendType" SG_ 177 ACC_DistSwDec 1;
BA_ "FlexKomSigStartValue" SG_ 177 ACC_DistSwDec "0000FFh";
BA_ "FlexKomSigStartPos" SG_ 177 ACC_DistSwDec 7;
BA_ "FlexKomSigName" SG_ 177 ACC_DistSwDec "CrsCtrlLvrSts";
BA_ "FlexKomSigLaenge" SG_ 177 ACC_DistSwDec 24;
BA_ "FlexKomSID" SG_ 177 ACC_DistSwDec 1848;
BA_ "FlexKomIsMotorola" SG_ 177 ACC_DistSwDec 1;
BA_ "FlexKomComment" SG_ 177 ACC_DistSwDec "Cruise Control Lever Status";
BA_ "GenSigSNA" SG_ 177 ResumeSwitch "0h";
BA_ "GenSigSendType" SG_ 177 ResumeSwitch 1;
BA_ "FlexKomSigStartValue" SG_ 177 ResumeSwitch "0000FFh";
BA_ "FlexKomSigStartPos" SG_ 177 ResumeSwitch 7;
BA_ "FlexKomSigName" SG_ 177 ResumeSwitch "CrsCtrlLvrSts";
BA_ "FlexKomSigLaenge" SG_ 177 ResumeSwitch 24;
BA_ "FlexKomSID" SG_ 177 ResumeSwitch 1848;
BA_ "FlexKomIsMotorola" SG_ 177 ResumeSwitch 1;
BA_ "FlexKomComment" SG_ 177 ResumeSwitch "Cruise Control Lever Status";
BA_ "GenSigSNA" SG_ 177 ACC_On "0h";
BA_ "GenSigSendType" SG_ 177 ACC_On 1;
BA_ "FlexKomSigStartValue" SG_ 177 ACC_On "0000FFh";
BA_ "FlexKomSigStartPos" SG_ 177 ACC_On 7;
BA_ "FlexKomSigName" SG_ 177 ACC_On "CrsCtrlLvrSts";
BA_ "FlexKomSigLaenge" SG_ 177 ACC_On 24;
BA_ "FlexKomSID" SG_ 177 ACC_On 1848;
BA_ "FlexKomIsMotorola" SG_ 177 ACC_On 1;
BA_ "FlexKomComment" SG_ 177 ACC_On "Cruise Control Lever Status";
BA_ "GenSigSNA" SG_ 177 MC_CSWC_1 "0h";
BA_ "GenSigSendType" SG_ 177 MC_CSWC_1 1;
BA_ "FlexKomSigStartValue" SG_ 177 MC_CSWC_1 "0000FFh";
BA_ "FlexKomSigStartPos" SG_ 177 MC_CSWC_1 7;
BA_ "FlexKomSigName" SG_ 177 MC_CSWC_1 "CrsCtrlLvrSts";
BA_ "FlexKomSigLaenge" SG_ 177 MC_CSWC_1 24;
BA_ "FlexKomSID" SG_ 177 MC_CSWC_1 1848;
BA_ "FlexKomIsMotorola" SG_ 177 MC_CSWC_1 1;
BA_ "FlexKomComment" SG_ 177 MC_CSWC_1 "Cruise Control Lever Status";
BA_ "GenSigTimeout_RF_HUB" SG_ 173 DrvRqShftROT 210;
BA_ "GenSigSNA" SG_ 173 DrvRqShftROT "7h";
BA_ "GenSigCycleTime" SG_ 173 DrvRqShftROT 20;
BA_ "FlexKomSigStartValue" SG_ 173 DrvRqShftROT "00000000FFh";
BA_ "FlexKomSigStartPos" SG_ 173 DrvRqShftROT 7;
BA_ "FlexKomSigName" SG_ 173 DrvRqShftROT "SBW_ROT1_PKT";
BA_ "FlexKomSigLaenge" SG_ 173 DrvRqShftROT 40;
BA_ "FlexKomSID" SG_ 173 DrvRqShftROT 1661;
BA_ "FlexKomIsMotorola" SG_ 173 DrvRqShftROT 1;
BA_ "FlexKomComment" SG_ 173 DrvRqShftROT "Shift by wire - rotary 1 packet";
BA_ "GenSigSNA" SG_ 517 rnd_3 "0h";
BA_ "GenSigSendType" SG_ 517 rnd_3 1;
BA_ "FlexKomSigStartValue" SG_ 517 rnd_3 "00000000000000h";
BA_ "FlexKomSigStartPos" SG_ 517 rnd_3 7;
BA_ "FlexKomSigName" SG_ 517 rnd_3 "IMMO_CODE_REQUEST";
BA_ "FlexKomSigLaenge" SG_ 517 rnd_3 56;
BA_ "FlexKomSID" SG_ 517 rnd_3 2111;
BA_ "FlexKomIsMotorola" SG_ 517 rnd_3 1;
BA_ "FlexKomComment" SG_ 517 rnd_3 "Immobilizer code request packet";
BA_ "GenSigSNA" SG_ 517 f1_2 "0h";
BA_ "GenSigSendType" SG_ 517 f1_2 1;
BA_ "FlexKomSigStartValue" SG_ 517 f1_2 "00000000000000h";
BA_ "FlexKomSigStartPos" SG_ 517 f1_2 7;
BA_ "FlexKomSigName" SG_ 517 f1_2 "IMMO_CODE_REQUEST";
BA_ "FlexKomSigLaenge" SG_ 517 f1_2 56;
BA_ "FlexKomSID" SG_ 517 f1_2 2111;
BA_ "FlexKomIsMotorola" SG_ 517 f1_2 1;
BA_ "FlexKomComment" SG_ 517 f1_2 "Immobilizer code request packet";
BA_ "GenSigTimeout_SCCM" SG_ 1000 VC_VehCfg1_Stat 5250;
BA_ "GenSigTimeout_ORC" SG_ 1000 VC_VehCfg1_Stat 1750;
BA_ "RID" SG_ 910 IBS3_SOF_V_Accuracy "5129";
BA_ "GenSigTimeout_SCCM" SG_ 1000 VC_VEH_LINE 5250;
BA_ "GenSigTimeout_ORC" SG_ 1000 VC_VEH_LINE 1750;
BA_ "GenSigTimeout_OCM" SG_ 1000 VC_VEH_LINE 2750;
BA_ "GenSigTimeout_IC" SG_ 1000 VC_VEH_LINE 5250;
BA_ "GenSigTimeout_ESM" SG_ 1000 VC_VEH_LINE 5250;
BA_ "GenSigTimeout_EHPS" SG_ 1000 VC_VEH_LINE 5250;
BA_ "GenSigTimeout_DTCM" SG_ 1000 VC_VEH_LINE 5250;
BA_ "GenSigTimeout_DPDM" SG_ 1000 VC_VEH_LINE 2750;
BA_ "GenSigStartValue" SG_ 1000 VC_VEH_LINE 255;
BA_ "GenSigSNA" SG_ 1000 VC_VEH_LINE "FFh";
BA_ "GenSigSendType" SG_ 1000 VC_VEH_LINE 5;
BA_ "GenSigCycleTime" SG_ 1000 VC_VEH_LINE 500;
BA_ "FlexKomSigStartValue" SG_ 1000 VC_VEH_LINE "FFFF7FF0FF0FFF00h";
BA_ "FlexKomSigStartPos" SG_ 1000 VC_VEH_LINE 7;
BA_ "FlexKomSigName" SG_ 1000 VC_VEH_LINE "VehCfg1_Pkt";
BA_ "FlexKomSigLaenge" SG_ 1000 VC_VEH_LINE 64;
BA_ "FlexKomSID" SG_ 1000 VC_VEH_LINE 886;
BA_ "FlexKomIsMotorola" SG_ 1000 VC_VEH_LINE 1;
BA_ "FlexKomComment" SG_ 1000 VC_VEH_LINE "Vehicle Configuration 1 Packet";
BA_ "GenSigTimeout_IC" SG_ 976 PF_WARN_MSG 5250;
BA_ "GenSigSNA" SG_ 976 PF_WARN_MSG "0h";
BA_ "GenSigCycleTime" SG_ 976 PF_WARN_MSG 500;
BA_ "FlexKomSigStartValue" SG_ 976 PF_WARN_MSG "0000000000000000h";
BA_ "FlexKomSigStartPos" SG_ 976 PF_WARN_MSG 7;
BA_ "FlexKomSigName" SG_ 976 PF_WARN_MSG "ECM_A4_Pkt";
BA_ "FlexKomSigLaenge" SG_ 976 PF_WARN_MSG 64;
BA_ "FlexKomSID" SG_ 976 PF_WARN_MSG 2627;
BA_ "FlexKomIsMotorola" SG_ 976 PF_WARN_MSG 1;
BA_ "FlexKomComment" SG_ 976 PF_WARN_MSG "ECM_A4 Packet";
BA_ "RID" SG_ 147 PRND_STAT "1003 1270 1290 1708 6372 6373 6374";
BA_ "GenSigTimeout_ORC" SG_ 1002 VC_VehCfg3_Stat 7000;
BA_ "GenSigTimeout_IC" SG_ 1002 VC_VehCfg3_Stat 21000;
BA_ "GenSigTimeout_EHPS" SG_ 1002 VC_VehCfg3_Stat 21000;
BA_ "GenSigStartValue" SG_ 1002 VC_VehCfg3_Stat 3;
BA_ "GenSigSNA" SG_ 1002 VC_VehCfg3_Stat "3h";
BA_ "GenSigSendType" SG_ 1002 VC_VehCfg3_Stat 5;
BA_ "GenSigCycleTime" SG_ 1002 VC_VehCfg3_Stat 2000;
BA_ "FlexKomSigStartValue" SG_ 1002 VC_VehCfg3_Stat "0370FF037FFF0000h";
BA_ "FlexKomSigStartPos" SG_ 1002 VC_VehCfg3_Stat 7;
BA_ "FlexKomSigName" SG_ 1002 VC_VehCfg3_Stat "VehCfg3_Pkt";
BA_ "FlexKomSigLaenge" SG_ 1002 VC_VehCfg3_Stat 64;
BA_ "FlexKomSID" SG_ 1002 VC_VehCfg3_Stat 888;
BA_ "FlexKomIsMotorola" SG_ 1002 VC_VehCfg3_Stat 1;
BA_ "FlexKomComment" SG_ 1002 VC_VehCfg3_Stat "Vehicle Configuration 3 Packet";
BA_ "GenSigTimeout_ORC" SG_ 996 NetCfg_EPB 7000;
BA_ "GenSigTimeout_IC" SG_ 996 NetCfg_EPB 21000;
BA_ "GenSigStartValue" SG_ 177 CRC_CSWC_1 255;
BA_ "GenSigSNA" SG_ 177 CRC_CSWC_1 "FFh";
BA_ "GenSigSendType" SG_ 177 CRC_CSWC_1 1;
BA_ "FlexKomSigStartValue" SG_ 177 CRC_CSWC_1 "0000FFh";
BA_ "FlexKomSigStartPos" SG_ 177 CRC_CSWC_1 7;
BA_ "FlexKomSigName" SG_ 177 CRC_CSWC_1 "CrsCtrlLvrSts";
BA_ "FlexKomSigLaenge" SG_ 177 CRC_CSWC_1 24;
BA_ "FlexKomSID" SG_ 177 CRC_CSWC_1 1848;
BA_ "FlexKomIsMotorola" SG_ 177 CRC_CSWC_1 1;
BA_ "FlexKomComment" SG_ 177 CRC_CSWC_1 "Cruise Control Lever Status";
BA_ "GenSigSNA" SG_ 173 Manual_Gate_Request "7h";
BA_ "GenSigCycleTime" SG_ 173 Manual_Gate_Request 20;
BA_ "FlexKomSigStartValue" SG_ 173 Manual_Gate_Request "00000000FFh";
BA_ "FlexKomSigStartPos" SG_ 173 Manual_Gate_Request 7;
BA_ "FlexKomSigName" SG_ 173 Manual_Gate_Request "SBW_ROT1_PKT";
BA_ "FlexKomSigLaenge" SG_ 173 Manual_Gate_Request 40;
BA_ "FlexKomSID" SG_ 173 Manual_Gate_Request 1661;
BA_ "FlexKomIsMotorola" SG_ 173 Manual_Gate_Request 1;
BA_ "FlexKomComment" SG_ 173 Manual_Gate_Request "Shift by wire - rotary 1 packet";
BA_ "GenSigTimeout_SCCM" SG_ 1000 VC_MODEL_YEAR 5250;
BA_ "GenSigTimeout_ORC" SG_ 1000 VC_MODEL_YEAR 1750;
BA_ "GenSigTimeout_IC" SG_ 1000 VC_MODEL_YEAR 5250;
BA_ "GenSigTimeout_ESM" SG_ 1000 VC_MODEL_YEAR 5250;
BA_ "GenSigTimeout_EHPS" SG_ 1000 VC_MODEL_YEAR 5250;
BA_ "GenSigTimeout_DTCM" SG_ 1000 VC_MODEL_YEAR 5250;
BA_ "GenSigStartValue" SG_ 1000 VC_MODEL_YEAR 63;
BA_ "GenSigSNA" SG_ 1000 VC_MODEL_YEAR "3Fh";
BA_ "GenSigSendType" SG_ 1000 VC_MODEL_YEAR 5;
BA_ "GenSigCycleTime" SG_ 1000 VC_MODEL_YEAR 500;
BA_ "FlexKomSigStartValue" SG_ 1000 VC_MODEL_YEAR "FFFF7FF0FF0FFF00h";
BA_ "FlexKomSigStartPos" SG_ 1000 VC_MODEL_YEAR 7;
BA_ "FlexKomSigName" SG_ 1000 VC_MODEL_YEAR "VehCfg1_Pkt";
BA_ "FlexKomSigLaenge" SG_ 1000 VC_MODEL_YEAR 64;
BA_ "FlexKomSID" SG_ 1000 VC_MODEL_YEAR 886;
BA_ "FlexKomIsMotorola" SG_ 1000 VC_MODEL_YEAR 1;
BA_ "FlexKomComment" SG_ 1000 VC_MODEL_YEAR "Vehicle Configuration 1 Packet";
BA_ "GenSigTimeout_RF_HUB" SG_ 147 PRND_STAT 210;
BA_ "GenSigTimeout_PTS" SG_ 147 PRND_STAT 210;
BA_ "GenSigTimeout_ORC" SG_ 147 PRND_STAT 70;
BA_ "GenSigTimeout_IC" SG_ 147 PRND_STAT 210;
BA_ "GenSigTimeout_ESM" SG_ 147 PRND_STAT 410;
BA_ "GenSigTimeout_DTCM" SG_ 147 PRND_STAT 210;
BA_ "GenSigTimeout_CBC" SG_ 147 PRND_STAT 510;
BA_ "GenSigStartValue" SG_ 147 PRND_STAT 7;
BA_ "GenSigSNA" SG_ 147 PRND_STAT "7h";
BA_ "GenSigCycleTime" SG_ 147 PRND_STAT 20;
BA_ "FlexKomSigStartValue" SG_ 147 PRND_STAT "1CFFFF00000000FFh";
BA_ "FlexKomSigStartPos" SG_ 147 PRND_STAT 7;
BA_ "FlexKomSigName" SG_ 147 PRND_STAT "TRNS_STAT_PKT";
BA_ "FlexKomSigLaenge" SG_ 147 PRND_STAT 64;
BA_ "FlexKomSID" SG_ 147 PRND_STAT 1366;
BA_ "FlexKomIsMotorola" SG_ 147 PRND_STAT 1;
BA_ "FlexKomComment" SG_ 147 PRND_STAT "TRNS_STAT message packet";
BA_ "GenSigTimeout_ORC" SG_ 993 SpStPrsnt 350;
BA_ "GenSigTimeout_IC" SG_ 993 SpStPrsnt 1050;
BA_ "GenSigSNA" SG_ 993 SpStPrsnt "0h";
BA_ "GenSigCycleTime" SG_ 993 SpStPrsnt 100;
BA_ "FlexKomSigStartValue" SG_ 993 SpStPrsnt "FFEFE7E7h";
BA_ "FlexKomSigStartPos" SG_ 993 SpStPrsnt 7;
BA_ "FlexKomSigName" SG_ 993 SpStPrsnt "ENG_CFG";
BA_ "FlexKomSigLaenge" SG_ 993 SpStPrsnt 32;
BA_ "FlexKomSID" SG_ 993 SpStPrsnt 617;
BA_ "FlexKomIsMotorola" SG_ 993 SpStPrsnt 1;
BA_ "FlexKomComment" SG_ 993 SpStPrsnt "Engine Configuration Information";
BA_ "GenSigTimeout_IC" SG_ 993 ECM_Vehi_Type 1050;
BA_ "GenSigSNA" SG_ 993 ECM_Vehi_Type "3h";
BA_ "GenSigCycleTime" SG_ 993 ECM_Vehi_Type 100;
BA_ "FlexKomSigStartValue" SG_ 993 ECM_Vehi_Type "FFEFE7E7h";
BA_ "FlexKomSigStartPos" SG_ 993 ECM_Vehi_Type 7;
BA_ "FlexKomSigName" SG_ 993 ECM_Vehi_Type "ENG_CFG";
BA_ "FlexKomSigLaenge" SG_ 993 ECM_Vehi_Type 32;
BA_ "FlexKomSID" SG_ 993 ECM_Vehi_Type 617;
BA_ "FlexKomIsMotorola" SG_ 993 ECM_Vehi_Type 1;
BA_ "FlexKomComment" SG_ 993 ECM_Vehi_Type "Engine Configuration Information";
BA_ "GenSigTimeout_IC" SG_ 993 ETC_PRSNT 1050;
BA_ "GenSigSNA" SG_ 993 ETC_PRSNT "0h";
BA_ "GenSigCycleTime" SG_ 993 ETC_PRSNT 100;
BA_ "FlexKomSigStartValue" SG_ 993 ETC_PRSNT "FFEFE7E7h";
BA_ "FlexKomSigStartPos" SG_ 993 ETC_PRSNT 7;
BA_ "FlexKomSigName" SG_ 993 ETC_PRSNT "ENG_CFG";
BA_ "FlexKomSigLaenge" SG_ 993 ETC_PRSNT 32;
BA_ "FlexKomSID" SG_ 993 ETC_PRSNT 617;
BA_ "FlexKomIsMotorola" SG_ 993 ETC_PRSNT 1;
BA_ "FlexKomComment" SG_ 993 ETC_PRSNT "Engine Configuration Information";
BA_ "GenSigSNA" SG_ 993 A580_DATA "0h";
BA_ "GenSigCycleTime" SG_ 993 A580_DATA 100;
BA_ "FlexKomSigStartValue" SG_ 993 A580_DATA "1F0000h";
BA_ "FlexKomSigStartPos" SG_ 993 A580_DATA 39;
BA_ "FlexKomSigName" SG_ 993 A580_DATA "AVC_CFG";
BA_ "FlexKomSigLaenge" SG_ 993 A580_DATA 24;
BA_ "FlexKomSID" SG_ 993 A580_DATA 1090;
BA_ "FlexKomIsMotorola" SG_ 993 A580_DATA 1;
BA_ "FlexKomComment" SG_ 993 A580_DATA "TCM_EGS AVC Configuration";
BA_ "RID" SG_ 464 DrvSbltUnFltr "1973";
BA_ "GenSigStartValue" SG_ 464 DrvSbltUnFltr 7;
BA_ "GenSigSNA" SG_ 464 DrvSbltUnFltr "7h";
BA_ "GenSigSendType" SG_ 464 DrvSbltUnFltr 5;
BA_ "GenSigCycleTime" SG_ 464 DrvSbltUnFltr 1000;
BA_ "FlexKomSigStartValue" SG_ 464 DrvSbltUnFltr "07h";
BA_ "FlexKomSigStartPos" SG_ 464 DrvSbltUnFltr 15;
BA_ "FlexKomSigName" SG_ 464 DrvSbltUnFltr "DrvSbltUnFltr";
BA_ "FlexKomSigLaenge" SG_ 464 DrvSbltUnFltr 3;
BA_ "FlexKomSID" SG_ 464 DrvSbltUnFltr 1814;
BA_ "FlexKomIsMotorola" SG_ 464 DrvSbltUnFltr 1;
BA_ "FlexKomComment" SG_ 464 DrvSbltUnFltr "Drivers seat belt fault status - unfiltered";
BA_ "RID" SG_ 466 IMPACT_X "1273 2130";
BA_ "GenSigTimeout_ORC" SG_ 147 MC_TRNS_STAT 70;
BA_ "GenSigTimeout_ESM" SG_ 996 NetCfg_CBC_PT 21000;
BA_ "GenSigTimeout_EHPS" SG_ 996 NetCfg_CBC_PT 21000;
BA_ "GenSigTimeout_PTS" SG_ 1098 VC_PPPA_Prsnt 21000;
BA_ "GenSigTimeout_IC" SG_ 1098 VC_PPPA_Prsnt 21000;
BA_ "GenSigSNA" SG_ 1098 VC_PPPA_Prsnt "0h";
BA_ "GenSigSendType" SG_ 1098 VC_PPPA_Prsnt 5;
BA_ "GenSigCycleTime" SG_ 1098 VC_PPPA_Prsnt 2000;
BA_ "FlexKomSigStartValue" SG_ 1098 VC_PPPA_Prsnt "C3FFFFFFFFFFFF00h";
BA_ "FlexKomSigStartPos" SG_ 1098 VC_PPPA_Prsnt 7;
BA_ "FlexKomSigName" SG_ 1098 VC_PPPA_Prsnt "VehCfg5_Pkt";
BA_ "FlexKomSigLaenge" SG_ 1098 VC_PPPA_Prsnt 64;
BA_ "FlexKomSID" SG_ 1098 VC_PPPA_Prsnt 1198;
BA_ "FlexKomIsMotorola" SG_ 1098 VC_PPPA_Prsnt 1;
BA_ "FlexKomComment" SG_ 1098 VC_PPPA_Prsnt "Vehicle Configuration 5 Packet";
BA_ "GenSigSNA" SG_ 55 TrqCtrlModeRq "7h";
BA_ "GenSigCycleTime" SG_ 55 TrqCtrlModeRq 10;
BA_ "FlexKomSigStartValue" SG_ 55 TrqCtrlModeRq "1FFF1FFF1FFF00FFh";
BA_ "FlexKomSigStartPos" SG_ 55 TrqCtrlModeRq 7;
BA_ "FlexKomSigName" SG_ 55 TrqCtrlModeRq "TCM_EngTrq2_Pkt";
BA_ "FlexKomSigLaenge" SG_ 55 TrqCtrlModeRq 64;
BA_ "FlexKomSID" SG_ 55 TrqCtrlModeRq 1379;
BA_ "FlexKomIsMotorola" SG_ 55 TrqCtrlModeRq 1;
BA_ "FlexKomComment" SG_ 55 TrqCtrlModeRq "Engine Torque Pkt";
BA_ "GenSigTimeout_SCCM" SG_ 1000 VC_BODY_STYLE 5250;
BA_ "GenSigTimeout_ORC" SG_ 1000 VC_BODY_STYLE 1750;
BA_ "GenSigTimeout_IC" SG_ 1000 VC_BODY_STYLE 5250;
BA_ "GenSigTimeout_ESM" SG_ 1000 VC_BODY_STYLE 5250;
BA_ "GenSigTimeout_EHPS" SG_ 1000 VC_BODY_STYLE 5250;
BA_ "GenSigTimeout_DTCM" SG_ 1000 VC_BODY_STYLE 5250;
BA_ "GenSigStartValue" SG_ 1000 VC_BODY_STYLE 15;
BA_ "GenSigSNA" SG_ 1000 VC_BODY_STYLE "Fh";
BA_ "GenSigSendType" SG_ 1000 VC_BODY_STYLE 5;
BA_ "GenSigCycleTime" SG_ 1000 VC_BODY_STYLE 500;
BA_ "FlexKomSigStartValue" SG_ 1000 VC_BODY_STYLE "FFFF7FF0FF0FFF00h";
BA_ "GenSigStartValue" SG_ 149 Trans_Trq_Ratio 2047;
BA_ "GenSigSNA" SG_ 149 Trans_Trq_Ratio "7FFh";
BA_ "GenSigCycleTime" SG_ 149 Trans_Trq_Ratio 20;
BA_ "FlexKomSigStartValue" SG_ 149 Trans_Trq_Ratio "07FF001FFF00FFh";
BA_ "FlexKomSigStartPos" SG_ 149 Trans_Trq_Ratio 7;
BA_ "FlexKomSigName" SG_ 149 Trans_Trq_Ratio "ENG_TRQ_PKT";
BA_ "FlexKomSigLaenge" SG_ 149 Trans_Trq_Ratio 56;
BA_ "FlexKomSID" SG_ 149 Trans_Trq_Ratio 788;
BA_ "FlexKomIsMotorola" SG_ 149 Trans_Trq_Ratio 1;
BA_ "FlexKomComment" SG_ 149 Trans_Trq_Ratio "Engine torque packet for all transmissions";
BA_ "GenSigTimeout_ORC" SG_ 996 NetCfg_CBC_PT 7000;
BA_ "GenSigTimeout_OCM" SG_ 996 NetCfg_CBC_PT 21000;
BA_ "GenSigTimeout_IC" SG_ 996 NetCfg_CBC_PT 21000;
BA_ "GenSigTimeout_ORC" SG_ 1013 EC_ECUCfg6_Stat 7000;
BA_ "GenSigStartValue" SG_ 1013 EC_ECUCfg6_Stat 3;
BA_ "GenSigSNA" SG_ 1013 EC_ECUCfg6_Stat "3h";
BA_ "GenSigSendType" SG_ 1013 EC_ECUCfg6_Stat 5;
BA_ "GenSigCycleTime" SG_ 1013 EC_ECUCfg6_Stat 2000;
BA_ "FlexKomSigStartValue" SG_ 1013 EC_ECUCfg6_Stat "03h";
BA_ "FlexKomSigStartPos" SG_ 1013 EC_ECUCfg6_Stat 1;
BA_ "FlexKomSigName" SG_ 1013 EC_ECUCfg6_Stat "EC_ECUCfg6_Stat";
BA_ "FlexKomSigLaenge" SG_ 1013 EC_ECUCfg6_Stat 2;
BA_ "FlexKomSID" SG_ 1013 EC_ECUCfg6_Stat 1063;
BA_ "FlexKomIsMotorola" SG_ 1013 EC_ECUCfg6_Stat 1;
BA_ "FlexKomComment" SG_ 1013 EC_ECUCfg6_Stat "ECU Configuration messages status 6";
BA_ "GenSigStartValue" SG_ 993 NUM_CYL 15;
BA_ "GenSigSNA" SG_ 993 NUM_CYL "Fh";
BA_ "GenSigCycleTime" SG_ 993 NUM_CYL 100;
BA_ "FlexKomSigStartValue" SG_ 993 NUM_CYL "FFEFE7E7h";
BA_ "FlexKomSigStartPos" SG_ 993 NUM_CYL 7;
BA_ "FlexKomSigName" SG_ 993 NUM_CYL "ENG_CFG";
BA_ "FlexKomSigLaenge" SG_ 993 NUM_CYL 32;
BA_ "FlexKomSID" SG_ 993 NUM_CYL 617;
BA_ "FlexKomIsMotorola" SG_ 993 NUM_CYL 1;
BA_ "FlexKomComment" SG_ 993 NUM_CYL "Engine Configuration Information";
BA_ "RID" SG_ 993 FUEL_TYPE "1261";
BA_ "GenSigTimeout_ORC" SG_ 993 FUEL_TYPE 350;
BA_ "GenSigTimeout_IC" SG_ 993 FUEL_TYPE 1050;
BA_ "GenSigTimeout_EHPS" SG_ 993 FUEL_TYPE 1050;
BA_ "GenSigTimeout_CBC" SG_ 993 FUEL_TYPE 1050;
BA_ "GenSigStartValue" SG_ 993 FUEL_TYPE 7;
BA_ "GenSigSNA" SG_ 993 FUEL_TYPE "7h";
BA_ "GenSigCycleTime" SG_ 993 FUEL_TYPE 100;
BA_ "FlexKomSigStartValue" SG_ 993 FUEL_TYPE "FFEFE7E7h";
BA_ "FlexKomSigStartPos" SG_ 993 FUEL_TYPE 7;
BA_ "FlexKomSigName" SG_ 993 FUEL_TYPE "ENG_CFG";
BA_ "FlexKomSigLaenge" SG_ 993 FUEL_TYPE 32;
BA_ "FlexKomSID" SG_ 993 FUEL_TYPE 617;
BA_ "FlexKomIsMotorola" SG_ 993 FUEL_TYPE 1;
BA_ "FlexKomComment" SG_ 993 FUEL_TYPE "Engine Configuration Information";
BA_ "GenSigSNA" SG_ 910 IBS3_SOH_Q_Accuracy "0h";
BA_ "GenSigCycleTime" SG_ 910 IBS3_SOH_Q_Accuracy 2000;
BA_ "FlexKomSigStartValue" SG_ 910 IBS3_SOH_Q_Accuracy "00FFFF7F7F80h";
BA_ "FlexKomSigStartPos" SG_ 910 IBS3_SOH_Q_Accuracy 23;
BA_ "FlexKomSigName" SG_ 910 IBS3_SOH_Q_Accuracy "GW_LIN_I_C6_Pkt2";
BA_ "FlexKomSigLaenge" SG_ 910 IBS3_SOH_Q_Accuracy 48;
BA_ "FlexKomSID" SG_ 910 IBS3_SOH_Q_Accuracy 2657;
BA_ "FlexKomIsMotorola" SG_ 910 IBS3_SOH_Q_Accuracy 1;
BA_ "FlexKomComment" SG_ 910 IBS3_SOH_Q_Accuracy "Cyclic only";
BA_ "GenSigTimeout_ORC" SG_ 35 VLRW 35;
BA_ "GenSigTimeout_ETM" SG_ 35 VLRW 105;
BA_ "GenSigTimeout_EHPS" SG_ 35 VLRW 105;
BA_ "GenSigTimeout_DTCM" SG_ 35 VLRW 105;
BA_ "GenSigStartValue" SG_ 35 VLRW 16383;
BA_ "GenSigSNA" SG_ 35 VLRW "3FFFh";
BA_ "GenSigCycleTime" SG_ 35 VLRW 10;
BA_ "FlexKomSigStartValue" SG_ 35 VLRW "3FFF3FFF030000FFh";
BA_ "FlexKomSigStartPos" SG_ 35 VLRW 7;
BA_ "FlexKomSigName" SG_ 35 VLRW "LRW_ST";
BA_ "FlexKomSigLaenge" SG_ 35 VLRW 64;
BA_ "FlexKomSID" SG_ 35 VLRW 418;
BA_ "FlexKomIsMotorola" SG_ 35 VLRW 1;
BA_ "FlexKomComment" SG_ 35 VLRW "Steering wheel angle state";
BA_ "GenSigTimeout_ORC" SG_ 35 MC_STW_Angle_STAT 35;
BA_ "GenSigTimeout_ETM" SG_ 35 MC_STW_Angle_STAT 105;
BA_ "GenSigSNA" SG_ 35 MC_STW_Angle_STAT "0h";
BA_ "GenSigCycleTime" SG_ 35 MC_STW_Angle_STAT 10;
BA_ "FlexKomSigStartValue" SG_ 35 MC_STW_Angle_STAT "3FFF3FFF030000FFh";
BA_ "FlexKomSigStartPos" SG_ 35 MC_STW_Angle_STAT 7;
BA_ "FlexKomSigName" SG_ 35 MC_STW_Angle_STAT "LRW_ST";
BA_ "FlexKomSigLaenge" SG_ 35 MC_STW_Angle_STAT 64;
BA_ "FlexKomSID" SG_ 35 MC_STW_Angle_STAT 418;
BA_ "FlexKomIsMotorola" SG_ 35 MC_STW_Angle_STAT 1;
BA_ "FlexKomComment" SG_ 35 MC_STW_Angle_STAT "Steering wheel angle state";
BA_ "GenSigTimeout_IC" SG_ 1000 VC_HDC_Prsnt 5250;
BA_ "GenSigSNA" SG_ 1000 VC_HDC_Prsnt "0h";
BA_ "GenSigSendType" SG_ 1000 VC_HDC_Prsnt 5;
BA_ "GenSigCycleTime" SG_ 1000 VC_HDC_Prsnt 500;
BA_ "FlexKomSigStartValue" SG_ 1000 VC_HDC_Prsnt "FFFF7FF0FF0FFF00h";
BA_ "FlexKomSigStartPos" SG_ 1000 VC_HDC_Prsnt 7;
BA_ "FlexKomSigName" SG_ 1000 VC_HDC_Prsnt "VehCfg1_Pkt";
BA_ "FlexKomSigLaenge" SG_ 1000 VC_HDC_Prsnt 64;
BA_ "FlexKomSID" SG_ 1000 VC_HDC_Prsnt 886;
BA_ "FlexKomIsMotorola" SG_ 1000 VC_HDC_Prsnt 1;
BA_ "FlexKomComment" SG_ 1000 VC_HDC_Prsnt "Vehicle Configuration 1 Packet";
BA_ "GenSigSNA" SG_ 1000 VC_XWD "0h";
BA_ "GenSigSendType" SG_ 1000 VC_XWD 5;
BA_ "GenSigCycleTime" SG_ 1000 VC_XWD 500;
BA_ "FlexKomSigStartValue" SG_ 1000 VC_XWD "FFFF7FF0FF0FFF00h";
BA_ "FlexKomSigStartPos" SG_ 1000 VC_XWD 7;
BA_ "FlexKomSigName" SG_ 1000 VC_XWD "VehCfg1_Pkt";
BA_ "FlexKomSigLaenge" SG_ 1000 VC_XWD 64;
BA_ "FlexKomSID" SG_ 1000 VC_XWD 886;
BA_ "FlexKomIsMotorola" SG_ 1000 VC_XWD 1;
BA_ "FlexKomComment" SG_ 1000 VC_XWD "Vehicle Configuration 1 Packet";
BA_ "GenSigStartValue" SG_ 993 NUM_VALVE 7;
BA_ "GenSigSNA" SG_ 993 NUM_VALVE "7h";
BA_ "GenSigCycleTime" SG_ 993 NUM_VALVE 100;
BA_ "FlexKomSigStartValue" SG_ 993 NUM_VALVE "FFEFE7E7h";
BA_ "FlexKomSigStartPos" SG_ 993 NUM_VALVE 7;
BA_ "FlexKomSigName" SG_ 993 NUM_VALVE "ENG_CFG";
BA_ "FlexKomSigLaenge" SG_ 993 NUM_VALVE 32;
BA_ "FlexKomSID" SG_ 993 NUM_VALVE 617;
BA_ "FlexKomIsMotorola" SG_ 993 NUM_VALVE 1;
BA_ "FlexKomComment" SG_ 993 NUM_VALVE "Engine Configuration Information";
BA_ "RID" SG_ 993 EngStyle "1062";
BA_ "GenSigTimeout_CBC" SG_ 993 EngStyle 1050;
BA_ "GenSigStartValue" SG_ 993 EngStyle 7;
BA_ "GenSigSNA" SG_ 993 EngStyle "7h";
BA_ "GenSigCycleTime" SG_ 993 EngStyle 100;
BA_ "FlexKomSigStartValue" SG_ 993 EngStyle "FFEFE7E7h";
BA_ "FlexKomSigStartPos" SG_ 993 EngStyle 7;
BA_ "FlexKomSigName" SG_ 993 EngStyle "ENG_CFG";
BA_ "FlexKomSigLaenge" SG_ 993 EngStyle 32;
BA_ "FlexKomSID" SG_ 993 EngStyle 617;
BA_ "FlexKomIsMotorola" SG_ 993 EngStyle 1;
BA_ "FlexKomComment" SG_ 993 EngStyle "Engine Configuration Information";
BA_ "GenSigTimeout_ORC" SG_ 35 CRC_STW_Angle_STAT 35;
BA_ "GenSigTimeout_ETM" SG_ 35 CRC_STW_Angle_STAT 105;
BA_ "GenSigStartValue" SG_ 35 CRC_STW_Angle_STAT 255;
BA_ "GenSigSNA" SG_ 35 CRC_STW_Angle_STAT "FFh";
BA_ "GenSigCycleTime" SG_ 35 CRC_STW_Angle_STAT 10;
BA_ "FlexKomSigStartValue" SG_ 35 CRC_STW_Angle_STAT "3FFF3FFF030000FFh";
BA_ "FlexKomSigStartPos" SG_ 35 CRC_STW_Angle_STAT 7;
BA_ "FlexKomSigName" SG_ 35 CRC_STW_Angle_STAT "LRW_ST";
BA_ "FlexKomSigLaenge" SG_ 35 CRC_STW_Angle_STAT 64;
BA_ "FlexKomSID" SG_ 35 CRC_STW_Angle_STAT 418;
BA_ "GenSigTimeout_OCM" SG_ 1000 VC_VehCfg1_Stat 5250;
BA_ "GenSigTimeout_IC" SG_ 1000 VC_VehCfg1_Stat 5250;
BA_ "GenSigTimeout_ESM" SG_ 1000 VC_VehCfg1_Stat 5250;
BA_ "GenSigTimeout_EHPS" SG_ 1000 VC_VehCfg1_Stat 5250;
BA_ "GenSigTimeout_DTCM" SG_ 1000 VC_VehCfg1_Stat 5250;
BA_ "GenSigTimeout_DPDM" SG_ 1000 VC_VehCfg1_Stat 5250;
BA_ "GenSigStartValue" SG_ 1000 VC_VehCfg1_Stat 3;
BA_ "GenSigSNA" SG_ 1000 VC_VehCfg1_Stat "3h";
BA_ "GenSigSendType" SG_ 1000 VC_VehCfg1_Stat 5;
BA_ "GenSigCycleTime" SG_ 1000 VC_VehCfg1_Stat 500;
BA_ "FlexKomSigStartValue" SG_ 1000 VC_VehCfg1_Stat "FFFF7FF0FF0FFF00h";
BA_ "FlexKomSigStartPos" SG_ 1000 VC_VehCfg1_Stat 7;
BA_ "FlexKomSigName" SG_ 1000 VC_VehCfg1_Stat "VehCfg1_Pkt";
BA_ "FlexKomSigLaenge" SG_ 1000 VC_VehCfg1_Stat 64;
BA_ "FlexKomSID" SG_ 1000 VC_VehCfg1_Stat 886;
BA_ "FlexKomIsMotorola" SG_ 1000 VC_VehCfg1_Stat 1;
BA_ "FlexKomComment" SG_ 1000 VC_VehCfg1_Stat "Vehicle Configuration 1 Packet";
BA_ "GenSigSNA" SG_ 293 TRNS_StpSt_FLT "1h";
BA_ "GenSigCycleTime" SG_ 293 TRNS_StpSt_FLT 100;
BA_ "FlexKomSigStartValue" SG_ 293 TRNS_StpSt_FLT "01h";
BA_ "FlexKomSigStartPos" SG_ 293 TRNS_StpSt_FLT 23;
BA_ "FlexKomSigName" SG_ 293 TRNS_StpSt_FLT "TRNS_StpSt_FLT";
BA_ "FlexKomSigLaenge" SG_ 293 TRNS_StpSt_FLT 1;
BA_ "FlexKomSID" SG_ 293 TRNS_StpSt_FLT 1399;
BA_ "FlexKomIsMotorola" SG_ 293 TRNS_StpSt_FLT 1;
BA_ "FlexKomComment" SG_ 293 TRNS_StpSt_FLT "Trans stop start fault (1=fault)";
BA_ "GenSigStartValue" SG_ 55 CRC_TCM_EngTrq2 255;
BA_ "GenSigSNA" SG_ 55 CRC_TCM_EngTrq2 "FFh";
BA_ "GenSigCycleTime" SG_ 55 CRC_TCM_EngTrq2 10;
BA_ "FlexKomSigStartValue" SG_ 55 CRC_TCM_EngTrq2 "1FFF1FFF1FFF00FFh";
BA_ "FlexKomSigStartPos" SG_ 55 CRC_TCM_EngTrq2 7;
BA_ "FlexKomSigName" SG_ 55 CRC_TCM_EngTrq2 "TCM_EngTrq2_Pkt";
BA_ "FlexKomSigLaenge" SG_ 55 CRC_TCM_EngTrq2 64;
BA_ "FlexKomSID" SG_ 55 CRC_TCM_EngTrq2 1379;
BA_ "FlexKomIsMotorola" SG_ 55 CRC_TCM_EngTrq2 1;
BA_ "FlexKomComment" SG_ 55 CRC_TCM_EngTrq2 "Engine Torque Pkt";
BA_ "GenSigSNA" SG_ 149 TxIdleRq "FFh";
BA_ "GenSigCycleTime" SG_ 149 TxIdleRq 20;
BA_ "FlexKomSigStartValue" SG_ 149 TxIdleRq "07FF001FFF00FFh";
BA_ "FlexKomSigStartPos" SG_ 149 TxIdleRq 7;
BA_ "FlexKomSigName" SG_ 149 TxIdleRq "ENG_TRQ_PKT";
BA_ "FlexKomSigLaenge" SG_ 149 TxIdleRq 56;
BA_ "FlexKomSID" SG_ 149 TxIdleRq 788;
BA_ "FlexKomIsMotorola" SG_ 149 TxIdleRq 1;
BA_ "FlexKomComment" SG_ 149 TxIdleRq "Engine torque packet for all transmissions";
BA_ "GenSigSNA" SG_ 171 WarmUpRq_NotAchieved "0h";
BA_ "GenSigCycleTime" SG_ 171 WarmUpRq_NotAchieved 20;
BA_ "FlexKomSigStartValue" SG_ 171 WarmUpRq_NotAchieved "0FFF0F0F000000FFh";
BA_ "FlexKomSigStartPos" SG_ 171 WarmUpRq_NotAchieved 7;
BA_ "FlexKomSigName" SG_ 171 WarmUpRq_NotAchieved "TCM_A7_PKT";
BA_ "FlexKomSigLaenge" SG_ 171 WarmUpRq_NotAchieved 64;
BA_ "FlexKomSID" SG_ 171 WarmUpRq_NotAchieved 1613;
BA_ "FlexKomIsMotorola" SG_ 171 WarmUpRq_NotAchieved 1;
BA_ "FlexKomComment" SG_ 171 WarmUpRq_NotAchieved "Transmission message A7 packet";
BA_ "GenSigSNA" SG_ 1464 ECU_APPL_ECM "0h";
BA_ "GenSigSendType" SG_ 1464 ECU_APPL_ECM 1;
BA_ "FlexKomSigStartValue" SG_ 1464 ECU_APPL_ECM "0000000000000000h";
BA_ "FlexKomSigStartPos" SG_ 1464 ECU_APPL_ECM 7;
BA_ "FlexKomSigName" SG_ 1464 ECU_APPL_ECM "ECU_APPL_ECM";
BA_ "FlexKomSigLaenge" SG_ 1464 ECU_APPL_ECM 64;
BA_ "FlexKomSID" SG_ 1464 ECU_APPL_ECM 352;
BA_ "FlexKomIsMotorola" SG_ 1464 ECU_APPL_ECM 1;
BA_ "FlexKomComment" SG_ 1464 ECU_APPL_ECM "ECU to External Application";
BA_ "GenSigTimeout_IC" SG_ 996 NetCfg_RF_HUB 21000;
BA_ "GenSigSNA" SG_ 996 NetCfg_RF_HUB "0h";
BA_ "GenSigSendType" SG_ 996 NetCfg_RF_HUB 5;
BA_ "GenSigCycleTime" SG_ 996 NetCfg_RF_HUB 2000;
BA_ "FlexKomSigStartValue" SG_ 996 NetCfg_RF_HUB "0300000000000000h";
BA_ "FlexKomSigStartPos" SG_ 996 NetCfg_RF_HUB 7;
BA_ "FlexKomSigName" SG_ 996 NetCfg_RF_HUB "NET_CFG_DATA_PT";
BA_ "FlexKomSigLaenge" SG_ 996 NetCfg_RF_HUB 64;
BA_ "FlexKomSID" SG_ 996 NetCfg_RF_HUB 39;
BA_ "FlexKomIsMotorola" SG_ 996 NetCfg_RF_HUB 1;
BA_ "FlexKomComment" SG_ 996 NetCfg_RF_HUB "Network ECU config data for Powertrain";
BA_ "FlexKomSigStartPos" SG_ 1000 VC_BODY_STYLE 7;
BA_ "FlexKomSigName" SG_ 1000 VC_BODY_STYLE "VehCfg1_Pkt";
BA_ "FlexKomSigLaenge" SG_ 1000 VC_BODY_STYLE 64;
BA_ "FlexKomSID" SG_ 1000 VC_BODY_STYLE 886;
BA_ "FlexKomIsMotorola" SG_ 1000 VC_BODY_STYLE 1;
BA_ "GenSigStartValue" SG_ 133 Gr 15;
BA_ "GenSigSNA" SG_ 133 Gr "Fh";
BA_ "GenSigCycleTime" SG_ 133 Gr 20;
BA_ "FlexKomSigStartValue" SG_ 133 Gr "FF00h";
BA_ "FlexKomSigStartPos" SG_ 133 Gr 15;
BA_ "FlexKomSigName" SG_ 133 Gr "Gear_Pkt";
BA_ "FlexKomSigLaenge" SG_ 133 Gr 16;
BA_ "FlexKomSID" SG_ 133 Gr 1128;
BA_ "FlexKomIsMotorola" SG_ 133 Gr 1;
BA_ "FlexKomComment" SG_ 133 Gr "Current Gear/Target Gear";
BA_ "GenSigSNA" SG_ 133 K_O_B "0h";
BA_ "GenSigCycleTime" SG_ 133 K_O_B 20;
BA_ "FlexKomSigStartValue" SG_ 133 K_O_B "000000h";
BA_ "FlexKomSigStartPos" SG_ 133 K_O_B 7;
BA_ "FlexKomSigName" SG_ 133 K_O_B "K_B";
BA_ "FlexKomSigLaenge" SG_ 133 K_O_B 24;
BA_ "FlexKomSID" SG_ 133 K_O_B 1129;
BA_ "FlexKomIsMotorola" SG_ 133 K_O_B 1;
BA_ "FlexKomComment" SG_ 133 K_O_B "Torque converter lock-up status";
BA_ "GenSigSNA" SG_ 133 K_S_B "0h";
BA_ "GenSigCycleTime" SG_ 133 K_S_B 20;
BA_ "FlexKomSigStartValue" SG_ 133 K_S_B "000000h";
BA_ "FlexKomSigStartPos" SG_ 133 K_S_B 7;
BA_ "FlexKomSigName" SG_ 133 K_S_B "K_B";
BA_ "FlexKomSigLaenge" SG_ 133 K_S_B 24;
BA_ "FlexKomSID" SG_ 133 K_S_B 1129;
BA_ "FlexKomIsMotorola" SG_ 133 K_S_B 1;
BA_ "FlexKomComment" SG_ 133 K_S_B "Torque converter lock-up status";
BA_ "GenSigStartValue" SG_ 55 MaxTrqDes 8191;
BA_ "GenSigSNA" SG_ 55 MaxTrqDes "1FFFh";
BA_ "GenSigCycleTime" SG_ 55 MaxTrqDes 10;
BA_ "FlexKomSigStartValue" SG_ 55 MaxTrqDes "1FFF1FFF1FFF00FFh";
BA_ "FlexKomSigStartPos" SG_ 55 MaxTrqDes 7;
BA_ "FlexKomSigName" SG_ 55 MaxTrqDes "TCM_EngTrq2_Pkt";
BA_ "FlexKomSigLaenge" SG_ 55 MaxTrqDes 64;
BA_ "FlexKomSID" SG_ 55 MaxTrqDes 1379;
BA_ "FlexKomIsMotorola" SG_ 55 MaxTrqDes 1;
BA_ "FlexKomComment" SG_ 55 MaxTrqDes "Engine Torque Pkt";
BA_ "GenSigSNA" SG_ 149 REPRGD_PFC_CLR_TCM "0h";
BA_ "GenSigCycleTime" SG_ 149 REPRGD_PFC_CLR_TCM 20;
BA_ "FlexKomSigStartValue" SG_ 149 REPRGD_PFC_CLR_TCM "07FF001FFF00FFh";
BA_ "FlexKomSigStartPos" SG_ 149 REPRGD_PFC_CLR_TCM 7;
BA_ "FlexKomSigName" SG_ 149 REPRGD_PFC_CLR_TCM "ENG_TRQ_PKT";
BA_ "FlexKomSigLaenge" SG_ 149 REPRGD_PFC_CLR_TCM 56;
BA_ "FlexKomSID" SG_ 149 REPRGD_PFC_CLR_TCM 788;
BA_ "FlexKomIsMotorola" SG_ 149 REPRGD_PFC_CLR_TCM 1;
BA_ "FlexKomComment" SG_ 149 REPRGD_PFC_CLR_TCM "Engine torque packet for all transmissions";
BA_ "GenSigTimeout_IC" SG_ 171 CurrentGearForDisplay 210;
BA_ "GenSigSNA" SG_ 171 CurrentGearForDisplay "Fh";
BA_ "GenSigCycleTime" SG_ 171 CurrentGearForDisplay 20;
BA_ "FlexKomSigStartValue" SG_ 171 CurrentGearForDisplay "0FFF0F0F000000FFh";
BA_ "FlexKomSigStartPos" SG_ 171 CurrentGearForDisplay 7;
BA_ "FlexKomSigName" SG_ 171 CurrentGearForDisplay "TCM_A7_PKT";
BA_ "FlexKomSigLaenge" SG_ 171 CurrentGearForDisplay 64;
BA_ "FlexKomSID" SG_ 171 CurrentGearForDisplay 1613;
BA_ "FlexKomIsMotorola" SG_ 171 CurrentGearForDisplay 1;
BA_ "FlexKomComment" SG_ 171 CurrentGearForDisplay "Transmission message A7 packet";
BA_ "GenSigSNA" SG_ 171 MC_TCM_A7 "0h";
BA_ "GenSigCycleTime" SG_ 171 MC_TCM_A7 20;
BA_ "FlexKomSigStartValue" SG_ 171 MC_TCM_A7 "0FFF0F0F000000FFh";
BA_ "FlexKomSigStartPos" SG_ 171 MC_TCM_A7 7;
BA_ "FlexKomSigName" SG_ 171 MC_TCM_A7 "TCM_A7_PKT";
BA_ "FlexKomSigLaenge" SG_ 171 MC_TCM_A7 64;
BA_ "FlexKomSID" SG_ 171 MC_TCM_A7 1613;
BA_ "FlexKomIsMotorola" SG_ 171 MC_TCM_A7 1;
BA_ "FlexKomComment" SG_ 171 MC_TCM_A7 "Transmission message A7 packet";
BA_ "RID" SG_ 910 IBS3_SOF_Q "5145";
BA_ "GenSigStartValue" SG_ 910 IBS3_SOF_Q 255;
BA_ "GenSigSNA" SG_ 910 IBS3_SOF_Q "FFh";
BA_ "GenSigCycleTime" SG_ 910 IBS3_SOF_Q 2000;
BA_ "FlexKomSigStartValue" SG_ 910 IBS3_SOF_Q "00FFFF7F7F80h";
BA_ "FlexKomSigStartPos" SG_ 910 IBS3_SOF_Q 23;
BA_ "FlexKomSigName" SG_ 910 IBS3_SOF_Q "GW_LIN_I_C6_Pkt2";
BA_ "FlexKomSigLaenge" SG_ 910 IBS3_SOF_Q 48;
BA_ "FlexKomSID" SG_ 910 IBS3_SOF_Q 2657;
BA_ "FlexKomIsMotorola" SG_ 910 IBS3_SOF_Q 1;
BA_ "FlexKomComment" SG_ 910 IBS3_SOF_Q "Cyclic only";
BA_ "GenSigTimeout_IC" SG_ 171 TX_WARN2 210;
BA_ "RID" SG_ 910 IBS3_SOF_VC "5115";
BA_ "GenSigTimeout_TCM" SG_ 1003 VC_AXLE_RATIO 3500;
BA_ "GenSigStartValue" SG_ 1003 VC_AXLE_RATIO 65535;
BA_ "GenSigSNA" SG_ 1003 VC_AXLE_RATIO "FFFFh";
BA_ "GenSigSendType" SG_ 1003 VC_AXLE_RATIO 5;
BA_ "GenSigCycleTime" SG_ 1003 VC_AXLE_RATIO 1000;
BA_ "FlexKomSigStartValue" SG_ 1003 VC_AXLE_RATIO "FFFFFFFFFFFFFFFFh";
BA_ "FlexKomSigStartPos" SG_ 1003 VC_AXLE_RATIO 7;
BA_ "FlexKomSigName" SG_ 1003 VC_AXLE_RATIO "VehCfg4_Pkt";
BA_ "FlexKomSigLaenge" SG_ 1003 VC_AXLE_RATIO 64;
BA_ "FlexKomSID" SG_ 1003 VC_AXLE_RATIO 1035;
BA_ "FlexKomIsMotorola" SG_ 1003 VC_AXLE_RATIO 1;
BA_ "FlexKomComment" SG_ 1003 VC_AXLE_RATIO "Vehicle Configuration 4 Packet";
BA_ "GenSigSNA" SG_ 897 VC_HybridType "0h";
BA_ "GenSigSendType" SG_ 897 VC_HybridType 5;
BA_ "GenSigCycleTime" SG_ 897 VC_HybridType 2000;
BA_ "FlexKomSigStartValue" SG_ 897 VC_HybridType "033F000000000000h";
BA_ "FlexKomSigStartPos" SG_ 897 VC_HybridType 7;
BA_ "FlexKomSigName" SG_ 897 VC_HybridType "VehCfg7_Pkt";
BA_ "FlexKomSigLaenge" SG_ 897 VC_HybridType 64;
BA_ "FlexKomSID" SG_ 897 VC_HybridType 2026;
BA_ "FlexKomIsMotorola" SG_ 897 VC_HybridType 1;
BA_ "FlexKomComment" SG_ 897 VC_HybridType "Vehicle Configuration 7 Packet";
BA_ "GenSigTimeout_ORC" SG_ 897 VC_ACC_Type 7000;
BA_ "GenSigSNA" SG_ 897 VC_ACC_Type "0h";
BA_ "GenSigSendType" SG_ 897 VC_ACC_Type 5;
BA_ "GenSigCycleTime" SG_ 897 VC_ACC_Type 2000;
BA_ "FlexKomSigStartValue" SG_ 897 VC_ACC_Type "033F000000000000h";
BA_ "FlexKomSigStartPos" SG_ 897 VC_ACC_Type 7;
BA_ "FlexKomSigName" SG_ 897 VC_ACC_Type "VehCfg7_Pkt";
BA_ "FlexKomSigLaenge" SG_ 897 VC_ACC_Type 64;
BA_ "FlexKomSID" SG_ 897 VC_ACC_Type 2026;
BA_ "FlexKomIsMotorola" SG_ 897 VC_ACC_Type 1;
BA_ "FlexKomComment" SG_ 897 VC_ACC_Type "Vehicle Configuration 7 Packet";
BA_ "GenSigTimeout_SCCM" SG_ 1000 VC_COUNTRY 5250;
BA_ "GenSigTimeout_ORC" SG_ 1000 VC_COUNTRY 1750;
BA_ "GenSigTimeout_IC" SG_ 1000 VC_COUNTRY 5250;
BA_ "GenSigTimeout_ESM" SG_ 1000 VC_COUNTRY 5250;
BA_ "GenSigTimeout_EHPS" SG_ 1000 VC_COUNTRY 5250;
BA_ "GenSigTimeout_DTCM" SG_ 1000 VC_COUNTRY 5250;
BA_ "GenSigStartValue" SG_ 1000 VC_COUNTRY 31;
BA_ "GenSigSNA" SG_ 1000 VC_COUNTRY "1Fh";
BA_ "GenSigSendType" SG_ 1000 VC_COUNTRY 5;
BA_ "GenSigCycleTime" SG_ 1000 VC_COUNTRY 500;
BA_ "FlexKomSigStartValue" SG_ 1000 VC_COUNTRY "FFFF7FF0FF0FFF00h";
BA_ "FlexKomSigStartPos" SG_ 1000 VC_COUNTRY 7;
BA_ "FlexKomSigName" SG_ 1000 VC_COUNTRY "VehCfg1_Pkt";
BA_ "FlexKomSigLaenge" SG_ 1000 VC_COUNTRY 64;
BA_ "FlexKomSID" SG_ 1000 VC_COUNTRY 886;
BA_ "FlexKomIsMotorola" SG_ 1000 VC_COUNTRY 1;
BA_ "FlexKomComment" SG_ 1000 VC_COUNTRY "Vehicle Configuration 1 Packet";
BA_ "GenSigTimeout_IC" SG_ 1000 VC_SSC_Prsnt 5250;
BA_ "GenSigSNA" SG_ 1000 VC_SSC_Prsnt "0h";
BA_ "GenSigSendType" SG_ 1000 VC_SSC_Prsnt 5;
BA_ "GenSigCycleTime" SG_ 1000 VC_SSC_Prsnt 500;
BA_ "FlexKomSigStartValue" SG_ 1000 VC_SSC_Prsnt "FFFF7FF0FF0FFF00h";
BA_ "FlexKomSigStartPos" SG_ 1000 VC_SSC_Prsnt 7;
BA_ "FlexKomSigName" SG_ 1000 VC_SSC_Prsnt "VehCfg1_Pkt";
BA_ "FlexKomSigLaenge" SG_ 1000 VC_SSC_Prsnt 64;
BA_ "FlexKomSID" SG_ 1000 VC_SSC_Prsnt 886;
BA_ "FlexKomIsMotorola" SG_ 1000 VC_SSC_Prsnt 1;
BA_ "FlexKomComment" SG_ 1000 VC_SSC_Prsnt "Vehicle Configuration 1 Packet";
BA_ "RID" SG_ 147 SHFT_PROG "1118";
BA_ "GenSigTimeout_IC" SG_ 147 SHFT_PROG 210;
BA_ "GenSigTimeout_ESM" SG_ 147 SHFT_PROG 410;
BA_ "GenSigTimeout_DTCM" SG_ 147 SHFT_PROG 410;
BA_ "GenSigTimeout_CBC" SG_ 147 SHFT_PROG 210;
BA_ "GenSigStartValue" SG_ 147 SHFT_PROG 255;
BA_ "GenSigSNA" SG_ 147 SHFT_PROG "FFh";
BA_ "GenSigCycleTime" SG_ 147 SHFT_PROG 20;
BA_ "FlexKomSigStartValue" SG_ 147 SHFT_PROG "1CFFFF00000000FFh";
BA_ "FlexKomSigStartPos" SG_ 147 SHFT_PROG 7;
BA_ "FlexKomSigName" SG_ 147 SHFT_PROG "TRNS_STAT_PKT";
BA_ "FlexKomSigLaenge" SG_ 147 SHFT_PROG 64;
BA_ "FlexKomSID" SG_ 147 SHFT_PROG 1366;
BA_ "GenSigTimeout_IC" SG_ 996 NetCfg_SCCM 21000;
BA_ "GenSigTimeout_EHPS" SG_ 996 NetCfg_SCCM 21000;
BA_ "GenSigTimeout_DTCM" SG_ 996 NetCfg_SCCM 21000;
BA_ "GenSigSNA" SG_ 996 NetCfg_SCCM "0h";
BA_ "GenSigSendType" SG_ 996 NetCfg_SCCM 5;
BA_ "GenSigCycleTime" SG_ 996 NetCfg_SCCM 2000;
BA_ "FlexKomSigStartValue" SG_ 996 NetCfg_SCCM "0300000000000000h";
BA_ "FlexKomSigStartPos" SG_ 996 NetCfg_SCCM 7;
BA_ "FlexKomSigName" SG_ 996 NetCfg_SCCM "NET_CFG_DATA_PT";
BA_ "FlexKomSigLaenge" SG_ 996 NetCfg_SCCM 64;
BA_ "FlexKomSID" SG_ 996 NetCfg_SCCM 39;
BA_ "FlexKomIsMotorola" SG_ 996 NetCfg_SCCM 1;
BA_ "FlexKomComment" SG_ 996 NetCfg_SCCM "Network ECU config data for Powertrain";
BA_ "GenSigTimeout_ORC" SG_ 996 NetCfg_ESC 7000;
BA_ "GenSigTimeout_IC" SG_ 996 NetCfg_ESC 21000;
BA_ "GenSigTimeout_ESM" SG_ 996 NetCfg_ESC 21000;
BA_ "GenSigTimeout_EHPS" SG_ 996 NetCfg_ESC 21000;
BA_ "GenSigTimeout_DTCM" SG_ 996 NetCfg_ESC 21000;
BA_ "GenSigTimeout_ORC" SG_ 293 GS_NOTL 350;
BA_ "GenSigSNA" SG_ 293 GS_NOTL "0h";
BA_ "GenSigCycleTime" SG_ 293 GS_NOTL 100;
BA_ "FlexKomSigStartValue" SG_ 293 GS_NOTL "00h";
BA_ "FlexKomSigStartPos" SG_ 293 GS_NOTL 2;
BA_ "FlexKomSigName" SG_ 293 GS_NOTL "GS_NOTL";
BA_ "FlexKomSigLaenge" SG_ 293 GS_NOTL 1;
BA_ "FlexKomSID" SG_ 293 GS_NOTL 1143;
BA_ "FlexKomIsMotorola" SG_ 293 GS_NOTL 1;
BA_ "FlexKomComment" SG_ 293 GS_NOTL "TRANS in limp home mode";
BA_ "RID" SG_ 293 TX_TEMP "1265";
BA_ "GenSigTimeout_IC" SG_ 293 TX_TEMP 1050;
BA_ "GenSigTimeout_ETM" SG_ 293 TX_TEMP 1050;
BA_ "GenSigTimeout_CBC" SG_ 293 TX_TEMP 1050;
BA_ "GenSigStartValue" SG_ 293 TX_TEMP 255;
BA_ "GenSigSNA" SG_ 293 TX_TEMP "FFh";
BA_ "GenSigCycleTime" SG_ 293 TX_TEMP 100;
BA_ "FlexKomSigStartValue" SG_ 293 TX_TEMP "FFh";
BA_ "FlexKomSigStartPos" SG_ 293 TX_TEMP 15;
BA_ "FlexKomSigName" SG_ 293 TX_TEMP "TX_TEMP";
BA_ "FlexKomSigLaenge" SG_ 293 TX_TEMP 8;
BA_ "FlexKomSID" SG_ 293 TX_TEMP 1146;
BA_ "FlexKomIsMotorola" SG_ 293 TX_TEMP 1;
BA_ "FlexKomComment" SG_ 293 TX_TEMP "Transmission fluid temperature";
BA_ "GenSigStartValue" SG_ 171 CRC_TCM_A7 255;
BA_ "GenSigSNA" SG_ 171 CRC_TCM_A7 "FFh";
BA_ "GenSigCycleTime" SG_ 171 CRC_TCM_A7 20;
BA_ "FlexKomSigStartValue" SG_ 171 CRC_TCM_A7 "0FFF0F0F000000FFh";
BA_ "FlexKomSigStartPos" SG_ 171 CRC_TCM_A7 7;
BA_ "FlexKomSigName" SG_ 171 CRC_TCM_A7 "TCM_A7_PKT";
BA_ "FlexKomSigLaenge" SG_ 171 CRC_TCM_A7 64;
BA_ "FlexKomSID" SG_ 171 CRC_TCM_A7 1613;
BA_ "FlexKomIsMotorola" SG_ 171 CRC_TCM_A7 1;
BA_ "FlexKomComment" SG_ 171 CRC_TCM_A7 "Transmission message A7 packet";
BA_ "GenSigSendType" SG_ 516 MKKey_6 1;
BA_ "FlexKomSigStartValue" SG_ 516 MKKey_6 "00000000000000h";
BA_ "FlexKomSigStartPos" SG_ 516 MKKey_6 7;
BA_ "FlexKomSigName" SG_ 516 MKKey_6 "IMMO_CODE_RESPONSE";
BA_ "FlexKomSigLaenge" SG_ 516 MKKey_6 56;
BA_ "FlexKomSID" SG_ 516 MKKey_6 2110;
BA_ "FlexKomIsMotorola" SG_ 516 MKKey_6 1;
BA_ "FlexKomComment" SG_ 516 MKKey_6 "Immobilizer code response packet";
BA_ "GenSigSNA" SG_ 517 rnd_1 "0h";
BA_ "GenSigSendType" SG_ 517 rnd_1 1;
BA_ "FlexKomSigStartValue" SG_ 517 rnd_1 "00000000000000h";
BA_ "FlexKomSigStartPos" SG_ 517 rnd_1 7;
BA_ "FlexKomSigName" SG_ 517 rnd_1 "IMMO_CODE_REQUEST";
BA_ "FlexKomSigLaenge" SG_ 517 rnd_1 56;
BA_ "FlexKomSID" SG_ 517 rnd_1 2111;
BA_ "FlexKomIsMotorola" SG_ 517 rnd_1 1;
BA_ "FlexKomComment" SG_ 517 rnd_1 "Immobilizer code request packet";
BA_ "GenSigSNA" SG_ 517 rnd_4 "0h";
BA_ "GenSigSendType" SG_ 517 rnd_4 1;
BA_ "FlexKomSigStartValue" SG_ 517 rnd_4 "00000000000000h";
BA_ "FlexKomSigStartPos" SG_ 517 rnd_4 7;
BA_ "FlexKomSigName" SG_ 517 rnd_4 "IMMO_CODE_REQUEST";
BA_ "FlexKomSigLaenge" SG_ 517 rnd_4 56;
BA_ "FlexKomSID" SG_ 517 rnd_4 2111;
BA_ "FlexKomIsMotorola" SG_ 517 rnd_4 1;
BA_ "FlexKomComment" SG_ 517 rnd_4 "Immobilizer code request packet";
BA_ "GenSigTimeout_ORC" SG_ 1001 VC_VehCfg2_Stat 7000;
BA_ "GenSigTimeout_IC" SG_ 1001 VC_VehCfg2_Stat 21000;
BA_ "GenSigStartValue" SG_ 1001 VC_VehCfg2_Stat 3;
BA_ "GenSigSNA" SG_ 1001 VC_VehCfg2_Stat "3h";
BA_ "GenSigSendType" SG_ 1001 VC_VehCfg2_Stat 5;
BA_ "GenSigCycleTime" SG_ 1001 VC_VehCfg2_Stat 2000;
BA_ "FlexKomSigStartValue" SG_ 1001 VC_VehCfg2_Stat "0300FF00FFFFFFFFh";
BA_ "FlexKomSigStartPos" SG_ 1001 VC_VehCfg2_Stat 7;
BA_ "FlexKomSigName" SG_ 1001 VC_VehCfg2_Stat "VehCfg2_Pkt";
BA_ "FlexKomSigLaenge" SG_ 1001 VC_VehCfg2_Stat 64;
BA_ "FlexKomSID" SG_ 1001 VC_VehCfg2_Stat 887;
BA_ "FlexKomIsMotorola" SG_ 1001 VC_VehCfg2_Stat 1;
BA_ "FlexKomComment" SG_ 1001 VC_VehCfg2_Stat "Vehicle Configuration 2 Packet";
BA_ "GenSigSNA" SG_ 996 NetCfg_ESC "0h";
BA_ "GenSigSendType" SG_ 996 NetCfg_ESC 5;
BA_ "GenSigCycleTime" SG_ 996 NetCfg_ESC 2000;
BA_ "FlexKomSigStartValue" SG_ 996 NetCfg_ESC "0300000000000000h";
BA_ "FlexKomSigStartPos" SG_ 996 NetCfg_ESC 7;
BA_ "FlexKomSigName" SG_ 996 NetCfg_ESC "NET_CFG_DATA_PT";
BA_ "FlexKomSigLaenge" SG_ 996 NetCfg_ESC 64;
BA_ "FlexKomSID" SG_ 996 NetCfg_ESC 39;
BA_ "FlexKomIsMotorola" SG_ 996 NetCfg_ESC 1;
BA_ "FlexKomComment" SG_ 996 NetCfg_ESC "Network ECU config data for Powertrain";
BA_ "GenSigTimeout_IC" SG_ 996 NetCfg_IC 21000;
BA_ "GenSigTimeout_ESM" SG_ 996 NetCfg_IC 21000;
BA_ "GenSigTimeout_EHPS" SG_ 996 NetCfg_IC 21000;
BA_ "GenSigSNA" SG_ 996 NetCfg_IC "0h";
BA_ "GenSigSendType" SG_ 996 NetCfg_IC 5;
BA_ "GenSigCycleTime" SG_ 996 NetCfg_IC 2000;
BA_ "FlexKomSigStartValue" SG_ 996 NetCfg_IC "0300000000000000h";
BA_ "FlexKomSigStartPos" SG_ 996 NetCfg_IC 7;
BA_ "FlexKomSigName" SG_ 996 NetCfg_IC "NET_CFG_DATA_PT";
BA_ "FlexKomSigLaenge" SG_ 996 NetCfg_IC 64;
BA_ "FlexKomSID" SG_ 996 NetCfg_IC 39;
BA_ "FlexKomIsMotorola" SG_ 996 NetCfg_IC 1;
BA_ "FlexKomComment" SG_ 996 NetCfg_IC "Network ECU config data for Powertrain";
BA_ "GenSigSNA" SG_ 2024 D_RS_ECM "0h";
BA_ "GenSigSendType" SG_ 2024 D_RS_ECM 1;
BA_ "FlexKomSigStartValue" SG_ 2024 D_RS_ECM "0000000000000000h";
BA_ "FlexKomSigStartPos" SG_ 2024 D_RS_ECM 7;
BA_ "FlexKomSigName" SG_ 2024 D_RS_ECM "D_RS_ECM";
BA_ "FlexKomSigLaenge" SG_ 2024 D_RS_ECM 64;
BA_ "FlexKomSID" SG_ 2024 D_RS_ECM 139;
BA_ "FlexKomIsMotorola" SG_ 2024 D_RS_ECM 1;
BA_ "FlexKomComment" SG_ 2024 D_RS_ECM "Diagnostic-Response";
BA_ "RID" SG_ 466 Impact_Tgl "1060 2149";
BA_ "GenSigSNA" SG_ 466 Impact_Tgl "0h";
BA_ "GenSigSendType" SG_ 466 Impact_Tgl 2;
BA_ "GenSigCycleTimeActive" SG_ 466 Impact_Tgl 20;
BA_ "FlexKomSigStartValue" SG_ 466 Impact_Tgl "0000h";
BA_ "FlexKomSigStartPos" SG_ 466 Impact_Tgl 7;
BA_ "FlexKomSigName" SG_ 466 Impact_Tgl "IMPACT";
BA_ "FlexKomSigLaenge" SG_ 466 Impact_Tgl 16;
BA_ "FlexKomSID" SG_ 466 Impact_Tgl 325;
BA_ "FlexKomIsMotorola" SG_ 466 Impact_Tgl 1;
BA_ "FlexKomComment" SG_ 466 Impact_Tgl "Impact events";
BA_ "RID" SG_ 147 PRNDL_DISP "1110";
BA_ "GenSigTimeout_IC" SG_ 147 PRNDL_DISP 210;
BA_ "GenSigTimeout_ESM" SG_ 147 PRNDL_DISP 410;
BA_ "GenSigTimeout_DTCM" SG_ 147 PRNDL_DISP 210;
BA_ "GenSigTimeout_CBC" SG_ 147 PRNDL_DISP 210;
BA_ "GenSigStartValue" SG_ 147 PRNDL_DISP 255;
BA_ "GenSigSNA" SG_ 147 PRNDL_DISP "FFh";
BA_ "GenSigCycleTime" SG_ 147 PRNDL_DISP 20;
BA_ "FlexKomSigStartValue" SG_ 147 PRNDL_DISP "1CFFFF00000000FFh";
BA_ "FlexKomSigStartPos" SG_ 147 PRNDL_DISP 7;
BA_ "FlexKomSigName" SG_ 147 PRNDL_DISP "TRNS_STAT_PKT";
BA_ "FlexKomSigLaenge" SG_ 147 PRNDL_DISP 64;
BA_ "FlexKomSID" SG_ 147 PRNDL_DISP 1366;
BA_ "FlexKomIsMotorola" SG_ 147 PRNDL_DISP 1;
BA_ "FlexKomComment" SG_ 147 PRNDL_DISP "TRNS_STAT message packet";
BA_ "GenSigTimeout_IC" SG_ 147 PRNDL_Blink 210;
BA_ "GenSigTimeout_ESM" SG_ 147 PRNDL_Blink 210;
BA_ "GenSigSNA" SG_ 147 PRNDL_Blink "0h";
BA_ "GenSigCycleTime" SG_ 147 PRNDL_Blink 20;
BA_ "FlexKomSigStartValue" SG_ 147 PRNDL_Blink "1CFFFF00000000FFh";
BA_ "FlexKomSigStartPos" SG_ 788 CFG_FEATURE 7;
BA_ "FlexKomSigStartPos" SG_ 147 PRNDL_Blink 7;
BA_ "GenSigTimeout_IC" SG_ 1001 VC_ShftInd_Prsnt 21000;
BA_ "GenSigSNA" SG_ 1001 VC_ShftInd_Prsnt "0h";
BA_ "GenSigSendType" SG_ 1001 VC_ShftInd_Prsnt 5;
BA_ "GenSigCycleTime" SG_ 1001 VC_ShftInd_Prsnt 2000;
BA_ "FlexKomSigStartValue" SG_ 1001 VC_ShftInd_Prsnt "0300FF00FFFFFFFFh";
BA_ "FlexKomSigStartPos" SG_ 1001 VC_ShftInd_Prsnt 7;
BA_ "FlexKomSigName" SG_ 1001 VC_ShftInd_Prsnt "VehCfg2_Pkt";
BA_ "FlexKomSigLaenge" SG_ 1001 VC_ShftInd_Prsnt 64;
BA_ "FlexKomSID" SG_ 1001 VC_ShftInd_Prsnt 887;
BA_ "FlexKomIsMotorola" SG_ 1001 VC_ShftInd_Prsnt 1;
BA_ "FlexKomComment" SG_ 1001 VC_ShftInd_Prsnt "Vehicle Configuration 2 Packet";
BA_ "GenSigSNA" SG_ 517 ControlEncodingRq_205 "0h";
BA_ "GenSigSendType" SG_ 517 ControlEncodingRq_205 1;
BA_ "FlexKomSigStartValue" SG_ 517 ControlEncodingRq_205 "00000000000000h";
BA_ "FlexKomSigStartPos" SG_ 517 ControlEncodingRq_205 7;
BA_ "FlexKomSigName" SG_ 517 ControlEncodingRq_205 "IMMO_CODE_REQUEST";
BA_ "FlexKomSigLaenge" SG_ 517 ControlEncodingRq_205 56;
BA_ "FlexKomSID" SG_ 517 ControlEncodingRq_205 2111;
BA_ "FlexKomIsMotorola" SG_ 517 ControlEncodingRq_205 1;
BA_ "FlexKomComment" SG_ 517 ControlEncodingRq_205 "Immobilizer code request packet";
BA_ "GenSigSNA" SG_ 177 CrusCnclSwitch "0h";
BA_ "GenSigSendType" SG_ 177 CrusCnclSwitch 1;
BA_ "FlexKomSigStartValue" SG_ 177 CrusCnclSwitch "0000FFh";
BA_ "FlexKomSigStartPos" SG_ 177 CrusCnclSwitch 7;
BA_ "FlexKomSigName" SG_ 177 CrusCnclSwitch "CrsCtrlLvrSts";
BA_ "FlexKomSigLaenge" SG_ 177 CrusCnclSwitch 24;
BA_ "FlexKomSID" SG_ 177 CrusCnclSwitch 1848;
BA_ "FlexKomIsMotorola" SG_ 177 CrusCnclSwitch 1;
BA_ "FlexKomComment" SG_ 177 CrusCnclSwitch "Cruise Control Lever Status";
BA_ "GenSigSNA" SG_ 177 DeceleratorSts "0h";
BA_ "GenSigSendType" SG_ 177 DeceleratorSts 1;
BA_ "FlexKomSigStartValue" SG_ 177 DeceleratorSts "0000FFh";
BA_ "FlexKomSigStartPos" SG_ 177 DeceleratorSts 7;
BA_ "FlexKomSigName" SG_ 177 DeceleratorSts "CrsCtrlLvrSts";
BA_ "FlexKomSigLaenge" SG_ 177 DeceleratorSts 24;
BA_ "FlexKomSID" SG_ 177 DeceleratorSts 1848;
BA_ "FlexKomIsMotorola" SG_ 177 DeceleratorSts 1;
BA_ "FlexKomComment" SG_ 177 DeceleratorSts "Cruise Control Lever Status";
BA_ "GenSigTimeout_ORC" SG_ 993 TRANS_TYPE 350;
BA_ "RID" SG_ 788 CFG_SET "1173";
BA_ "GenSigSNA" SG_ 788 CFG_SET "0h";
BA_ "GenSigSendType" SG_ 788 CFG_SET 2;
BA_ "GenSigCycleTimeActive" SG_ 788 CFG_SET 50;
BA_ "FlexKomSigStartValue" SG_ 788 CFG_SET "000000h";
BA_ "FlexKomSigStartPos" SG_ 788 CFG_SET 7;
BA_ "FlexKomSigName" SG_ 788 CFG_SET "CFG_RQ";
BA_ "FlexKomSigLaenge" SG_ 788 CFG_SET 24;
BA_ "FlexKomSID" SG_ 788 CFG_SET 442;
BA_ "FlexKomIsMotorola" SG_ 788 CFG_SET 1;
BA_ "FlexKomComment" SG_ 788 CFG_SET "Configurable display request";
BA_ "FlexKomSID" SG_ 1784 APPL_ECU_ECM 287;
BA_ "FlexKomIsMotorola" SG_ 1784 APPL_ECU_ECM 1;
BA_ "FlexKomComment" SG_ 1784 APPL_ECU_ECM "External Application to ECU";
BA_ "GenSigSNA" SG_ 171 EngShutOffRq_TCM "0h";
BA_ "GenSigCycleTime" SG_ 171 EngShutOffRq_TCM 20;
BA_ "FlexKomSigStartValue" SG_ 171 EngShutOffRq_TCM "0FFF0F0F000000FFh";
BA_ "FlexKomSigStartPos" SG_ 171 EngShutOffRq_TCM 7;
BA_ "FlexKomSigName" SG_ 171 EngShutOffRq_TCM "TCM_A7_PKT";
BA_ "FlexKomSigLaenge" SG_ 171 EngShutOffRq_TCM 64;
BA_ "FlexKomSID" SG_ 171 EngShutOffRq_TCM 1613;
BA_ "FlexKomIsMotorola" SG_ 171 EngShutOffRq_TCM 1;
BA_ "FlexKomComment" SG_ 171 EngShutOffRq_TCM "Transmission message A7 packet";
BA_ "GenSigStartValue" SG_ 171 TargetGear 15;
BA_ "GenSigSNA" SG_ 171 TargetGear "Fh";
BA_ "GenSigCycleTime" SG_ 171 TargetGear 20;
BA_ "FlexKomSigStartValue" SG_ 171 TargetGear "0FFF0F0F000000FFh";
BA_ "FlexKomSigStartPos" SG_ 171 TargetGear 7;
BA_ "FlexKomSigName" SG_ 171 TargetGear "TCM_A7_PKT";
BA_ "FlexKomSigLaenge" SG_ 171 TargetGear 64;
BA_ "FlexKomSID" SG_ 171 TargetGear 1613;
BA_ "FlexKomIsMotorola" SG_ 171 TargetGear 1;
BA_ "FlexKomComment" SG_ 171 TargetGear "Transmission message A7 packet";
BA_ "GenSigSNA" SG_ 864 ECM_APPL1 "0h";
BA_ "GenSigSendType" SG_ 864 ECM_APPL1 1;
BA_ "FlexKomSigStartValue" SG_ 864 ECM_APPL1 "0000000000000000h";
BA_ "FlexKomSigStartPos" SG_ 864 ECM_APPL1 7;
BA_ "FlexKomSigName" SG_ 864 ECM_APPL1 "ECM_APPL1";
BA_ "FlexKomSigLaenge" SG_ 864 ECM_APPL1 64;
BA_ "FlexKomSID" SG_ 864 ECM_APPL1 780;
BA_ "FlexKomIsMotorola" SG_ 864 ECM_APPL1 1;
BA_ "FlexKomComment" SG_ 864 ECM_APPL1 "Application";
BA_ "GenSigSNA" SG_ 896 ECM_APPL4 "0h";
BA_ "GenSigSendType" SG_ 896 ECM_APPL4 1;
BA_ "FlexKomSigStartValue" SG_ 896 ECM_APPL4 "0000000000000000h";
BA_ "FlexKomSigStartPos" SG_ 896 ECM_APPL4 7;
BA_ "FlexKomSigName" SG_ 896 ECM_APPL4 "ECM_APPL4";
BA_ "FlexKomSigLaenge" SG_ 896 ECM_APPL4 64;
BA_ "FlexKomSID" SG_ 896 ECM_APPL4 782;
BA_ "FlexKomIsMotorola" SG_ 896 ECM_APPL4 1;
BA_ "FlexKomComment" SG_ 896 ECM_APPL4 "CCP 5ms DAQ  (from ENGINE to external tool)";
VAL_ 35 LRW 16383 "SNA";
VAL_ 35 VLRW 16383 "SNA";
VAL_ 35 Pad_Shft 0 "PS_OFF" 1 "PS_RIGHT" 2 "PS_LEFT" 3 "PS_BOTH" 7 "SNA";
VAL_ 133 Gr 0 "N" 1 "D1" 2 "D2" 3 "D3" 4 "D4" 5 "D5" 6 "D6" 7 "D7" 8 "D8" 9 "D2P" 10 "D9" 11 "R" 12 "R2" 13 "P" 14 "KRAFTFREI" 15 "SNA";
VAL_ 133 Gr_Target 0 "N" 1 "D1" 2 "D2" 3 "D3" 4 "D4" 5 "D5" 6 "D6" 7 "D7" 8 "D8" 9 "D2P" 10 "D9" 11 "R" 12 "R2" 13 "P" 14 "ABBRUCH" 15 "SNA";
VAL_ 133 OUTPUT_SPEED 65535 "SNA";
VAL_ 133 N_Turb 65535 "SNA";
VAL_ 147 PaddlesModeSts 0 "NONE" 1 "DIS" 2 "EN" 3 "SNA";
VAL_ 147 PRND_STAT 0 "LVR_P" 1 "LVR_R" 2 "LVR_N" 4 "LVR_D" 5 "NOT_R" 7 "SNA";
VAL_ 147 SHFT_PROG 1 "LOW" 2 "SSC" 3 "HDC" 4 "TRACK" 5 "VALET" 7 "SNOW" 11 "MUD" 12 "SAND" 16 "SKIP_SHFT" 24 "UPSHIFT_IND_RQ" 32 "Mud_Sand" 64 "E_MODE" 65 "A" 77 "M" 83 "S" 87 "W" 249 "TX_RACE" 250 "Sport_Plus" 251 "TX_SPORT" 252 "TX_NORM" 253 "OD_OFF" 254 "TX_TOW" 255 "SNA";
VAL_ 147 PRNDL_DISP 32 "BLANK" 49 "ONE" 50 "TWO" 51 "THREE" 52 "FOUR" 53 "FIVE" 54 "SIX" 55 "SEVEN" 56 "EIGHT" 57 "NINE" 65 "A" 68 "D" 70 "F" 76 "L" 77 "M" 78 "N" 80 "P" 82 "R" 83 "S" 128 "DS" 130 "D2" 131 "D3" 132 "D4" 133 "D5" 135 "SNOW" 254 "NOT_N" 255 "SNA";
VAL_ 147 PRNDL_Blink 0 "NONE" 1 "P" 2 "R" 3 "N" 4 "D" 5 "L" 6 "S" 7 "M_TIP";
VAL_ 293 FAN_RQ 15 "SNA";
VAL_ 293 TX_TEMP 255 "SNA";
VAL_ 293 TX_FAULT 0 "OK" 1 "TPF" 3 "SNA";
VAL_ 149 Trans_Trq_Ratio 2047 "SNA";
VAL_ 149 TxIdleRq 255 "SNA";
VAL_ 464 DRV_SEATBELT 0 "DRV_SEATBELT_OK" 1 "DRV_SEATBELT_NOK" 2 "SEATBELT_FAIL" 3 "SNA";
VAL_ 171 CurrentGear 0 "N" 1 "D1" 2 "D2" 3 "D3" 4 "D4" 5 "D5" 6 "D6" 7 "D7" 8 "D8" 9 "D2P" 10 "D9" 11 "R" 12 "R2" 13 "P" 14 "KRAFTFREI" 15 "SNA";
VAL_ 171 CurrentGearForDisplay 0 "Initialize" 1 "D1" 2 "D2" 3 "D3" 4 "D4" 5 "D5" 6 "D6" 7 "D7" 8 "D8" 9 "D9" 12 "P" 13 "N" 14 "R" 15 "SNA";
VAL_ 171 TargetGear 0 "N" 1 "D1" 2 "D2" 3 "D3" 4 "D4" 5 "D5" 6 "D6" 7 "D7" 8 "D8" 9 "D2P" 10 "D9" 11 "R" 12 "R2" 13 "P" 14 "ABBRUCH" 15 "SNA";
VAL_ 171 TX_WARN2 0 "None" 1 "WARN_1" 2 "WARN_2" 3 "WARN_3" 4 "WARN_4" 5 "WARN_5" 6 "WARN_6" 7 "WARN_7" 8 "WARN_8" 9 "WARN_9" 10 "WARN_10" 11 "WARN_11" 12 "WARN_12" 13 "WARN_13" 14 "WARN_14" 15 "WARN_15" 17 "WARN_17" 18 "WARN_18" 19 "WARN_19" 20 "WARN_20" 21 "WARN_21" 22 "WARN_22" 23 "WARN_23" 24 "WARN_24" 25 "WARN_25" 31 "WARN_31" 32 "WARN_32" 33 "WARN_33" 34 "WARN_34" 35 "WARN_35" 36 "WARN_36" 37 "WARN_37" 38 "WARN_38" 39 "WARN_39" 40 "WARN_40" 41 "WARN_41" 42 "WARN_42" 43 "WARN_43" 44 "WARN_44" 45 "WARN_45" 46 "WARN_46" 47 "WARN_47" 48 "WARN_48" 49 "WARN_49" 50 "WARN_50" 51 "WARN_51" 52 "WARN_52" 53 "WARN_53" 54 "WARN_54" 55 "WARN_55" 56 "WARN_56" 57 "WARN_57" 58 "WARN_58" 59 "WARN_59" 60 "WARN_60" 61 "WARN_61" 62 "WARN_62" 63 "WARN_63" 64 "WARN_64" 65 "WARN_65" 66 "WARN_66" 67 "WARN_67" 68 "WARN_68" 69 "WARN_69" 70 "WARN_70" 71 "WARN_71" 72 "WARN_72" 73 "WARN_73" 74 "WARN_74" 75 "WARN_75" 255 "SNA";
VAL_ 173 DrvRqShftROT 0 "INIT" 1 "PARK" 2 "REV" 3 "NEUT" 4 "DRIVE" 5 "FIFTH" 7 "SNA";
VAL_ 173 Manual_Gate_Request 0 "Not_Active" 2 "PLUS" 3 "MINUS" 4 "BOTH" 7 "SNA";
VAL_ 55 EngTrqRq 8191 "SNA";
VAL_ 55 TrqCtrlModeRq 0 "NONE" 1 "TRQ_INC_Fast" 2 "TRQ_DEC_Fast" 7 "SNA";
VAL_ 55 MaxTrqDes 8191 "SNA";
VAL_ 333 VVT_ExhCam1Pos 0 "SNA";
VAL_ 333 VVT_ExhCam2Pos 0 "SNA";
VAL_ 333 VVT_IntCam1Pos 0 "SNA";
VAL_ 333 VVT_IntCam2Pos 0 "SNA";
VAL_ 333 GF_Charge 65535 "SNA";
VAL_ 333 RelativeThrtPct 255 "SNA";
VAL_ 788 CFG_FEATURE 0 "CFG_NONE" 1 "CFG_AUTO_LK" 2 "CFG_AUTO_UNLK" 3 "CFG_DLY_LK" 4 "CFG_DRV_FST" 5 "CFG_SOUND_LK" 6 "CFG_HORN_DUR" 7 "CFG_FLASH_LK" 8 "CFG_DrAlrPrsnt" 9 "CFG_PARK_ASSIST" 10 "CFG_LANG" 11 "CFG_US_METRIC" 12 "CFG_SRV_INTV" 13 "CFG_AUTO_WPR" 14 "CFG_HL_DLY" 15 "CFG_HL_WPR" 16 "CFG_ACC_DLY" 18 "CFG_REM_MEM" 19 "CFG_EASY_EXIT" 20 "CFG_LO_VEH" 21 "CFG_TILT_IN_REV" 22 "CFG_ILL_APRCH" 23 "CFG_ILL_ENTRY" 24 "CFG_GLBL_UP_WIN" 25 "CFG_GLBL_DN_WIN" 26 "CFG_DRL_ON" 27 "CFG_AHB" 28 "REST_FACT_DEF" 29 "CFG_CMP_CAL" 30 "CFG_CMP_VAR" 31 "CFG_VOICE_COMF" 32 "CFG_NAV_TBYT" 33 "CFG_HILL_ST" 34 "CFG_AFS" 35 "CFG_BSD" 36 "CFG_PE" 37 "CFG_WAL" 38 "CFG_DSS" 39 "CFG_SOUND_RS" 40 "CFG_DCS" 41 "CFG_AUTO_RELK" 42 "CFG_CMS" 43 "CFG_FCW" 44 "CFG_PRE_SAFE" 45 "CFG_BELT_SLAK" 46 "CFG_FUEL_SAV" 47 "CFG_FCW_SENS" 48 "CFG_HDLP_DROP" 49 "CFG_ECMM" 50 "PASS_WIN_LKOUT" 51 "AERO" 52 "JACK" 53 "CFG_TRLR" 54 "CFG_ALIGNMENT" 55 "CFG_ASCM_WMO" 57 "CFG_LDW" 58 "OIL" 59 "CFG_NORMAL_DCS" 61 "CFG_TRANSPORT" 62 "CFG_PTO_MODE" 63 "CFG_PTO_SINGLE_RPM" 64 "CFG_PTO_RPM1" 65 "CFG_PTO_RPM2" 66 "CFG_PTO_RPM3" 67 "CFG_PTO_Type" 68 "CFG_PTO_Auto_Resume" 69 "CFG_MAX_PTO_VEH_SPEED" 70 "RVC_GRID" 71 "DIMMER" 72 "RLE_LIGHT" 73 "RLE_HORN" 76 "CFG_TRLR_TYP" 77 "CFG_TRLR_NAME" 81 "CFG_PTS_FT" 82 "CFG_PTS_RR" 83 "CFG_PTS_FT_VOL" 84 "CFG_PTS_RR_VOL" 86 "CFG_PLG" 87 "CFG_AUX1" 88 "CFG_AUX2" 89 "CFG_AUX3" 90 "CFG_AUX4" 91 "CFG_AUX5" 93 "CFG_LDWTRQ" 94 "CFG_PTO_REM_Throttle" 95 "CFG_UNIT_DEFAULT" 96 "CFG_PressureUnit" 97 "CFG_SpeedUnit" 98 "CFG_DistanceUnit" 99 "CFG_ConsumptionUnit" 100 "CFG_CapacityUnit" 101 "CFG_TemperatureUnit" 102 "CFG_PowerUnit" 103 "CFG_TorqueUnit" 104 "CFG_EPS" 105 "CFG_CHMSL_LINES" 106 "CFG_POLICE_PE" 107 "EPB_AUTO_PRK" 108 "EPB_SERVICE" 109 "HOLD_N_GO" 110 "PWR_FLD_MRR" 111 "HANDS_FREE_LFT" 112 "HANDS_FREE_SLDR" 113 "SVC_GRIDLINES" 114 "SVC_DELAY" 115 "SLD_DR_ALRT" 116 "TEEN_FCW_SENS" 117 "TEEN_FCW_BRK" 118 "TEEN_PRK_ASST" 119 "TEEN_PRK_ASST_BRK" 120 "TEEN_FT_PRK_VOL" 121 "TEEN_RR_PRK_VOL" 122 "TEEN_MAX_SPEED" 123 "TEEN_FUEL_WRN" 124 "TEEN_FUEL_POPUP" 125 "TEEN_BLIND_SPOT" 126 "TEEN_RAIN_WPR" 127 "TEEN_AUTO_HB" 128 "TEEN_LGHT_WPR" 129 "TEEN_SLD_DR_ALRT" 130 "TEEN_PLG_CHIME" 131 "SLD_DR_CHM" 132 "TEEN_SLD_DR_CHM" 133 "CFG_ABSM" 134 "CFG_PADDLE_SHIFT" 137 "CFG_PRK_ASST_BRK" 138 "CFG_LDW_ON" 139 "CFG_PRK_ASST_TYPE" 140 "CFG_DR_ALR" 141 "CFG_RDY_DRV" 142 "CFG_PANEL_INTS" 143 "CFG_MOOD_LGT_INTS" 144 "CFG_ML_HDLP_LVL" 145 "CFG_BSM_TRLR" 146 "CFG_AUTO_SS" 147 "CFG_PCS" 148 "CFG_UNIT_SET" 149 "CFG_DOORS_OFF_ACC_DLY" 150 "CFG_MOTORIZED_SEATBELT" 151 "CFG_MOTORIZED_SEATBELT_STRN" 152 "CFG_TSI" 153 "CFG_LKA" 154 "CFG_LKA_SENS" 155 "CFG_LKA_STRN" 156 "CFG_ABSD" 157 "CFG_ABSD_SENS" 158 "CFG_ABSD_STRN" 162 "CFG_TIRE_FILL_ALERT" 163 "CFG_POWER_SIDE_STEP" 164 "CFG_AUTO_STOP_START" 165 "CFG_PEB" 166 "CFG_FFC_GRIDLINES" 167 "CFG_RVC_CVPM_DGRID" 168 "CFG_RVC_CVPM_SGRID" 169 "CFG_SPEED_THRESHOLD_VALUE" 170 "CFG_SPEED_THRESHOLD_CHECK_BOX" 171 "CFG_EXTERNAL_LIGHT_SENSOR" 172 "CFG_BUZZER_VOLUME_LEVEL" 173 "CFG_TRUNK_UNLOCK_ENABLE" 174 "CFG_BACKUP_ALARM" 175 "CFG_RR_CARGO_GUIDE_LGT" 176 "CFG_PTO_HI_IDLE" 177 "CFG_PTO_HI_IDLE_RPM" 178 "CFG_PTO_RMT_RPM_CTRL" 179 "CFG_PTO_SS_GEAR_RATIO" 180 "CFG_PTO_ACC_INT" 181 "CFG_PTO_RAMP_RATE" 182 "CFG_PTO_PB" 183 "CFG_HWRSS" 184 "CFG_SEIU_INPUT_WIRE" 185 "CFG_SEIU_RPM" 186 "CFG_BED_LOWER" 187 "CFG_TSR_WARNING_MODE" 188 "CFG_TSR_WARNING_MODE_OFFSET" 189 "CFG_FT_PK_LOOSE_SHIP" 190 "CFG_RR_PK_LOOSE_SHIP" 191 "CFG_AUX6" 192 "CFG_CHMSL_DYN_CNTR" 193 "CFG_3RD_ROW_LOCK" 194 "CFG_CHARGE_LOW_POPUP" 195 "CFG_ESAVE" 196 "CFG_ESAVE_BATT_LVL" 197 "CFG_FOBIK_SAFE" 198 "CFG_FOB_Left_Vehicle_Chime" 199 "CFG_Theft_Alarm" 200 "CFG_PANIC_ALARM" 201 "CFG_SECURE_PARK_ACTIVATION" 202 "CFG_SECURE_PARK_DEACTIVATION" 203 "CFG_LIFTGATE_RELEASE_INSIDEBUTTON" 204 "CFG_LIFTGATE_RELEASE_UNLOCKWITHDOORS" 205 "CFG_VISM_KEEP_AWAKE" 206 "FOA_Alert_Settings_FOAOnOff_Req" 207 "FOA_Alert_Settings_PhoneAlertOnOff_Req" 208 "CFG_Signature_ON" 209 "CFG_Droswy_Driver_Alert" 210 "CFG_LDW_2_Option" 211 "CFG_TSI_Warning" 212 "CFG_TSI_Speed_Notification" 213 "CFG_SpeedZone_Warn";
VAL_ 788 CFG_STAT_RQ 0 "CFG_DEF" 1 "CFG_DSBL" 2 "CFG_ENBL" 3 "CFG_SPEC";
VAL_ 897 VC_VehCfg7_Stat 0 "NA" 1 "PROGAMMED" 2 "REQUEST_DATA" 3 "SNA";
VAL_ 897 VC_ACC_Type 0 "NONE" 1 "ACC" 2 "STOP" 3 "GO";
VAL_ 992 VIN_MSG 0 "VIN_LO" 1 "VIN_MID" 2 "VIN_HI" 3 "SNA";
VAL_ 993 DISPLACEMENT 255 "SNA";
VAL_ 993 NUM_CYL 15 "SNA";
VAL_ 993 ENG_ASP 0 "INTAKE_NORM" 1 "TURBO1" 2 "TURBO2" 3 "SUPER" 7 "SNA";
VAL_ 993 FUEL_TYPE 0 "UNLEADED" 1 "DIESEL" 2 "FLEX" 3 "CNG" 7 "SNA";
VAL_ 993 ECM_Vehi_Type 0 "STANDARD" 1 "EVEHICLE" 3 "SNA";
VAL_ 993 Manufacture 0 "ENG_DCA" 1 "ENG_DCS" 2 "ENG_MMC" 3 "ENG_HY" 7 "ENG_NP";
VAL_ 993 NUM_VALVE 7 "SNA";
VAL_ 993 EngStyle 0 "CHOICE1" 1 "CHOICE2" 2 "CHOICE3" 3 "CHOICE4" 4 "CHOICE5" 5 "CHOICE6" 7 "SNA";
VAL_ 995 NET_CFG_STAT_INT 0 "NA" 1 "PROGAMMED" 2 "REQUEST_DATA" 3 "SNA";
VAL_ 996 NET_CFG_STAT_PT 0 "NA" 1 "PROGAMMED" 2 "REQUEST_DATA" 3 "SNA";
VAL_ 1000 VC_VehCfg1_Stat 0 "NA" 1 "PROGAMMED" 2 "REQUEST_DATA" 3 "SNA";
VAL_ 1000 VC_MODEL_YEAR 63 "SNA";
VAL_ 1000 VC_VEH_LINE 0 "VEH_NONE" 1 "VEH_WK" 2 "VEH_LX" 22 "VEH_JC" 29 "VEH_DS" 31 "VEH_D2" 32 "VEH_DD" 33 "VEH_DP" 34 "VEH_DJ" 35 "VEH_WD" 39 "VEH_DX" 41 "VEH_LD" 42 "VEH_M156" 43 "VEH_ZD" 44 "VEH_LA" 45 "VEH_RU" 46 "VEH_M161" 47 "VEH_WS" 48 "VEH_DF" 49 "VEH_JL" 50 "VEH_M157" 51 "VEH_RA" 52 "VEH_WL" 53 "VEH_DT" 54 "VEH_DU" 55 "VEH_JT" 56 "VEH_RU_PACIFICA" 80 "VEH_PF" 81 "VEH_KL" 82 "VEH_UF" 83 "VEH_UT" 84 "VEH_M145" 85 "VEH_M145BD" 86 "VEH_K8" 87 "VEH_FF" 88 "FF_Abarth" 108 "VEH_M182" 199 "VEH_598" 200 "VEH_M1" 201 "VEH_M6" 202 "VEH_M4" 203 "VEH_M7" 204 "VEH_MP" 205 "VEH_MV" 255 "SNA";
VAL_ 1000 VC_COUNTRY 0 "ROW" 2 "USA" 3 "EU" 4 "CND" 5 "GB" 6 "JPN" 7 "GER" 8 "SWISS" 9 "MLY" 10 "AUS" 11 "IND" 12 "GULF" 13 "VEN" 14 "MEX" 15 "BRZ" 16 "CHINA" 17 "EGYPT" 20 "S_KOR" 21 "ECE" 22 "AR" 23 "CL" 31 "COUNTRY_SNA";
VAL_ 1000 VC_XWD 0 "2FT" 1 "2RR" 2 "ALLWD" 3 "4WD";
VAL_ 1000 VC_BODY_STYLE 0 "BODY_NONE" 1 "BODY_4DS" 2 "BODY_2DS" 3 "BODY_CONV" 4 "BODY_WAGON" 5 "BODY_4DH" 6 "BODY_2DP" 7 "BODY_4DP" 8 "BODY_4DMP" 15 "BODY_SNA";
VAL_ 1001 VC_VehCfg2_Stat 0 "NA" 1 "PROGAMMED" 2 "REQUEST_DATA" 3 "SNA";
VAL_ 1001 VC_ShftInd_Prsnt 0 "NONE" 1 "GSI" 2 "PSI" 3 "PGSI";
VAL_ 1002 VC_VehCfg3_Stat 0 "NA" 1 "PROGAMMED" 2 "REQUEST_DATA" 3 "SNA";
VAL_ 1003 VC_TCASE_HI_RATIO 16383 "SNA";
VAL_ 1003 VC_VehCfg4_Stat 0 "NA" 1 "PROGAMMED" 2 "REQUEST_DATA" 3 "SNA";
VAL_ 1003 VC_AXLE_RATIO 65535 "SNA";
VAL_ 1003 VC_TCASE_LO_RATIO 65535 "SNA";
VAL_ 1003 VC_TIRE_CIRCUMF 65535 "SNA";
VAL_ 1013 EC_ECUCfg6_Stat 0 "NA" 1 "PROGAMMED" 2 "REQUEST_DATA" 3 "SNA";
VAL_ 1098 VC_VehCfg5_Stat 0 "NA" 1 "PROGAMMED" 2 "REQUEST_DATA" 3 "SNA";
VAL_ 1100 VC_VehCfg6_Stat 0 "NA" 1 "PROGAMMED" 2 "REQUEST_DATA" 3 "SNA";
VAL_ 1100 VC_AnlgDrSnsr 0 "NONE" 1 "DRV" 2 "FT" 3 "ALL";
VAL_ 293 TRNS_StpSt_FLT 1 "SNA";
VAL_ 464 DrvSbltUnFltr 0 "BUCKLED" 1 "UNBUCKLED" 2 "LOW" 3 "HIGH" 7 "SNA";
VAL_ 792 WprWash_R_Sw_Posn_V3 0 "OFF" 1 "INTERMITTENT" 2 "WASH" 3 "CONSTANT";
VAL_ 516 ControlEncodingRsp 16 "ControlEncoding_TEN" 153 "ControlEncoding_UC" 170 "ControlEncoding_PRA" 171 "ControlEncoding_PVA";
VAL_ 897 VC_HybridType 0 "NONE" 1 "BEV" 2 "HEV" 3 "PHEV" 4 "BSG48";
VAL_ 910 IBS3_TempFailStatus 0 "Fail_not_present" 1 "Fail_present";
VAL_ 910 IBS3_T_BATT 255 "SNA";
VAL_ 910 IBS3_SOH_Q_Accuracy 0 "Inaccurate" 1 "Accurate";
VAL_ 910 IBS3_SOH_Q 127 "SNA";
VAL_ 910 IBS3_SOF_VC 127 "SNA";
VAL_ 910 IBS3_SOF_V_Accuracy 0 "Inaccurate" 1 "Accurate";
VAL_ 910 IBS3_SOF_Q_Accuracy 0 "Inaccurate" 1 "Accurate";
VAL_ 910 IBS3_SOF_Q 255 "SNA";
VAL_ 910 IBS3_SOC_Accuracy 0 "Inaccurate" 1 "Accurate";
VAL_ 910 IBS3_SOC 127 "SNA";
VAL_ 910 IBS3_FLAG_DISCONNECT 0 "No_Disconnect" 1 "Disconnect";
VAL_ 517 ControlEncodingRq_205 5 "ControlEncoding_ENQ" 6 "ControlEncoding_ACK" 21 "ControlEncoding_NACK" 129 "ControlEncoding_NACKp" 132 "ControlEncoding_EOTp" 133 "ControlEncoding_ENQp" 134 "ControlEncoding_ACK1p" 135 "ControlEncoding_ACK2p";
VAL_ 976 PF_WARN_MSG 0 "PF_WARN" 1 "PF_WARN_REG_REQ" 2 "PF_WARN_REG_STRT" 3 "PF_WARN_REG_CMPT" 4 "PF_WARN_REG_SERV" 5 "PF_WARN_REG_PW_RED" 6 "PF_WARN_6" 7 "PF_WARN_7";
VAL_ 976 KNK_MG_TRIGGER 0 "LSPI_NO_MESSAGE" 1 "LSPI_LEVEL_1" 2 "LSPI_LEVEL_2" 3 "LSPI_LEVEL_3";

SIG_GROUP_ 464 ORC_A1_Pkt 1 : DRV_SEATBELT DrvSbltUnFltr;
SIG_GROUP_ 516 IMMO_CODE_RESPONSE_Pkt 1 : ControlEncodingRsp MKKey1org21 MKKey2org22 MKKey_3 MKKey_4 MKKey_5 MKKey_6;
SIG_GROUP_ 517 IMMO_CODE_REQUEST_Pkt 1 : rnd_1 rnd_2 rnd_3 rnd_4 f1_1 f1_2 ControlEncodingRq_205;
SIG_GROUP_ 47 WHEEL_SPEED_2_Pkt 1 : BrkPdlRawStat RAW_OBD_VEHACCEL_X;
SIG_GROUP_ 293 TRNS_STAT2_Pkt 1 : MIL_OnRq_TCM GS_NOTL FAN_RQ TX_TEMP TX_FAULT TransReadyForESS TRNS_StpSt_FLT;
SIG_GROUP_ 147 TRNS_STAT_Pkt 1 : PaddlesModeSts PRND_STAT EngStEnblRqTCM SHFT_PROG PRNDL_DISP SHFT_LOCK TxDisengaged PRNDL_Blink MC_TRNS_STAT CRC_TRNS_STAT;
SIG_GROUP_ 133 TRNS_SPD_Pkt 1 : K_STO_B Gr Gr_Target K_G_B K_O_B K_S_B Trns_EMCC_Achvd OUTPUT_SPEED N_Turb TCM_ManMd TRNS_SPD_MC;
SIG_GROUP_ 55 TCM_EngTrq2_Pkt 1 : EngTrqRq TrqCtrlModeRq MaxTrqDes MC_TCM_EngTrq2 CRC_TCM_EngTrq2;
SIG_GROUP_ 149 TCM_ENG_TRQ_Pkt 1 : Trans_Trq_Ratio TxIdleRq MC_TCM_ENG_TRQ CRC_TCM_ENG_TRQ REPRGD_PFC_CLR_TCM;
SIG_GROUP_ 171 TCM_A7_Pkt 1 : EngShutOffRq_TCM CurrentGear CurrentGearForDisplay TargetGear TX_WARN2 MC_TCM_A7 CRC_TCM_A7 WarmUpRq_NotAchieved;
SIG_GROUP_ 35 SCCM_STW_ANGL_STAT_Pkt 1 : LRW VLRW Pad_Shft MC_STW_Angle_STAT CRC_STW_Angle_STAT;
SIG_GROUP_ 177 SCCM_CrsCtrl_Pkt 1 : CrusCnclSwitch ACC_DistSwDec AcceleratorSts DeceleratorSts ResumeSwitch CruiseControlFailSts CruiseControlOnOffSts ACC_On ACC_DistSwInc SpeedLimiterOnOffSts MC_CSWC_1 CRC_CSWC_1;
